VERSION ""

NS_ :

BS_:

BU_: EOCM2B_IMX6_HS EOCM2A_IMX6_HS EOCM2B_K2_HS EOCM2A_K2_HS TTPM_HS AMM_HS EBOOST_OBD_HS CGM_HS BSM_HS HCP_B_HS AVM_HS PFAF_HS LVMPC_HS DCDC_HS DEFC_HS VPM_HS IPC_HS V2V_HS TCP_HS CSM_HS EOCM2B_K1_HS EOCM2A_K1_HS TRCM_HS ESCM_SP_HS ICCM_B_HS AMP_HS FICM_HS ARS_HS MCP_B_HS MCP_A_HS ICCM_OBD_HS SAS_HS ACCM_HS VLBS_HS EBCM_OBD_HS HCP_T_HS EDI_HS PLCM_HS VITM_OBD_HS VICM_HS HCP_HS APPS_HS ICCM_HS EOCM_F_HS GPCM_HS VCM_HS HMIM_HS VES_HS Dummy_HS MCP_C_HS ONSTAR_HS EPS_HS TestTool_HS MCP_HS BCP_HS ALC_HS AHL_AFL_HS SADS_HS EPB_HS FCM_HS TCCM_HS RDCM_HS PTO_HS EBCM_HS ACC_HS BCM_HS TCM_HS ECM_HS

VAL_TABLE_ vt_BooleanValues 1 "true" 0 "false" ;
VAL_TABLE_ BrkSysVTopSpdLimRqTp 3 "Unused and Reserved 2" 2 "Unused and Reserved 1" 1 "OBD" 0 "Inactive" ;
VAL_TABLE_ HzrdLmpActReqd 2 "Activate" 1 "Deactivate" 0 "No Action" ;
VAL_TABLE_ MtrBInvSt 7 "Unused and Reserved 3" 6 "Unused and Reserved 2" 5 "High Voltage Required" 4 "Unused and Reserved 1" 3 "Power Stage On: Active Discharge" 2 "Power Stage On: Shutdown Pending" 1 "Power Stage Active" 0 "Power Stage Inactive" ;
VAL_TABLE_ ValidityStates 1 "Invalid" 0 "Valid" ;
VAL_TABLE_ MtrAInvSt 7 "Unused and Reserved 3" 6 "Unused and Reserved 2" 5 "High Voltage Required" 4 "Unused and Reserved 1" 3 "Power Stage On: Active Discharge" 2 "Power Stage On: Shutdown Pending" 1 "Power Stage Active" 0 "Power Stage Inactive" ;
VAL_TABLE_ PrkHtrOffTmM 1 "Use Data" 0 "Dont Use Data" ;
VAL_TABLE_ PrkHtrCoolntTempMsk 1 "Use Data" 0 "Don't Use Data" ;
VAL_TABLE_ PrkHtrActvTmM 1 "Use Data" 0 "Dont Use Data" ;
VAL_TABLE_ CbnHtrWrmUpReq 3 "Warm Up Level 3" 2 "Warm Up Level 2" 1 "Warm Up Level 1" 0 "None" ;
VAL_TABLE_ ElcTrnsRngSelPrkSysStat 7 "Unused and Reserved 4" 6 "Unused and Reserved 3" 5 "Unused and Reserved 2" 4 "Unused and Reserved 1" 3 "Out Of Park" 2 "Transitional 1" 1 "Park" 0 "Unknown" ;
VAL_TABLE_ ClmCntHtrMinFlwRtRqVDA 1 "VirtualDeviceAvailable" 0 "VirtualDeviceUnavailable" ;
VAL_TABLE_ CCClntCrcFlwRtReqVDA 1 "VirtualDeviceAvailable" 0 "VirtualDeviceUnavailable" ;
VAL_TABLE_ CGMDS2_DTCStat 7 "Unused and Reserved3" 6 "Unused and Reserved2" 5 "Unused and Reserved1" 4 "Diagnostic Failed" 3 "Diagnostic Passed" 2 "No Status to Report" 1 "Critically Disabled" 0 "Not Supported" ;
VAL_TABLE_ CGMDS1_DTCStat 7 "Unused and Reserved3" 6 "Unused and Reserved2" 5 "Unused and Reserved1" 4 "Diagnostic Failed" 3 "Diagnostic Passed" 2 "No Status to Report" 1 "Critically Disabled" 0 "Not Supported" ;
VAL_TABLE_ CGMCII_DataIndx 31 "Unused and Reserved12" 30 "Unused and Reserved11" 29 "Unused and Reserved10" 28 "Unused and Reserved9" 27 "Unused and Reserved8" 26 "Unused and Reserved7" 25 "Unused and Reserved6" 24 "Unused and Reserved5" 23 "Unused and Reserved4" 22 "Unused and Reserved3" 21 "Unused and Reserved2" 20 "Unused and Reserved1" 19 "CVN Digit 4" 18 "CVN Digit 3" 17 "CVN Digit 2" 16 "CVN Digit 1" 15 "Calibration Identification Digit 16" 14 "Calibration Identification Digit 15" 13 "Calibration Identification Digit 14" 12 "Calibration Identification Digit 13" 11 "Calibration Identification Digit 12" 10 "Calibration Identification Digit 11" 9 "Calibration Identification Digit 10" 8 "Calibration Identification Digit 9" 7 "Calibration Identification Digit 8" 6 "Calibration Identification Digit 7" 5 "Calibration Identification Digit 6" 4 "Calibration Identification Digit 5" 3 "Calibration Identification Digit 4" 2 "Calibration Identification Digit 3" 1 "Calibration Identification Digit 2" 0 "Calibration Identification Digit 1" ;
VAL_TABLE_ CGMCII_DataStat 1 "Data Available" 0 "Data Not Available" ;
VAL_TABLE_ RdHVBatHtrCntctrStat 2 "Closed" 1 "Unused and Reserved" 0 "Open" ;
VAL_TABLE_ RdDCChrgCntctrStat 2 "Closed" 1 "Precharge" 0 "Open" ;
VAL_TABLE_ TrlrTrPrsSlLrnModeFdbkHrnReq 2 "Cancel Horn" 1 "Active" 0 "No Action" ;
VAL_TABLE_ TrlrTrPrsOvrgFdbkHrnReq 2 "Cancel Horn" 1 "Active" 0 "No Action" ;
VAL_TABLE_ TrlrTrPrsAdjmtErrFdbkHrnReq 2 "Cancel Horn" 1 "Active" 0 "No Action" ;
VAL_TABLE_ TrlrTrPrsAchvdFdbkHrnReq 2 "Cancel Horn" 1 "Active" 0 "No Action" ;
VAL_TABLE_ TrlrTrLrnStat 3 "Tires Not Learned" 2 "Learn Failed" 1 "Learn Progressing" 0 "Learn Completed" ;
VAL_TABLE_ TrlrTrLrnScsflFdbkHrnReq 2 "Cancel Horn" 1 "Active" 0 "No Action" ;
VAL_TABLE_ TrlrTrLrnModeFdbkHrnReq 2 "Cancel Horn" 1 "Active" 0 "No Action" ;
VAL_TABLE_ TrlrTrLrngAlLmpFlshFdbkReq 3 "Cancel Lights" 2 "Flash" 1 "Flash Once" 0 "No Action" ;
VAL_TABLE_ TrlrPrfDltn 5 "Profile 5 Deleted" 4 "Profile 4 Deleted" 3 "Profile 3 Deleted" 2 "Profile 2 Deleted" 1 "Profile 1 Deleted" 0 "No Profile Deleted" ;
VAL_TABLE_ TrlrTrRtRrPrsStat 8 "High Temp" 7 "High Pressure" 6 "Tire Learning Complete" 5 "Learn Tire" 4 "Learning in Progress" 3 "Malfunction" 2 "Low Pressure" 1 "Normal" 0 "Unknown" ;
VAL_TABLE_ TrlrTrRtFrtPrsStat 8 "High Temp" 7 "High Pressure" 6 "Tire Learning Complete" 5 "Learn Tire" 4 "Learning in Progress" 3 "Malfunction" 2 "Low Pressure" 1 "Normal" 0 "Unknown" ;
VAL_TABLE_ TrlrRtMdlPrsStat 8 "High Temp" 7 "High Pressure" 6 "Tire Learning Complete" 5 "Learn Tire" 4 "Learning in Progress" 3 "Malfunction" 2 "Low Pressure" 1 "Normal" 0 "Unknown" ;
VAL_TABLE_ TrlrTrLfRrPrsStat 8 "High Temp" 7 "High Pressure" 6 "Tire Learning Complete" 5 "Learn Tire" 4 "Learning in Progress" 3 "Malfunction" 2 "Low Pressure" 1 "Normal" 0 "Unknown" ;
VAL_TABLE_ TrlrTrLfMdlPrsStat 8 "High Temp" 7 "High Pressure" 6 "Tire Learning Complete" 5 "Learn Tire" 4 "Learning In Progress" 3 "Malfunction" 2 "Low Pressure" 1 "Normal" 0 "Unknown" ;
VAL_TABLE_ TrlrTrLfFrtPrsStat 8 "High Temp" 7 "High Pressure" 6 "Tire Learning Complete" 5 "Learn Tire" 4 "Learning In Progress" 3 "Malfunction" 2 "Low Pressure" 1 "Normal" 0 "Unknown" ;
VAL_TABLE_ TrlrProfSel 5 "Profile 5" 4 "Profile 4" 3 "Profile 3" 2 "Profile 2" 1 "Profile 1" 0 "Default Profile" ;
VAL_TABLE_ TrlrBrkProfStat 1 "Inactive" 0 "Active" ;
VAL_TABLE_ TrlrStTwHlMdOvrd 3 "Unused and Reserved 2" 2 "Unused and Reserved 1" 1 "Override to Not Tow Haul" 0 "No Override" ;
VAL_TABLE_ TransStCrwlMdOvrrd 3 "Unused And Reserved" 2 "Override To Crawl" 1 "Override To Not Crawl" 0 "No Override" ;
VAL_TABLE_ CrwlModeDndRsnIndReq 4 "Reduce Speed" 3 "Shift To 4 High" 2 "Brakes Overtemp" 1 "Unavailable" 0 "No Action" ;
VAL_TABLE_ BrkSysStCrwlModeOvrrd 3 "Unused And Reserved" 2 "Override To Crawl" 1 "Override To Not Crawl" 0 "No Override" ;
VAL_TABLE_ PAMS_SwStat 7 "Critical Analog Fault" 6 "Unused and Reserved 2" 5 "Unused and Reserved 1" 4 "Switch 4 Active" 3 "Switch 3 Active" 2 "Switch 2 Active" 1 "Switch 1 Active" 0 "No Active Switches" ;
VAL_TABLE_ ClmCntPrtyHtngRq 3 "HIGH" 2 "MEDIUM" 1 "LOW" 0 "NO ACTION" ;
VAL_TABLE_ RrAxlLckFdbk 2 "Unknown" 1 "Locked" 0 "Open" ;
VAL_TABLE_ AxlLckUnavailIndReq 7 "Unused And Reserved 2" 6 "Unused And Reserved 1" 5 "Generic Unavailable" 4 "Not During Hill Decent" 3 "Speed Too High" 2 "Not In 4 WD Low" 1 "Rear Axle Not Locked" 0 "No Action" ;
VAL_TABLE_ FrntAxlLckFdbk 2 "Unknown" 1 "Locked" 0 "Open" ;
VAL_TABLE_ EngIntAirTmpM 1 "Use Data" 0 "Dont Use Data" ;
VAL_TABLE_ RdHVCntctrShdwnCmd 4 "Normal Shutdown" 3 "Emergency Crash Shutdown" 2 "Controlled Shutdown" 1 "Emergency Shutdown" 0 "None" ;
VAL_TABLE_ RdChrgrCntctrStatus 2 "Closed" 1 "Precharge" 0 "Open" ;
VAL_TABLE_ CCFrBlwFnSpdFbkORLFS 2 "Fail" 1 "Pass" 0 "Indeterminate" ;
VAL_TABLE_ CCFrBlwFnSpdFbkORHFS 2 "Fail" 1 "Pass" 0 "Indeterminate" ;
VAL_TABLE_ TransTempOpRgn 7 "Unused and Reserved 3" 6 "Unused and Reserved 2" 5 "Unused and Reserved 1" 4 "Reliability Degraded" 3 "Operation Degraded" 2 "High Efficiency" 1 "Low Efficiency" 0 "Unknown" ;
VAL_TABLE_ TransOilTempAltValM 1 "Use Data" 0 "Dont Use Data" ;
VAL_TABLE_ FourWhlDrvIdReqExtRng 15 "Front Wheel Drive Mode Active" 14 "Front Wheel Drive Mode Pending" 13 "AWD Connected Mode Active" 12 "AWD Connected Mode Pending" 11 "Position Undetermined Active" 10 "Transfer Case Neutral Active" 9 "Transfer Case Neutral Pending" 8 "Four Wheel Drive Low Lock Active" 7 "Four Wheel Drive Low Lock Pending" 6 "Four Wheel Drive High Lock Active" 5 "Four Wheel Drive High Lock Pending" 4 "Four Wheel Drive High Auto Active" 3 "Four Wheel Drive High Auto Pending" 2 "Two Wheel Drive High Active" 1 "Two Wheel Drive High Pending" 0 "No Indication" ;
VAL_TABLE_ BrkPdLfSysDrvrRq 4 "Reset Rear" 3 "Reset Front" 2 "Enable" 1 "Disable" 0 "No Action" ;
VAL_TABLE_ BrkPdLfStatIndRq 5 "Service" 4 "Disabled" 3 "Change Now" 2 "Change Soon" 1 "Ok" 0 "Not Present" ;
VAL_TABLE_ BrkPdLfRrDstWrnIndRq 2 "Display Distance" 1 "Low" 0 "No Action" ;
VAL_TABLE_ BrkPdLfFrtDstWrnIndRq 2 "Display Distance" 1 "Low" 0 "No Action" ;
VAL_TABLE_ AutoVehMdSelctIntrStat 3 "Mode Request Denied" 2 "Disabled" 1 "Enabled" 0 "No Action" ;
VAL_TABLE_ AVMC_MdReqstd 31 "Critically Disabled" 30 "No Mode Change Requested" 29 "Unused and Reserved 16" 28 "Unused and Reserved 15" 27 "Unused and Reserved 14" 26 "Unused and Reserved 13" 25 "Unused and Reserved 12" 24 "Unused and Reserved 11" 23 "Unused and Reserved 10" 22 "Unused and Reserved 9" 21 "Unused and Reserved 8" 20 "Unused and Reserved 7" 19 "Unused and Reserved 6" 18 "Unused and Reserved 5" 17 "Unused and Reserved 4" 16 "Unused and Reserved 3" 15 "Unused and Reserved 2" 14 "Unused and Reserved 1" 13 "Normal AWD" 12 "Exhaust Brake" 11 "Track" 10 "Speed Matching" 9 "Grade Braking Disable" 8 "Tow Haul" 7 "Start Stop" 6 "Snow Ice" 5 "Hold" 4 "Mountain" 3 "Eco" 2 "Chassis Sport" 1 "Powertrain Sport" 0 "Normal" ;
VAL_TABLE_ EngAirFltMonSt 7 "Unused and Reserved 3" 6 "Unused and Reserved 2" 5 "Unused and Reserved 1" 4 "Disabled" 3 "Fault Present" 2 "Replace Air Filter Now" 1 "Replace Air Filter Soon" 0 "Ok" ;
VAL_TABLE_ EngAirFltMonDrvrReq 3 "Reset" 2 "Disable" 1 "Enable" 0 "No Action" ;
VAL_TABLE_ FuelMdTrnstnIndReq 15 "Unused and Reserved 9" 14 "Unused and Reserved 8" 13 "Unused and Reserved 7" 12 "Unused and Reserved 6" 11 "Unused and Reserved 5" 10 "Unused and Reserved 4" 9 "Unused and Reserved 3" 8 "Unused and Reserved 2" 7 "Unused and Reserved 1" 6 "Indication 6" 5 "Indication 5" 4 "Indication 4" 3 "Indication 3" 2 "Indication 2" 1 "Indication 1" 0 "No Indication" ;
VAL_TABLE_ BiFuelRflGaslinIndReq 7 "Unused and Reserved 5" 6 "Unused and Reserved 4" 5 "Unused and Reserved 3" 4 "Unused and Reserved 2" 3 "Unused and Reserved 1" 2 "Indication 2" 1 "Indication 1" 0 "No Indication" ;
VAL_TABLE_ SmrtHgBmAstCstCurrSetVal 7 "Unused and Reserved 5" 6 "Unused and Reserved 4" 5 "Unused and Reserved 3" 4 "Unused and Reserved 2" 3 "Unused and Reserved 1" 2 "Adaptive High Beam" 1 "Auto High Beam" 0 "No Action" ;
VAL_TABLE_ ACCAxlTrqReqStat 7 "Unused and Reserved 3" 6 "Unused and Reserved 2" 5 "Unused and Reserved 1" 4 "Request Suspended Until Driver Input" 3 "Request Denied" 2 "Lost Arbitration" 1 "Request Honored" 0 "No Request" ;
VAL_TABLE_ ElcShfPriTwoGrsSlInRq 3 "Drive Indication" 2 "Neutral Indication" 1 "Park Indication" 0 "No Indication" ;
VAL_TABLE_ VehStbEnhmntCurStRq 2 "On" 1 "Off" 0 "No Action" ;
VAL_TABLE_ VehStbEnhmntCurSt 1 "On" 0 "Off" ;
VAL_TABLE_ VehStbCmptvMdCurStRq 2 "On" 1 "Off" 0 "No Action" ;
VAL_TABLE_ VehStbCmptvMdCurSt 1 "On" 0 "Off" ;
VAL_TABLE_ TracAndStbScrnCnfg 3 "TCS ESC and Comp" 2 "TCS and ESC" 1 "TCS Only" 0 "None" ;
VAL_TABLE_ TCSysCurStReq 2 "On" 1 "Off" 0 "No Action" ;
VAL_TABLE_ TCSysCurSt 1 "On" 0 "Off" ;
VAL_TABLE_ TCSTmpSysDsblReqConf 2 "Yes" 1 "No" 0 "No Action" ;
VAL_TABLE_ SrndVisVltgStat 3 "Not Used" 2 "Out Of Range Low" 1 "Out Of Range High" 0 "In Range" ;
VAL_TABLE_ SrndVisTempStat 3 "Not Used" 2 "Out Of Range Low" 1 "Out Of Range High" 0 "In Range" ;
VAL_TABLE_ RghtLnMrkTyp 7 "Triple Line" 6 "Double Line" 5 "Road Edge" 4 "Virtual" 3 "Botts Dots" 2 "Dashed" 1 "Solid" 0 "Unknown" ;
VAL_TABLE_ RghtLnMrkConf 3 "High" 2 "Medium" 1 "Low 2" 0 "Low 1" ;
VAL_TABLE_ RghtLnMrkClr 7 "Unusued and Reserved 3" 6 "Unusued and Reserved 2" 5 "Unusued and Reserved 1" 4 "Blue" 3 "Red or Orange" 2 "Yellow" 1 "White" 0 "Unknown" ;
VAL_TABLE_ LnSensMdStat 1 "Sensing" 0 "Not Sensing" ;
VAL_TABLE_ LftLnMrkTyp 7 "Triple Line" 6 "Double Line" 5 "Road Edge" 4 "Virtual" 3 "Botts Dots" 2 "Dashed" 1 "Solid" 0 "Unknown" ;
VAL_TABLE_ LftLnMrkConf 3 "High" 2 "Medium" 1 "Low 2" 0 "Low 1" ;
VAL_TABLE_ LftLnMrkClr 7 "Unusued and Reserved 3" 6 "Unusued and Reserved 2" 5 "Unusued and Reserved 1" 4 "Blue" 3 "Red or Orange" 2 "Yellow" 1 "White" 0 "Unknown" ;
VAL_TABLE_ RTXCorrctnEnbl 1 "Enabled" 0 "Disabled" ;
VAL_TABLE_ PPSMd 7 "GNSS and RTX and DR and MM" 6 "DR ONLY" 5 "GNSS and RTX and DR" 4 "GNSS and SBAS and DR" 3 "GNSS and DR" 2 "GNSS and  RTX" 1 "GNSS and SBAS" 0 "GNSS Standalone" ;
VAL_TABLE_ DrvrDrOpenSwVDA 1 "Virtual Device Available" 0 "Virtual Device Unavailable" ;
VAL_TABLE_ DrvrDrAjrSwVDA 1 "Virtual Device Available" 0 "Virtual Device Unavailable" ;
VAL_TABLE_ TrnsEmisRlFrzFrmStrSt 3 "Reserved" 2 "Full" 1 "Pending" 0 "Empty" ;
VAL_TABLE_ RoadTypInfo 1 "Freeway" 0 "Non Freeway" ;
VAL_TABLE_ ESCMStrtStpStat 3 "Deactivated" 2 "Active" 1 "Inactive" 0 "Indeterminate" ;
VAL_TABLE_ ESCMSecPwrStat 3 "Deactivated" 2 "Active" 1 "Inactive" 0 "Indeterminate" ;
VAL_TABLE_ ESCMChrgSysSt 3 "Reserved" 2 "Discharging" 1 "Charging" 0 "Passive" ;
VAL_TABLE_ ABRS_BcupESCDatInpSt 1 "Failed" 0 "Normal" ;
VAL_TABLE_ ABRS_ACCAutBkRqPrBsSt 7 "Not Used 2" 6 "Not Used 1" 5 "Request Out Of Range" 4 "CAN Error" 3 "Failed" 2 "Limited" 1 "Active" 0 "Not Active" ;
VAL_TABLE_ ABRS_CIBAutBkRqScBsSt 7 "Not Used 2" 6 "Not Used 1" 5 "Request Out Of Range" 4 "CAN Error" 3 "Failed" 2 "Limited" 1 "Active" 0 "Not Active" ;
VAL_TABLE_ DTPWCPS_CrnkPrm 1 "Crank Permitted" 0 "Crank Not Permitted" ;
VAL_TABLE_ HybEstTransOilTmpM 1 "Use Data" 0 "Dont Use Data" ;
VAL_TABLE_ ACCSysSltdMd 3 "Unused And Reserved" 2 "Enhanced Cruise Control" 1 "Adaptive Cruise Control" 0 "Cruise Control Mode Switching Not Supported" ;
VAL_TABLE_ PTExPartFltManRegStat 7 "Unused and Reserved 2" 6 "Unused and Reserved 1" 5 "Pending Driver Input" 4 "Complete" 3 "In Progress" 2 "Not Allowed" 1 "Allowed" 0 "Cleaning Not Required" ;
VAL_TABLE_ TransCltch5CntlRq 3 "Locked" 2 "Passive Control" 1 "Active Control" 0 "No Control" ;
VAL_TABLE_ TransCltch4CntlRq 3 "Locked" 2 "Passive Control" 1 "Active Control" 0 "No Control" ;
VAL_TABLE_ TransCltch3CntlRq 3 "Locked" 2 "Passive Control" 1 "Active Control" 0 "No Control" ;
VAL_TABLE_ TransCltch2CntlRq 3 "Locked" 2 "Passive Control" 1 "Active Control" 0 "No Control" ;
VAL_TABLE_ TransCltch1CntlRq 3 "Locked" 2 "Passive Control" 1 "Active Control" 0 "No Control" ;
VAL_TABLE_ LnchCtrlWhlSlpStat 31 "Unused and Reserved 10" 30 "Unused and Reserved 9" 29 "Unused and Reserved 8" 28 "Unused and Reserved 7" 27 "Unused and Reserved 6" 26 "Unused and Reserved 5" 25 "Unused and Reserved 4" 24 "Unused and Reserved 3" 23 "Unused and Reserved 2" 22 "Unused and Reserved 1" 21 "Fifteen Percent" 20 "Fourteen And A Half Percent" 19 "Fourteen Percent" 18 "Thirteen And A Half Percent" 17 "Thirteen Percent" 16 "Twelve And A Half Percent" 15 "Twelve Percent" 14 "Eleven And a Half Percent" 13 "Eleven Percent" 12 "Ten And A Half Percent" 11 "Ten Percent" 10 "Nine And A Half Percent" 9 "Nine Percent" 8 "Eight And A Half Percent" 7 "Eight Percent" 6 "Seven And A Half Percent" 5 "Seven Percent" 4 "Six And A Half Percent" 3 "Six Percent" 2 "Five And A Half Percent" 1 "Five Percent" 0 "No Action" ;
VAL_TABLE_ LnchCtrlWhlSlpReq 31 "Unused and Reserved 10" 30 "Unused and Reserved 9" 29 "Unused and Reserved 8" 28 "Unused and Reserved 7" 27 "Unused and Reserved 6" 26 "Unused and Reserved 5" 25 "Unused and Reserved 4" 24 "Unused and Reserved 3" 23 "Unused and Reserved 2" 22 "Unused and Reserved 1" 21 "Fifteen Percent" 20 "Fourteen And A Half Percent" 19 "Fourteen Percent" 18 "Thirteen And A Half Percent" 17 "Thirteen Percent" 16 "Twelve And A Half Percent" 15 "Twelve Percent" 14 "Eleven And a Half Percent" 13 "Eleven Percent" 12 "Ten And A Half Percent" 11 "Ten Percent" 10 "Nine And A Half Percent" 9 "Nine Percent" 8 "Eight And A Half Percent" 7 "Eight Percent" 6 "Seven And A Half Percent" 5 "Seven Percent" 4 "Six And A Half Percent" 3 "Six Percent" 2 "Five And A Half Percent" 1 "Five Percent" 0 "No Action" ;
VAL_TABLE_ LnchCtrlMdStat 7 "Line Lock Release Brake" 6 "Line Lock Press Brake" 5 "Burn Out Or Line Lock" 4 "High Traction Custom" 3 "High Traction" 2 "General Custom" 1 "General" 0 "Disable" ;
VAL_TABLE_ LnchCtrlMdReq 3 "Burn Out" 2 "Custom" 1 "Automatic" 0 "No Action" ;
VAL_TABLE_ LnchCtrlEngRPMStat 0 "No Action" 63 "Unused and Reserved 30" 62 "Unused and Reserved 29" 61 "Unused and Reserved 28" 60 "Unused and Reserved 27" 59 "Unused and Reserved 26" 58 "Unused and Reserved 25" 57 "Unused and Reserved 24" 56 "Unused and Reserved 23" 55 "Unused and Reserved 22" 54 "Unused and Reserved 21" 53 "Unused and Reserved 20" 52 "Unused and Reserved 19" 51 "Unused and Reserved 18" 50 "Unused and Reserved 17" 49 "Unused and Reserved 16" 48 "Unused and Reserved 15" 47 "Unused and Reserved 14" 46 "Unused and Reserved 13" 45 "Unused and Reserved 12" 44 "Unused and Reserved 11" 43 "Unused and Reserved 10" 42 "Unused and Reserved 9" 41 "Unused and Reserved 8" 40 "Unused and Reserved 7" 39 "Unused and Reserved 6" 38 "Unused and Reserved 5" 37 "Unused and Reserved 4" 36 "Unused and Reserved 3" 35 "Unused and Reserved 2" 34 "Unused and Reserved 1" 33 "4000" 32 "3900" 31 "3800" 30 "3700" 29 "3600" 28 "3500" 27 "3400" 26 "3300" 25 "3200" 24 "3100" 23 "3000" 22 "2900" 21 "2800" 20 "2700" 19 "2600" 18 "2500" 17 "2400" 16 "2300" 15 "2200" 14 "2100" 13 "2000" 12 "1900" 11 "1800" 10 "1700" 9 "1600" 8 "1500" 7 "1400" 6 "1300" 5 "1200" 4 "1100" 3 "1000" 2 "900" 1 "800" ;
VAL_TABLE_ LnchCtrlEngRPMReq 63 "Unused and Reserved 30" 62 "Unused and Reserved 29" 61 "Unused and Reserved 28" 60 "Unused and Reserved 27" 59 "Unused and Reserved 26" 58 "Unused and Reserved 25" 57 "Unused and Reserved 24" 56 "Unused and Reserved 23" 55 "Unused and Reserved 22" 54 "Unused and Reserved 21" 53 "Unused and Reserved 20" 52 "Unused and Reserved 19" 51 "Unused and Reserved 18" 50 "Unused and Reserved 17" 49 "Unused and Reserved 16" 48 "Unused and Reserved 15" 47 "Unused and Reserved 14" 46 "Unused and Reserved 13" 45 "Unused and Reserved 12" 44 "Unused and Reserved 11" 43 "Unused and Reserved 10" 42 "Unused and Reserved 9" 41 "Unused and Reserved 8" 40 "Unused and Reserved 7" 39 "Unused and Reserved 6" 38 "Unused and Reserved 5" 37 "Unused and Reserved 4" 36 "Unused and Reserved 3" 35 "Unused and Reserved 2" 34 "Unused and Reserved 1" 33 "4000" 32 "3900" 31 "3800" 30 "3700" 29 "3600" 28 "3500" 27 "3400" 26 "3300" 25 "3200" 24 "3100" 23 "3000" 22 "2900" 21 "2800" 20 "2700" 19 "2600" 18 "2500" 17 "2400" 16 "2300" 15 "2200" 14 "2100" 13 "2000" 12 "1900" 11 "1800" 10 "1700" 9 "1600" 8 "1500" 7 "1400" 6 "1300" 5 "1200" 4 "1100" 3 "1000" 2 "900" 1 "800" 0 "No Action" ;
VAL_TABLE_ TrqOvrlStatSrc 7 "Unused And Reserved3" 6 "Unused And Reserved2" 5 "Unused And Reserved1" 4 "Secondary EOCM Secondary Network" 3 "Secondary EOCM Primary Network" 2 "Primary EOCM Secondary Network" 1 "Primary EOCM Primary Network" 0 "None" ;
VAL_TABLE_ StrngTrqOvrlTrqDStat 7 "EPS Override" 6 "Permanently Failed" 5 "Limited System Capability" 4 "Communication Error" 3 "Temporarily Limited" 2 "Deactivated" 1 "Active" 0 "Inactive" ;
VAL_TABLE_ HndsOffStrWhlDetmnStat 1 "Hands On" 0 "Hands Off" ;
VAL_TABLE_ HndsOffStrWhlDetmnMd 3 "Unused And Reserved" 2 "Failed" 1 "Enabled" 0 "Disabled" ;
VAL_TABLE_ EPSCmndTrqValFetr 7 "Unused and Reserved 2" 6 "Unused and Reserved 1" 5 "Reserved for Collision Imminent Steering" 4 "Steering Angle Assist" 3 "Reserved for LXC" 2 "Lane Centering Control" 1 "Lane Keep Assist" 0 "None" ;
VAL_TABLE_ EPSCmndCtlTyp 3 "Unused" 2 "Dual Overlay" 1 "Single Overlay" 0 "Inactive" ;
VAL_TABLE_ EPSCmdTrqReqAct 1 "Active" 0 "Inactive" ;
VAL_TABLE_ TARS_TransActRngM 1 "Use Data" 0 "Do not Use Data" ;
VAL_TABLE_ TARS_TransActRng 15 "Unused and Reserved2" 14 "Unused and Reserved1" 13 "Fourth Drive Position" 12 "Between Third and Fourth Drive position" 11 "Third Drive Position" 10 "Between Second and Third Drive position" 9 "Second Drive Position" 8 "Between First and Second Drive position" 7 "First Drive Position" 6 "Between Neutral and First Drive position" 5 "Neutral Position" 4 "Between Reverse and Neutral" 3 "Reverse Position" 2 "Between Park and Reverse" 1 "Park Position" 0 "Unknown Position" ;
VAL_TABLE_ PRS_PTRlyCmdSt 1 "Relay On" 0 "Relay Off" ;
VAL_TABLE_ ChrgSysAudblIndRq 7 "Unused and Reserved3" 6 "Unused and Reserved2" 5 "Unused and Reserved1" 4 "Sequence 4" 3 "Sequence 3" 2 "Sequence 2" 1 "Sequence 1" 0 "Inactive" ;
VAL_TABLE_ EngPstnSnsngOpMode 2 "CAM Failed" 1 "Crank Failed" 0 "Normal" ;
VAL_TABLE_ EASSI_StrtTyp 7 "Type G" 6 "Type F" 5 "Type E" 4 "Type D" 3 "Type C" 2 "Type B" 1 "Type A" 0 "No Start" ;
VAL_TABLE_ EASSI_StrtStpSt 3 "Engine Stopping" 2 "Engine Starting" 1 "Engine Running" 0 "Engine Off" ;
VAL_TABLE_ TEPI_TrnsEngdPrFlwSt 7 "Unused and Reserved4" 6 "Unused and Reserved3" 5 "Unused and Reserved2" 4 "Unused and Reserved1" 3 "Reverse Engaged" 2 "Drive Engaged" 1 "No Powerflow" 0 "Unavailable " ;
VAL_TABLE_ ElcTransRngRq 7 "Unused and Reserved" 6 "Manual Range" 5 "Low Range" 4 "Drive" 3 "Neutral" 2 "Reverse" 1 "Park" 0 "No Request" ;
VAL_TABLE_ ESBR_AutoBrkgRqTyp 3 "Unused and Reserved" 2 "Hold Deny Driver Release" 1 "Hold Allow Driver Release" 0 "Release" ;
VAL_TABLE_ ESBR_AutoBrkgRqd 1 "Braking Requested" 0 "Braking Not Requested " ;
VAL_TABLE_ PndgTrnsfrCsRngShft 3 "Shift Out of Neutral Range" 2 "Shift Out of Low Range" 1 "Shift Out of High Range" 0 "None" ;
VAL_TABLE_ EngDetPndTrnCsRngShf 3 "Shift Out of Neutral Range" 2 "Shift Out of Low Range" 1 "Shift Out of High Range" 0 "None" ;
VAL_TABLE_ ElecShfRngDisp 15 "Unused and Reserved 3" 14 "Unused and Reserved 2" 13 "Unused and Reserved 1" 12 "Park Requested And Denied" 11 "Drive Requested And In Progress" 10 "Neutral Requested And In Progress" 9 "Reverse Requested And In Progress" 8 "Park Requested And In Progress" 7 "Reserved" 6 "Manual Nominal" 5 "Low Nominal" 4 "Drive Nominal" 3 "Neutral Nominal" 2 "Reverse Nominal" 1 "Park Nominal" 0 "No Display " ;
VAL_TABLE_ AVHSwtchStats 1 "Active" 0 "Not Active" ;
VAL_TABLE_ ThrmlRefCompStatFdbck 3 "Invalid" 2 "Inoperative" 1 "Degraded Operation" 0 "Normal Operation" ;
VAL_TABLE_ ManTransIndReq 3 "Indication 3" 2 "Indication 2" 1 "Indication 1" 0 "No Indication" ;
VAL_TABLE_ BCS2ERDTC_SysDesigntr 15 "U3-Network Codes Reserved" 14 "U2-Network Codes Reserved" 13 "U1-Network Codes MFG Controlled" 12 "U0-Network Codes SAE Controlled" 11 "B3-Body Codes Reserved" 10 "B2-Body Codes Reserved" 9 "B1-Body Codes MFG Controlled" 8 "B0-Body Codes SAE Controlled" 7 "C3-Chassis Codes Reserved" 6 "C2-Chassis Codes Reserved" 5 "C1-Chassis Codes MFG Controlled" 4 "C0-Chassis Codes SAE Controlled" 3 "P3-Powertrain Codes Reserved" 2 "P2-Powertrain Codes Reserved" 1 "P1-Powertrain Codes MFG Controlled" 0 "P0-Powertrain Codes SAE Controlled" ;
VAL_TABLE_ BCS1ERDTC_SysDesigntr 15 "U3-Network Codes Reserved" 14 "U2-Network Codes Reserved" 13 "U1-Network Codes MFG Controlled" 12 "U0-Network Codes SAE Controlled" 11 "B3-Body Codes Reserved" 10 "B2-Body Codes Reserved" 9 "B1-Body Codes MFG Controlled" 8 "B0-Body Codes SAE Controlled" 7 "C3-Chassis Codes Reserved" 6 "C2-Chassis Codes Reserved" 5 "C1-Chassis Codes MFG Controlled" 4 "C0-Chassis Codes SAE Controlled" 3 "P3-Powertrain Codes Reserved" 2 "P2-Powertrain Codes Reserved" 1 "P1-Powertrain Codes MFG Controlled" 0 "P0-Powertrain Codes SAE Controlled" ;
VAL_TABLE_ TIDCTR_TrqIntvTyp 3 "Reserved" 2 "Minimum Limit" 1 "Maximum Limit" 0 "No Request" ;
VAL_TABLE_ TIDCTR_TrqRespTyp 3 "Automatic Actuator Selection" 2 "Maximum Range" 1 "Pleasability Limited" 0 "Inactive" ;
VAL_TABLE_ ExtHlStrAssCsStRq 2 "Standard Hold" 1 "Extended Hold" 0 "No Action" ;
VAL_TABLE_ ExtHlStrAssCsCrStVal 2 "Standard Hold" 1 "Extended Hold" 0 "No Action" ;
VAL_TABLE_ BSMCT_Mult 3 "Multiplier Factor 256" 2 "Multiplier Factor 64" 1 "Multiplier Factor 8" 0 "Multiplier Factor 1" ;
VAL_TABLE_ CDP_HVDevShtdnCdARCSt 2 "Indeterminate" 1 "Fault" 0 "No Fault" ;
VAL_TABLE_ CDP_CmpSpdReqARCSt 2 "Indeterminate" 1 "Fault" 0 "No Fault" ;
VAL_TABLE_ CDSP_CmpOvrTmpSt 2 "Indeterminate" 1 "Fault" 0 "No Fault" ;
VAL_TABLE_ CDSP_CmpHVAbnrlOrVltSt 2 "Indeterminate" 1 "Fault" 0 "No Fault" ;
VAL_TABLE_ CDSP_CmpHVUndrVltgSt 2 "Indeterminate" 1 "Fault" 0 "No Fault" ;
VAL_TABLE_ CDSP_CmpHVOvrVltgSt 2 "Indeterminate" 1 "Fault" 0 "No Fault" ;
VAL_TABLE_ CDSP_CmpHVOvrCrntSt 2 "Indeterminate" 1 "Fault" 0 "No Fault" ;
VAL_TABLE_ CDSP_CmpIntShdwnFltSt 2 "Indeterminate" 1 "Fault" 0 "No Fault" ;
VAL_TABLE_ CDSP_CmpIntRecblFltSt 2 "Indeterminate" 1 "Fault" 0 "No Fault" ;
VAL_TABLE_ CDSP_CmpOpOvrldSt 2 "Indeterminate" 1 "Fault" 0 "No Fault" ;
VAL_TABLE_ CDSP_CmpDrCrctFltSt 2 "Indeterminate" 1 "Fault" 0 "No Fault" ;
VAL_TABLE_ CDSP_CmpMtrPerfFltSt 2 "Indeterminate" 1 "Fault" 0 "No Fault" ;
VAL_TABLE_ CDSP_CmpEEPROMFltSt 2 "Indeterminate" 1 "Fault" 0 "No Fault" ;
VAL_TABLE_ CDSP_CmpROMFltSt 2 "Indeterminate" 1 "Fault" 0 "No Fault" ;
VAL_TABLE_ CDSP_CmpRAMFltSt 2 "Indeterminate" 1 "Fault" 0 "No Fault" ;
VAL_TABLE_ CSSP_CmpIGBTTpOtRgLSt 2 "Indeterminate" 1 "Fault" 0 "No Fault" ;
VAL_TABLE_ CSSP_CmpIGBTTpOtRgHSt 2 "Indeterminate" 1 "Fault" 0 "No Fault" ;
VAL_TABLE_ CSSP_CmpCPUTmpOtRgLSt 2 "Indeterminate" 1 "Fault" 0 "No Fault" ;
VAL_TABLE_ CSSP_CmpCPUTmpOtRgHSt 2 "Indeterminate" 1 "Fault" 0 "No Fault" ;
VAL_TABLE_ CSSP_CmpHVSnsOtRgLSt 2 "Indeterminate" 1 "Fault" 0 "No Fault" ;
VAL_TABLE_ CSSP_CmpHVSnsOtRgHSt 2 "Indeterminate" 1 "Fault" 0 "No Fault" ;
VAL_TABLE_ CSSP_CmpPhCrntOtRgLSt 2 "Indeterminate" 1 "Fault" 0 "No Fault" ;
VAL_TABLE_ CSSP_CmpPhCrntOtRgHSt 2 "Indeterminate" 1 "Fault" 0 "No Fault" ;
VAL_TABLE_ PrtdEPBSwStat 3 "Active" 2 "Apply" 1 "Release" 0 "Not Active" ;
VAL_TABLE_ EBrkAstStat 7 "Faulted" 6 "Temporarily Failed" 5 "Reduced" 4 "Standalone" 3 "PostRun Reduced" 2 "Normal" 1 "Initializing" 0 "Not Initialized" ;
VAL_TABLE_ AdptCruzCtrlStg 7 "Performance Mode 7" 6 "Performance Mode 6" 5 "Performance Mode 5" 4 "Performance Mode 4" 3 "Performance Mode 3" 2 "Performance Mode 2" 1 "Performance Mode 1" 0 "No Action" ;
VAL_TABLE_ GFHBObjDirTrk8 1 "Ahead Traffic" 0 "Incoming Traffic" ;
VAL_TABLE_ GFHBObjDirTrk7 1 "Ahead Traffic" 0 "Incoming Traffic" ;
VAL_TABLE_ GFHBObjDirTrk6 1 "Ahead Traffic" 0 "Incoming Traffic" ;
VAL_TABLE_ GFHBObjDirTrk5 1 "Ahead Traffic" 0 "Incoming Traffic" ;
VAL_TABLE_ GFHBObjDirTrk4 1 "Ahead Traffic" 0 "Incoming Traffic" ;
VAL_TABLE_ GFHBObjDirTrk3 1 "Ahead Traffic" 0 "Incoming Traffic" ;
VAL_TABLE_ GFHBObjDirTrk2 1 "Ahead Traffic" 0 "Incoming Traffic" ;
VAL_TABLE_ GFHBObjDirTrk1 1 "Ahead Traffic" 0 "Incoming Traffic" ;
VAL_TABLE_ GFHBFwVsnRelLaneTrk8 3 "Left Lane" 2 "Right Lane" 1 "Host Lane" 0 "Unknown" ;
VAL_TABLE_ GFHBFwVsnRelLaneTrk7 3 "Left Lane" 2 "Right Lane" 1 "Host Lane" 0 "Unknown" ;
VAL_TABLE_ GFHBFwVsnRelLaneTrk6 3 "Left Lane" 2 "Right Lane" 1 "Host Lane" 0 "Unknown" ;
VAL_TABLE_ GFHBFwVsnRelLaneTrk5 3 "Left Lane" 2 "Right Lane" 1 "Host Lane" 0 "Unknown" ;
VAL_TABLE_ GFHBFwVsnRelLaneTrk4 3 "Left Lane" 2 "Right Lane" 1 "Host Lane" 0 "Unknown" ;
VAL_TABLE_ GFHBFwVsnRelLaneTrk3 3 "Left Lane" 2 "Right Lane" 1 "Host Lane" 0 "Unknown" ;
VAL_TABLE_ GFHBFwVsnRelLaneTrk2 3 "Left Lane" 2 "Right Lane" 1 "Host Lane" 0 "Unknown" ;
VAL_TABLE_ GFHBFwVsnRelLaneTrk1 3 "Left Lane" 2 "Right Lane" 1 "Host Lane" 0 "Unknown" ;
VAL_TABLE_ GFHBFwVsnMesStatTrk8 3 "Measured this cycle" 2 "Latent track not detected this cycle" 1 "New Object" 0 "No Object" ;
VAL_TABLE_ GFHBFwVsnMesStatTrk7 3 "Measured this cycle" 2 "Latent track not detected this cycle" 1 "New Object" 0 "No Object" ;
VAL_TABLE_ GFHBFwVsnMesStatTrk6 3 "Measured this cycle" 2 "Latent track not detected this cycle" 1 "New Object" 0 "No Object" ;
VAL_TABLE_ GFHBFwVsnMesStatTrk5 3 "Measured this cycle" 2 "Latent track not detected this cycle" 1 "New Object" 0 "No Object" ;
VAL_TABLE_ GFHBFwVsnMesStatTrk4 3 "Measured this cycle" 2 "Latent track not detected this cycle" 1 "New Object" 0 "No Object" ;
VAL_TABLE_ GFHBFwVsnMesStatTrk3 3 "Measured this cycle" 2 "Latent track not detected this cycle" 1 "New Object" 0 "No Object" ;
VAL_TABLE_ GFHBFwVsnMesStatTrk2 3 "Measured this cycle" 2 "Latent track not detected this cycle" 1 "New Object" 0 "No Object" ;
VAL_TABLE_ GFHBFwVsnMesStatTrk1 3 "Measured this cycle" 2 "Latent track not detected this cycle" 1 "New Object" 0 "No Object" ;
VAL_TABLE_ GFHBFwVsnCnfdncTrk8 3 "Confident" 2 "Speculative" 1 "Highly Speculative" 0 "Invalid" ;
VAL_TABLE_ GFHBFwVsnCnfdncTrk7 3 "Confident" 2 "Speculative" 1 "Highly Speculative" 0 "Invalid" ;
VAL_TABLE_ GFHBFwVsnCnfdncTrk6 3 "Confident" 2 "Speculative" 1 "Highly Speculative" 0 "Invalid" ;
VAL_TABLE_ GFHBFwVsnCnfdncTrk5 3 "Confident" 2 "Speculative" 1 "Highly Speculative" 0 "Invalid" ;
VAL_TABLE_ GFHBFwVsnCnfdncTrk4 3 "Confident" 2 "Speculative" 1 "Highly Speculative" 0 "Invalid" ;
VAL_TABLE_ GFHBFwVsnCnfdncTrk3 3 "Confident" 2 "Speculative" 1 "Highly Speculative" 0 "Invalid" ;
VAL_TABLE_ GFHBFwVsnCnfdncTrk2 3 "Confident" 2 "Speculative" 1 "Highly Speculative" 0 "Invalid" ;
VAL_TABLE_ GFHBFwVsnCnfdncTrk1 0 "Invalid" 3 "Confident" 2 "Speculative" 1 "Highly Speculative" ;
VAL_TABLE_ GFHBFVsnObjTypTrkRev8 12 "Cluster Object" 11 "Child Close to Danger Zone" 10 "Pedestrian Moving Out of Danger Zone" 9 "Pedestrian Moving Into Danger Zone" 8 "Pedestrian Standing Outside Danger Zone" 7 "No Object Present" 6 "Fixed Roadside Object" 5 "Fixed Overhead Object" 4 "Pedestrian" 3 "Motorcycle/ Bicycle" 2 "Large Vehicle (Semi)" 1 "4 Wheel Vehicle (Car)" 0 "Unknown" ;
VAL_TABLE_ GFHBFVsnObjTypTrkRev7 12 "Cluster Object" 11 "Child Close to Danger Zone" 10 "Pedestrian Moving Out of Danger Zone" 9 "Pedestrian Moving Into Danger Zone" 8 "Pedestrian Standing Outside Danger Zone" 7 "No Object Present" 6 "Fixed Roadside Object" 5 "Fixed Overhead Object" 4 "Pedestrian" 3 "Motorcycle/ Bicycle" 2 "Large Vehicle (Semi)" 1 "4 Wheel Vehicle (Car)" 0 "Unknown" ;
VAL_TABLE_ GFHBFVsnObjTypTrkRev6 12 "Cluster Object" 11 "Child Close to Danger Zone" 10 "Pedestrian Moving Out of Danger Zone" 9 "Pedestrian Moving Into Danger Zone" 8 "Pedestrian Standing Outside Danger Zone" 7 "No Object Present" 6 "Fixed Roadside Object" 5 "Fixed Overhead Object" 4 "Pedestrian" 3 "Motorcycle/ Bicycle" 2 "Large Vehicle (Semi)" 1 "4 Wheel Vehicle (Car)" 0 "Unknown" ;
VAL_TABLE_ GFHBFVsnObjTypTrkRev5 12 "Cluster Object" 11 "Child Close to Danger Zone" 10 "Pedestrian Moving Out of Danger Zone" 9 "Pedestrian Moving Into Danger Zone" 8 "Pedestrian Standing Outside Danger Zone" 7 "No Object Present" 6 "Fixed Roadside Object" 5 "Fixed Overhead Object" 4 "Pedestrian" 3 "Motorcycle/ Bicycle" 2 "Large Vehicle (Semi)" 1 "4 Wheel Vehicle (Car)" 0 "Unknown" ;
VAL_TABLE_ GFHBFVsnObjTypTrkRev4 12 "Cluster Object" 11 "Child Close to Danger Zone" 10 "Pedestrian Moving Out of Danger Zone" 9 "Pedestrian Moving Into Danger Zone" 8 "Pedestrian Standing Outside Danger Zone" 7 "No Object Present" 6 "Fixed Roadside Object" 5 "Fixed Overhead Object" 4 "Pedestrian" 3 "Motorcycle/ Bicycle" 2 "Large Vehicle (Semi)" 1 "4 Wheel Vehicle (Car)" 0 "Unknown" ;
VAL_TABLE_ GFHBFVsnObjTypTrkRev3 12 "Cluster Object" 11 "Child Close to Danger Zone" 10 "Pedestrian Moving Out of Danger Zone" 9 "Pedestrian Moving Into Danger Zone" 8 "Pedestrian Standing Outside Danger Zone" 7 "No Object Present" 6 "Fixed Roadside Object" 5 "Fixed Overhead Object" 4 "Pedestrian" 3 "Motorcycle/ Bicycle" 2 "Large Vehicle (Semi)" 1 "4 Wheel Vehicle (Car)" 0 "Unknown" ;
VAL_TABLE_ GFHBFVsnObjTypTrkRev2 12 "Cluster Object" 11 "Child Close to Danger Zone" 10 "Pedestrian Moving Out of Danger Zone" 9 "Pedestrian Moving Into Danger Zone" 8 "Pedestrian Standing Outside Danger Zone" 7 "No Object Present" 6 "Fixed Roadside Object" 5 "Fixed Overhead Object" 4 "Pedestrian" 3 "Motorcycle/ Bicycle" 2 "Large Vehicle (Semi)" 1 "4 Wheel Vehicle (Car)" 0 "Unknown" ;
VAL_TABLE_ GFHBFVsnObjTypTrkRev1 12 "Cluster Object" 11 "Child Close to Danger Zone" 10 "Pedestrian Moving Out of Danger Zone" 9 "Pedestrian Moving Into Danger Zone" 8 "Pedestrian Standing Outside Danger Zone" 7 "No Object Present" 6 "Fixed Roadside Object" 5 "Fixed Overhead Object" 4 "Pedestrian" 3 "Motorcycle/ Bicycle" 2 "Large Vehicle (Semi)" 1 "4 Wheel Vehicle (Car" 0 "Unknown" ;
VAL_TABLE_ SpdLmtrSttngTypAct 3 "Reserved" 2 "Auto" 1 "Manual" 0 "Off" ;
VAL_TABLE_ SetSpdLmtRchd 3 "Reserved" 2 "Low limit reached" 1 "High limit reached" 0 "No limit reached" ;
VAL_TABLE_ HybCrpCstCrvRq 7 "Creep Coast Curve 7" 6 "Creep Coast Curve 6" 5 "Creep Coast Curve 5" 4 "Creep Coast Curve 4" 3 "Creep Coast Curve 3" 2 "Creep Coast Curve 2" 1 "Creep Coast Curve 1" 0 "Creep Coast Curve 0" ;
VAL_TABLE_ CrpCstCrvCmd 7 "Creep Coast Curve 7" 6 "Creep Coast Curve 6" 5 "Creep Coast Curve 5" 4 "Creep Coast Curve 4" 3 "Creep Coast Curve 3" 2 "Creep Coast Curve 2" 1 "Creep Coast Curve 1" 0 "Creep Coast Curve 0" ;
VAL_TABLE_ RdGasFuelDevDisStat 3 "Reserved" 2 "Fault" 1 "Not Faulted" 0 "Indeterminate" ;
VAL_TABLE_ RdDistFuelMdReq 5 "Fault Transition Required" 4 "Fault Transition Requested" 3 "FICM" 2 "Dual" 1 "ECM" 0 "Indeterminate" ;
VAL_TABLE_ RdDistFuelMdCmdRes 3 "FICM" 2 "Dual" 1 "ECM" 0 "Indeterminate" ;
VAL_TABLE_ RdAltFuelSysStat 3 "Reserved" 2 "Fuel System Ready" 1 "Fuel System Priming" 0 "Fuel System Inactive" ;
VAL_TABLE_ RdDistFuelMdCmd 3 "FICM" 2 "Dual" 1 "ECM" 0 "Indeterminate" ;
VAL_TABLE_ PetrolFuelSysReqAval 3 "Not Available" 2 "Fault Transition Required" 1 "Fault Transition Requests" 0 "Available" ;
VAL_TABLE_ AltFuelInjHCmdLwRes 1 "FICM" 0 "ECM" ;
VAL_TABLE_ AltFuelInjGCmdLwRes 1 "FICM" 0 "ECM" ;
VAL_TABLE_ AltFuelInjFCmdLwRes 1 "FICM" 0 "ECM" ;
VAL_TABLE_ AltFuelInjECmdLwRes 1 "FICM" 0 "ECM" ;
VAL_TABLE_ AltFuelInjDCmdLwRes 1 "FICM" 0 "ECM" ;
VAL_TABLE_ AltFuelInjCCmdLwRes 1 "FICM" 0 "ECM" ;
VAL_TABLE_ AltFuelInjBCmdLwRes 1 "FICM" 0 "ECM" ;
VAL_TABLE_ AltFuelInjACmdLwRes 1 "FICM" 0 "ECM" ;
VAL_TABLE_ AdptPsngrSeatStng 7 "Performance Mode 7" 6 "Performance Mode 6" 5 "Performance Mode 5" 4 "Performance Mode 4" 3 "Performance Mode 3" 2 "Performance Mode 2" 1 "Performance Mode 1" 0 "No Action" ;
VAL_TABLE_ AdptDrvrSeatStng 7 "Performance Mode 7" 6 "Performance Mode 6" 5 "Performance Mode 5" 4 "Performance Mode 4" 3 "Performance Mode 3" 2 "Performance Mode 2" 1 "Performance Mode 1" 0 "No Action" ;
VAL_TABLE_ NAHrDisChrgM 1 "Use Data" 0 "Don't Use Data" ;
VAL_TABLE_ NAHrChgM 1 "Use Data" 0 "Don't Use Data" ;
VAL_TABLE_ MinCrnkCrntVltStat 1 "Use Data" 0 "Don't Use Data" ;
VAL_TABLE_ BattTempM 1 "Use Data" 0 "Don't Use Data" ;
VAL_TABLE_ BatVltHiResM 1 "Use Data" 0 "Don't Use Data" ;
VAL_TABLE_ BatCrntExtRngM 1 "Use Data" 0 "Don't Use Data" ;
VAL_TABLE_ CRL_Cnfdnc 7 "Reserved4" 6 "Reserved3" 5 "Reserved2" 4 "Reserved1" 3 "Best" 2 "Marking Present" 1 "Weak Marking" 0 "No Lane" ;
VAL_TABLE_ CLL_Cnfdnc 7 "Reserved4" 6 "Reserved3" 5 "Reserved2" 4 "Reserved1" 3 "Best" 2 "Marking Present" 1 "Weak Marking" 0 "No Lane" ;
VAL_TABLE_ PerfMdMainMenuType 7 "Reserved" 6 "Reserved" 5 "Reserved" 4 "Reserved" 3 "Main Menu Type 3" 2 "Main Menu Type 2" 1 "Main Menu Type 1" 0 "No Action" ;
VAL_TABLE_ PMVSS_Trans 7 "Visualization Type 7" 6 "Visualization Type 6" 5 "Visualization Type 5" 4 "Visualization Type 4" 3 "Visualization Type 3" 2 "Visualization Type 2" 1 "Visualization Type 1" 0 "No Action" ;
VAL_TABLE_ PMVSS_Susp 7 "Visualization Type 7" 6 "Visualization Type 6" 5 "Visualization Type 5" 4 "Visualization Type 4" 3 "Visualization Type 3" 2 "Visualization Type 2" 1 "Visualization Type 1" 0 "No Action" ;
VAL_TABLE_ PMVSS_Strng 7 "Visualization Type 7" 6 "Visualization Type 6" 5 "Visualization Type 5" 4 "Visualization Type 4" 3 "Visualization Type 3" 2 "Visualization Type 2" 1 "Visualization Type 1" 0 "No Action" ;
VAL_TABLE_ PMVSS_Snd 7 "Visualization Type 7" 6 "Visualization Type 6" 5 "Visualization Type 5" 4 "Visualization Type 4" 3 "Visualization Type 3" 2 "Visualization Type 2" 1 "Visualization Type 1" 0 "No Action" ;
VAL_TABLE_ PMVSS_PsngrSeat 7 "Visualization Type 7" 6 "Visualization Type 6" 5 "Visualization Type 5" 4 "Visualization Type 4" 3 "Visualization Type 3" 2 "Visualization Type 2" 1 "Visualization Type 1" 0 "No Action" ;
VAL_TABLE_ PMVSS_Exhst 7 "Visualization Type 7" 6 "Visualization Type 6" 5 "Visualization Type 5" 4 "Visualization Type 4" 3 "Visualization Type 3" 2 "Visualization Type 2" 1 "Visualization Type 1" 0 "No Action" ;
VAL_TABLE_ PMVSS_Eng 7 "Visualization Type 7" 6 "Visualization Type 6" 5 "Visualization Type 5" 4 "Visualization Type 4" 3 "Visualization Type 3" 2 "Visualization Type 2" 1 "Visualization Type 1" 0 "No Action" ;
VAL_TABLE_ PMVSS_DrvrSeat 7 "Visualization Type 7" 6 "Visualization Type 6" 5 "Visualization Type 5" 4 "Visualization Type 4" 3 "Visualization Type 3" 2 "Visualization Type 2" 1 "Visualization Type 1" 0 "No Action" ;
VAL_TABLE_ PMVSS_Drvln 7 "Visualization Type 7" 6 "Visualization Type 6" 5 "Visualization Type 5" 4 "Visualization Type 4" 3 "Visualization Type 3" 2 "Visualization Type 2" 1 "Visualization Type 1" 0 "No Action" ;
VAL_TABLE_ PMVSS_Disps 7 "Visualization Type 7" 6 "Visualization Type 6" 5 "Visualization Type 5" 4 "Visualization Type 4" 3 "Visualization Type 3" 2 "Visualization Type 2" 1 "Visualization Type 1" 0 "No Action" ;
VAL_TABLE_ PMVSS_AdptCrsCnt 7 "Visualization Type 7" 6 "Visualization Type 6" 5 "Visualization Type 5" 4 "Visualization Type 4" 3 "Visualization Type 3" 2 "Visualization Type 2" 1 "Visualization Type 1" 0 "No Action" ;
VAL_TABLE_ PsngStPerfMdCsStReq 7 "Auto" 6 "Performance Mode 6" 5 "Performance Mode 5" 4 "Performance Mode 4" 3 "Performance Mode 3" 2 "Performance Mode 2" 1 "Performance Mode 1" 0 "No Action" ;
VAL_TABLE_ PsngStPerfMdCsCrStVal 7 "Auto" 6 "Performance Mode 6" 5 "Performance Mode 5" 4 "Performance Mode 4" 3 "Performance Mode 3" 2 "Performance Mode 2" 1 "Performance Mode 1" 0 "No Action" ;
VAL_TABLE_ DrvrStPerfMdCsStReq 7 "Auto" 6 "Performance Mode 6" 5 "Performance Mode 5" 4 "Performance Mode 4" 3 "Performance Mode 3" 2 "Performance Mode 2" 1 "Performance Mode 1" 0 "No Action" ;
VAL_TABLE_ DrvrStPerfMdCsCrStVal 7 "Auto" 6 "Performance Mode 6" 5 "Performance Mode 5" 4 "Performance Mode 4" 3 "Performance Mode 3" 2 "Performance Mode 2" 1 "Performance Mode 1" 0 "No Action" ;
VAL_TABLE_ DrvStyPerfMdCsStReq 7 "Performance Mode 7" 6 "Performance Mode 6" 5 "Performance Mode 5" 4 "Performance Mode 4" 3 "Performance Mode 3" 2 "Performance Mode 2" 1 "Performance Mode 1" 0 "No Action" ;
VAL_TABLE_ DrvStyPerfMdCsCrStVal 7 "Performance Mode 7" 6 "Performance Mode 6" 5 "Performance Mode 5" 4 "Performance Mode 4" 3 "Performance Mode 3" 2 "Performance Mode 2" 1 "Performance Mode 1" 0 "No Action" ;
VAL_TABLE_ ACCPerfMdCsStReq 7 "Auto" 6 "Performance Mode 6" 5 "Performance Mode 5" 4 "Performance Mode 4" 3 "Performance Mode 3" 2 "Performance Mode 2" 1 "Performance Mode 1" 0 "No Action" ;
VAL_TABLE_ ACCPerfMdCsCrStVal 7 "Auto" 6 "Performance Mode 6" 5 "Performance Mode 5" 4 "Performance Mode 4" 3 "Performance Mode 3" 2 "Performance Mode 2" 1 "Performance Mode 1" 0 "No Action" ;
VAL_TABLE_ TCTPIR_DrvNotfn 15 "Indication 15" 14 "Indication 14" 13 "Indication 13" 12 "Indication 12" 11 "Indication 11" 10 "Indication 10" 9 "Indication 9" 8 "Indication 8" 7 "Indication 7" 6 "Indication 6" 5 "Indication 5" 4 "Indication 4" 3 "Indication 3" 2 "Indication 2" 1 "Indication 1" 0 "No Indication" ;
VAL_TABLE_ PltfrmEngSpdCmmndSt 3 "Request Denied" 2 "Lost Arbitration" 1 "Request Honored" 0 "No Request" ;
VAL_TABLE_ TrStPTGrdBrkDsMdOvr 3 "Unused and Reserved" 2 "To Grade Braking Disable" 1 "To Not Grade Braking Disable" 0 "No Override" ;
VAL_TABLE_ HiPresFuelPmpCntMd 6 "Zero Flow Mode" 5 "Noise Control Max Mode" 4 "Noise Control Disable Mode" 3 "Start Mode" 2 "Normal Mode" 1 "DFCO Mode" 0 "Disable Mode" ;
VAL_TABLE_ ClmtCtrlHtrEngRunRq 1 "Engine Run Requested" 0 "No Action" ;
VAL_TABLE_ TrnsStWntrMdOvrd 2 "Override To Winter" 1 "Override To Not Winter" 0 "No Override" ;
VAL_TABLE_ TrnsStTwHaulMdOvrd 2 "Override To Tow Haul" 1 "Override To Not Tow Haul" 0 "No Override" ;
VAL_TABLE_ TrnsStSprtMdOvrd 2 "Override To Sport" 1 "Override To Not Sport" 0 "No Override" ;
VAL_TABLE_ TrnsStEconMdOvrd 2 "Override To Economy" 1 "Override To Not Economy" 0 "No Override" ;
VAL_TABLE_ StgSysPerfMdRq 7 "Performance Mode 7" 6 "Performance Mode 6" 5 "Performance Mode 5" 4 "Performance Mode 4" 3 "Performance Mode 3" 2 "Performance Mode 2" 1 "Performance Mode 1" 0 "No Action" ;
VAL_TABLE_ SndEnhcmtPerfMdRq 7 "Performance Mode 7" 6 "Performance Mode 6" 5 "Performance Mode 5" 4 "Performance Mode 4" 3 "Performance Mode 3" 2 "Performance Mode 2" 1 "Performance Mode 1" 0 "No Action" ;
VAL_TABLE_ RideCntrlPerfMdRq 7 "Performance Mode 7" 6 "Performance Mode 6" 5 "Performance Mode 5" 4 "Performance Mode 4" 3 "Performance Mode 3" 2 "Performance Mode 2" 1 "Performance Mode 1" 0 "No Action" ;
VAL_TABLE_ ExhstPerfMdRq 7 "Performance Mode 7" 6 "Performance Mode 6" 5 "Performance Mode 5" 4 "Performance Mode 4" 3 "Performance Mode 3" 2 "Performance Mode 2" 1 "Performance Mode 1" 0 "No Action" ;
VAL_TABLE_ DsplyPerfMdRq 7 "Performance Mode 7" 6 "Performance Mode 6" 5 "Performance Mode 5" 4 "Performance Mode 4" 3 "Performance Mode 3" 2 "Performance Mode 2" 1 "Performance Mode 1" 0 "No Action" ;
VAL_TABLE_ DiffPerfMdRq 7 "Performance Mode 7" 6 "Performance Mode 6" 5 "Performance Mode 5" 4 "Performance Mode 4" 3 "Performance Mode 3" 2 "Performance Mode 2" 1 "Performance Mode 1" 0 "No Action" ;
VAL_TABLE_ AWDPerfMdRq 7 "Performance Mode 7" 6 "Performance Mode 6" 5 "Performance Mode 5" 4 "Performance Mode 4" 3 "Performance Mode 3" 2 "Performance Mode 2" 1 "Performance Mode 1" 0 "No Action" ;
VAL_TABLE_ RdHVltBatPckVltM 1 "Use Data" 0 "Don't Use Data" ;
VAL_TABLE_ RdHVltBatPckCrntM 1 "Use Data" 0 "Don't Use Data" ;
VAL_TABLE_ RdHVltBatMinClVltM 1 "Use Data" 0 "Don't Use Data" ;
VAL_TABLE_ RdHVltBatMaxClVltM 1 "Use Data" 0 "Don't Use Data" ;
VAL_TABLE_ TravelDirection 3 "Other (excessive side slip)" 2 "reverse / stopped in rvrs gear" 1 "Forward / stopped in frwd gear" 0 "Unknown" ;
VAL_TABLE_ AFRP_SnsTyp 3 "Gauge Pressure" 2 "Absolute Pressure" 1 "Pressure Relative Manifold Vacuum" 0 "Not Supported" ;
VAL_TABLE_ FICMDS3_DTCStatus 4 "Diagnostic Failed" 3 "Diagnostic Passed" 2 "No Status to Report" 1 "Critically Disabled" 0 "Not Supported" ;
VAL_TABLE_ FICMDS2_DTCStatus 4 "Diagnostic Failed" 3 "Diagnostic Passed" 2 "No Status to Report" 1 "Critically Disabled" 0 "Not Supported" ;
VAL_TABLE_ FICMDS1_DTCStatus 4 "Diagnostic Failed" 3 "Diagnostic Passed" 2 "No Status to Report" 1 "Critically Disabled" 0 "Not Supported" ;
VAL_TABLE_ PropSysOffTmeM 1 "Use Data" 0 "Don't Use Data" ;
VAL_TABLE_ OffBrdChrgOffTmeM 1 "Use Data" 0 "Don't Use Data" ;
VAL_TABLE_ BattThrmlCondOffTmeM 1 "Use Data" 0 "Don't Use Data" ;
VAL_TABLE_ CrsSecSwStat 15 "Unused and Reserved 5" 14 "Unused and Reserved 4" 13 "Unused and Reserved 3" 12 "Unused and Reserved 2" 11 "Unused and Reserved 1" 10 "Lane Centering Control" 9 "Between Ranges" 8 "Short to Power" 7 "Open/Short to Ground" 6 "Speed Decrease High" 5 "Speed Increase High" 4 "Gap Up" 3 "Gap Down" 2 "Lane Keep Assist" 1 "No Activation" 0 "Indeterminate" ;
VAL_TABLE_ EDADS_RcmndtFwdGr 15 "Unused and Reserved 7" 14 "Unused and Reserved 6" 13 "Unused and Reserved 5" 12 "Unused and Reserved 4" 11 "Unused and Reserved 3" 10 "Tenth Gear" 9 "Ninth Gear" 8 "Eighth Gear" 7 "Seventh Gear" 6 "Sixth Gear" 5 "Fifth Gear" 4 "Fourth Gear" 3 "Third Gear" 2 "Second Gear" 1 "First Gear" 0 "None" ;
VAL_TABLE_ EDADS_CrntFwdMsdG 15 "Unused and Reserved 7" 14 "Unused and Reserved 6" 13 "Unused and Reserved 5" 12 "Unused and Reserved 4" 11 "Unused and Reserved 3" 10 "Tenth Gear" 9 "Ninth Gear" 8 "Eighth Gear" 7 "Seventh Gear" 6 "Sixth Gear" 5 "Fifth Gear" 4 "Fourth Gear" 3 "Third Gear" 2 "Second Gear" 1 "First Gear" 0 "None" ;
VAL_TABLE_ EDADS_ShftIndStat 2 "No Shift" 1 "Shift Up" 0 "Shift Down" ;
VAL_TABLE_ GPCMDS2_DTCStatus 4 "Diagnostic Failed" 3 "Diagnostic Passed" 2 "No Status to Report" 1 "Critically Disabled" 0 "Not Supported" ;
VAL_TABLE_ EngPwrCnfg 15 "Configuration 15" 14 "Configuration 14" 13 "Configuration 13" 12 "Configuration 12" 11 "Configuration 11" 10 "Configuration 10" 9 "Configuration 9" 8 "Configuration 8" 7 "Configuration 7" 6 "Configuration 6" 5 "Configuration 5" 4 "Configuration 4" 3 "Configuration 3" 2 "Configuration 2" 1 "Configuration 1" 0 "Default" ;
VAL_TABLE_ CTSS_StbltyLvl 7 "Level 7" 6 "Level 6" 5 "Level 5" 4 "Level 4" 3 "Level 3" 2 "Level 2" 1 "Level 1" 0 "Level 0" ;
VAL_TABLE_ CTSS_StbltyTyp 7 "Unused and Reserved 4" 6 "Unused and Reserved 3" 5 "Unused and Reserved 2" 4 "Unused and Reserved 1" 3 "Torque Increase Pending" 2 "Torque Decrease Pending" 1 "Torque High Pulsation" 0 "Normal Stability" ;
VAL_TABLE_ DslExhFldWrngIdRqER 15 "Warning Level 15" 14 "Warning Level 14" 13 "Warning Level 13" 12 "Warning Level 12" 11 "Warning Level 11" 10 "Warning Level 10" 9 "Warning Level 9" 8 "Warning Level 8" 7 "Warning Level 7" 6 "Warning Level 6" 5 "Warning Level 5" 4 "Warning Level 4" 3 "Warning Level 3" 2 "Warning Level 2" 1 "Warning Level 1" 0 "No Indication" ;
VAL_TABLE_ DslExhFldQlyWrngIReq 15 "Warning Level 15" 14 "Warning Level 14" 13 "Warning Level 13" 12 "Warning Level 12" 11 "Warning Level 11" 10 "Warning Level 10" 9 "Warning Level 9" 8 "Warning Level 8" 7 "Warning Level 7" 6 "Warning Level 6" 5 "Warning Level 5" 4 "Warning Level 4" 3 "Warning Level 3" 2 "Warning Level 2" 1 "Warning Level 1" 0 "No Indication" ;
VAL_TABLE_ DslExNxEmWrngIndRq 15 "Warning Level 15" 14 "Warning Level 14" 13 "Warning Level 13" 12 "Warning Level 12" 11 "Warning Level 11" 10 "Warning Level 10" 9 "Warning Level 9" 8 "Warning Level 8" 7 "Warning Level 7" 6 "Warning Level 6" 5 "Warning Level 5" 4 "Warning Level 4" 3 "Warning Level 3" 2 "Warning Level 2" 1 "Warning Level 1" 0 "No Indication" ;
VAL_TABLE_ DslExFldTpWrngIndRq 15 "Warning Level 15" 14 "Warning Level 14" 13 "Warning Level 13" 12 "Warning Level 12" 11 "Warning Level 11" 10 "Warning Level 10" 9 "Warning Level 9" 8 "Warning Level 8" 7 "Warning Level 7" 6 "Warning Level 6" 5 "Warning Level 5" 4 "Warning Level 4" 3 "Warning Level 3" 2 "Warning Level 2" 1 "Warning Level 1" 0 "No Indication" ;
VAL_TABLE_ DslExFldCnWrngIndRq 15 "Warning Level 15" 14 "Warning Level 14" 13 "Warning Level 13" 12 "Warning Level 12" 11 "Warning Level 11" 10 "Warning Level 10" 9 "Warning Level 9" 8 "Warning Level 8" 7 "Warning Level 7" 6 "Warning Level 6" 5 "Warning Level 5" 4 "Warning Level 4" 3 "Warning Level 3" 2 "Warning Level 2" 1 "Warning Level 1" 0 "No Indication" ;
VAL_TABLE_ DrvSelMdSw3Sta 1 "Active" 0 "Inactive" ;
VAL_TABLE_ DrvSelMdSw2Sta 1 "Active" 0 "Inactive" ;
VAL_TABLE_ DrvSelMd8Stat 1 "Active" 0 "Inactive" ;
VAL_TABLE_ DrvSelMd7Stat 1 "Active" 0 "Inactive" ;
VAL_TABLE_ DrvSelMd6Stat 1 "Active" 0 "Inactive" ;
VAL_TABLE_ DrvSelMd5Stat 1 "Active" 0 "Inactive" ;
VAL_TABLE_ DrvSelMd4Stat 1 "Active" 0 "Inactive" ;
VAL_TABLE_ DrvSelMd3Stat 1 "Active" 0 "Inactive" ;
VAL_TABLE_ DrvSelMd2Stat 1 "Active" 0 "Inactive" ;
VAL_TABLE_ A6ERRAlrmReq 2 "Cancel Alarm" 1 "Set Alarm" 0 "No Action" ;
VAL_TABLE_ MntnceMdDsplyRq 15 "Unused and Reserved" 14 "Continue FM" 13 "Force FM" 12 "FM 1 Day Warning" 11 "FM 2 Day Warning" 10 "FM 3 Day Warning" 9 "FM 4 Day Warning" 8 "FM 5 Day Warning" 7 "Continue EM" 6 "Force EM" 5 "EM 1 Day Warning" 4 "EM 2 Day Warning" 3 "EM 3 Day Warning" 2 "EM 4 Day Warning" 1 "EM 5 Day Warning" 0 "No Request" ;
VAL_TABLE_ HybACCompRq 3 "Reserved" 2 "Disengage" 1 "Engage" 0 "No Action" ;
VAL_TABLE_ AuxClntHtrVlvStat 7 "Unused and Reserved 2" 6 "De-Aeration Routine Active" 5 "Diagnostic Override" 4 "Re-Calibration" 3 "Fault Active" 2 "Engine Link" 1 "Transition" 0 "Engine Bypass" ;
VAL_TABLE_ DrvSelMdSw1Sta 1 "Active" 0 "Inactive" ;
VAL_TABLE_ DrvSelMd1Stat 1 "Active" 0 "Inactive" ;
VAL_TABLE_ ETC_EngOpMd 1 "Half Cylinders" 0 "All cylinders" ;
VAL_TABLE_ EngCntrlUtldTrnCsRng 3 "Neutral" 2 "Unused and Reserved" 1 "Low" 0 "High" ;
VAL_TABLE_ CSTATRS_ReqStat 6 "Control System Failure Permanent" 5 "Control System Failure Temporary" 4 "Serial Data Failure Permanent" 3 "Serial Data Failure Temporary" 2 "Lost Arbitration" 1 "Request Honored" 0 "No Request" ;
VAL_TABLE_ CSTATRS_LmtgStat 3 "Rate and Value Limited" 2 "Value Limited" 1 "Rate Limited" 0 "Not Limited" ;
VAL_TABLE_ PTTrnsfrCseMd 3 "Neutral" 2 "4 Wheel Drive Low" 1 "4 Wheel Drive High" 0 "2 Wheel Drive High" ;
VAL_TABLE_ TrnsHybEngSrtStpOvrd 2 "Engine Off" 1 "Engine On" 0 "No Override" ;
VAL_TABLE_ EngCntrlDtrmdTrfCRng 3 "Neutral" 2 "Unused and Reserved" 1 "Low" 0 "High" ;
VAL_TABLE_ ElecPrkBrkAvailStat 7 "Unused and Reserved 3" 6 "Unused and Reserved 2" 5 "Unused and Reserved 1" 4 "Unavailable, Failed other" 3 "Unavailable, Failed Released" 2 "Unavailable, Failed Applied" 1 "Available, Not Failed" 0 "Unavailable, Not Failed" ;
VAL_TABLE_ ElecPrkBrkApplStat 3 "Park Brake Application in Progress" 2 "Park brake Released" 1 "Park Brake Applied" 0 "Unknown" ;
VAL_TABLE_ BCHR_BattCrntRwVlMu 3 "Multiplier Factor 256" 2 "Multiplier Factor 64" 1 "Multiplier Factor 8" 0 "Multiplier Factor 1" ;
VAL_TABLE_ BattSOXStat 1 "Use SOC,SOH, & SOF" 0 "Don't Use SOC,SOH, & SOF" ;
VAL_TABLE_ CSPATR_TrqIntrvnTyp 3 "Minimum and Maximum Limit" 2 "Minimum Limit" 1 "Maximum Limit" 0 "No Intervention" ;
VAL_TABLE_ CSPATR_TrqRqTyp 0 "Absolute Torque Request" ;
VAL_TABLE_ ChsSysAxlTqRqRspTyp 4 "Braking Torque Request" 3 "Automatic Actuator Selection" 2 "Maximum Range Request" 1 "Pleasability Limited Request" 0 "Inactive" ;
VAL_TABLE_ EngOffTmPTM 1 "Use Data" 0 "Don't Use Data" ;
VAL_TABLE_ HybMdDisp 15 "Engine Charging Battery While Idle" 14 "Engine Charging Battery Moving" 13 "Engine Power Load Sharing" 12 "Battery Power Load Sharing" 11 "Undetermined" 10 "Charging With Engine On" 9 "Charging With Engine Off" 8 "Hybrid Power 4WD" 7 "Hybrid Power 2WD" 6 "Engine Power 4WD" 5 "Engine Power 2WD" 4 "Battery Power 4WD" 3 "Battery Power 2WD" 2 "Auto Stop" 1 "Engine Idle" 0 "Default / Accessory" ;
VAL_TABLE_ PerfTrcTrqRqStat 6 "Control System Failure Permanent" 5 "Control System Failure Temporary" 4 "Serial Data Failure Permanent" 3 "Serial Data Failure Temporary" 2 "Lost Arbitration" 1 "Request Honored" 0 "No Request" ;
VAL_TABLE_ PTTR_TrqRedRlzSugg 1 "Transient Optimized" 0 "No Suggestion" ;
VAL_TABLE_ PTTR_TrqInvTyp 1 "Maximum Limit" 0 "No Intervention" ;
VAL_TABLE_ PerfTrcTrqLmtStat 3 "Rate & Value Limited" 2 "Value Limited" 1 "Rate Limited" 0 "Not Limited" ;
VAL_TABLE_ PerfTrcEngSpdRqStat 6 "Control System Failure Permanent" 5 "Control System Failure Temporary" 4 "Serial Data Failure Permanent" 3 "Serial Data Failure Temporary" 2 "Lost Arbitration" 1 "Request Honored" 0 "No Request" ;
VAL_TABLE_ PTESR_EngSpdCntlRs 3 "Stability Optimized Cond 2" 2 "Stability Optimized Cond 1" 1 "Transient Optimized" 0 "No Suggestion" ;
VAL_TABLE_ PTESR_EngSpdIntTyp 1 "Engine Speed Max Limit" 0 "No Intervention" ;
VAL_TABLE_ PerfTrcEngSpdLmtStat 3 "Rate & Value Limited" 2 "Value Limited" 1 "Rate Limited" 0 "Not Limited" ;
VAL_TABLE_ TPCTR_TrqIntrvnTyp 3 "Unused and Reserved" 2 "Minimum Limit" 1 "Maximum Limit" 0 "No Request" ;
VAL_TABLE_ EngCrsCntrlMode 5 "Tap" 4 "Coast" 3 "Accel" 2 "Resume" 1 "Engaged" 0 "Inactive" ;
VAL_TABLE_ EngPrdctTrqTnsRqStat 7 "Unused and Reserved" 6 "Control System Failure Permanent" 5 "Control System Failure Temporary" 4 "Serial Data Failure Permanent" 3 "Serial Data Failure Temporary" 2 "Lost Arbitration" 1 "Request Honored" 0 "No Request" ;
VAL_TABLE_ EngPrdctTrqTnsRqLmS 7 "Unused and Reserved 4" 6 "Unused and Reserved 3" 5 "Unused and Reserved 2" 4 "Unused and Reserved 1" 3 "Value Limited High" 2 "Value Limited Low" 1 "Rate Limited" 0 "Not Limited" ;
VAL_TABLE_ EngImmTrqTnsRqStat 0 "No Request" 7 "Unused and Reserved" 6 "Control System Failure Permanent" 5 "Control System Failure Temporary" 4 "Serial Data Failure Permanent" 3 "Serial Data Failure Temporary" 2 "Lost Arbitration" 1 "Request Honored" ;
VAL_TABLE_ EngImmTrqTnsRqLmSt 7 "Unused and Reserved 4" 6 "Unused and Reserved 3" 5 "Unused and Reserved 2" 4 "Unused and Reserved 1" 3 "Value Limited High" 2 "Value Limited Low" 1 "Rate Limited" 0 "Not Limited" ;
VAL_TABLE_ CrsSpdLmtrSwStat 9 "Between Ranges" 8 "Short to Power" 7 "Open/Short to Ground" 6 "Cancel" 5 "Cruise On/Off" 4 "SL/SW On/Off/GAP" 3 "Set" 2 "Resume" 1 "No Activation" 0 "Indeterminate" ;
VAL_TABLE_ RrAxlSta 3 "Permanently Failed" 2 "Temporary Limited" 1 "Temporary Inhibit" 0 "Normal" ;
VAL_TABLE_ SecAxlStat 3 "Permanently Failed" 2 "Temporary Limited" 1 "Temporary Inhibit" 0 "Normal" ;
VAL_TABLE_ HESSI_EngStrtTyp 9 "Compression Test" 8 "Auto Start Generic" 7 "Auto Start Aggressive" 6 "Auto Start Normal" 5 "Auto Start Smooth" 4 "Key Start Generic" 3 "Key Start Low Power B" 2 "Key Start Low Power" 1 "Key Start Normal" 0 "No Start" ;
VAL_TABLE_ HESSI_EngStrtStpMd 7 "Start Failed" 6 "Stop Pending" 5 "Disable Fuel" 4 "Producing Torque" 3 "Enable Fuel" 2 "Start Pending" 1 "Immediate Stop" 0 "Stop" ;
VAL_TABLE_ HybDFCOReq 1 "DFCO Requested" 0 "DFCO Not Requested" ;
VAL_TABLE_ EngCntlSenPTRlyVltM 1 "Use Data" 0 "Don't Use Data" ;
VAL_TABLE_ GPCMDS_DTCStatus 4 "Diagnostic Failed" 3 "Diagnostic Passed" 2 "No Status to Report" 1 "Critically Disabled" 0 "Not Supported" ;
VAL_TABLE_ IQAI_InjIdInd 7 "Injector 8" 6 "Injector 7" 5 "Injector 6" 4 "Injector 5" 3 "Injector 4" 2 "Injector 3" 1 "Injector 2" 0 "Injector 1" ;
VAL_TABLE_ IQAI_DataStat 1 "IQA Data Byte Stored" 0 "IQA Data Byte Not Stored" ;
VAL_TABLE_ ACCATC_DrvAstdGoSt 3 "Auto Resume Pending" 2 "Apply Acc Pedal or Resume Sw To Go" 1 "Apply Accel Pedal to Go" 0 "Not Stopped" ;
VAL_TABLE_ WhlSlpSt 3 "Slip Detection Fault" 2 "Positive Slip Detected" 1 "Negative Slip Detected" 0 "No Slip Detected" ;
VAL_TABLE_ EnhSvVehTopSpdLmR 2 "Inactive" 1 "Active" 0 "No Action" ;
VAL_TABLE_ ACCmEngRunReq 1 "Engine Run Requested" 0 "No Action" ;
VAL_TABLE_ FuelMdSwAct 1 "True" 0 "False" ;
VAL_TABLE_ FuelMdStat 3 "Alternative Fuel Cut-off Active" 2 "Liquified Petroleum Gas Mode" 1 "Natural Gas Mode" 0 "Gasoline Mode" ;
VAL_TABLE_ WrmUpShftPtrnRq 1 "Active" 0 "Inactive" ;
VAL_TABLE_ EngCntrlRunCrnkTrmSt 1 "Active" 0 "Inactive" ;
VAL_TABLE_ ACCATC_ACCTyp 3 "Full Speed Range ACC with LCC" 2 "Full Speed Range ACC with Booster" 1 "Full Speed Range ACC" 0 "Adaptive Cruise Control" ;
VAL_TABLE_ ACCATCS_RqStat 4 "Request Suspended Till Driver Input" 3 "Request Denied" 2 "Lost Arbitration" 1 "Request Honored" 0 "No Request" ;
VAL_TABLE_ ACCATCS_LmtgStat 3 "Request Rate Limited" 2 "Request Value Limited Maximum" 1 "Request Value Limited Minimum" 0 "Request Not Limited" ;
VAL_TABLE_ EPBSysWrnIndReq 3 "Flash Rate #2 Indication" 2 "Flash Rate #1 Indication" 1 "Continuous Indication" 0 "No Indication" ;
VAL_TABLE_ ClmnLckStat 2 "Locked unsuccessful" 1 "Unlocked" 0 "Locked" 3 "Unlocked unsuccessful" ;
VAL_TABLE_ VehSpeSta 3 "Invalid" 2 "Fast" 1 "Slow" 0 "Stationary" ;
VAL_TABLE_ DslPartFltrClngAlgActM 1 "Use Data" 0 "Don't Use Data" ;
VAL_TABLE_ SecAxlOpeMod 3 "Active All Wheel Drive (High)" 2 "4 Wheel Drive Low Locked" 1 "4 Wheel Drive High Locked" 0 "2 Wheel Drive High" 15 "Neutral" 14 "Unknown" 7 "2 Wheel Drive Low" 6 "Active All Wheel Drive (Low)" 5 "4 Wheel Drive Low Open" 4 "4 Wheel Drive High Open" ;
VAL_TABLE_ SecAxlCtrlMod 1 "External" 0 "Internal" ;
VAL_TABLE_ RrAxlOpeMod 3 "Unknown" 2 "Locked" 1 "Active" 0 "Open" ;
VAL_TABLE_ RrAxlCtrlMod 1 "External" 0 "Internal" ;
VAL_TABLE_ EPBSwSta 3 "Active" 2 "Apply" 1 "Release" 0 "NotActive" ;
VAL_TABLE_ EPBSta 2 "Fault" 1 "Applied" 0 "Released" ;
VAL_TABLE_ FlPmpEDscOtptCmdSta 1 "Fuel Pump Enabled" 0 "Fuel Pump Disabled" ;
VAL_TABLE_ TransTUDMdStat 2 "Electronic Range Select Active" 1 "Driver Shift Control Active" 0 "No Activation" ;
VAL_TABLE_ TrnShftPtrnActStat 6 "PT Protection Pattern Active" 5 "PT Non-Protection Pattern Active" 4 "Shift Pattern 4 Active" 3 "Shift Pattern 3 Active" 2 "Shift Pattern 2 Active" 1 "Shift Pattern 1 Active" 0 "Default Shift Pattern Active" ;
VAL_TABLE_ EPBSysAudWarnReq 2 "Warning #2" 1 "Warning #1" 0 "Off" ;
VAL_TABLE_ NotEventSta 2 "Pretensioner Deployment Event" 1 "Near Deployment Event" 0 "No Event" 3 "Airbag Deployment Event" ;
VAL_TABLE_ VehMovSta 4 "Invalid" 3 "Reverse" 2 "Forward" 1 "Neutral" 0 "Parked" ;
VAL_TABLE_ PFTrnsTUDSwSt 3 "Illegal Up/Down Switch State Active" 2 "Decrement Switch Active" 1 "Increment Switch Active" 0 "No Activation" ;
VAL_TABLE_ PFTrnsTUDEnSwSt 3 "Illegal Enable Switch State" 2 "Electronic Range Select Enable Sw" 1 "Driver Shift Control Enable Switch" 0 "No Activation" ;
VAL_TABLE_ HdSt 2 "Open" 1 "Ajar" 0 "Closed" ;
VAL_TABLE_ AuxHtrRq 1 "On" 0 "Off" ;
VAL_TABLE_ TrnsEngdState 3 "Operating State Not Reached" 2 "Transmission Engaged in Reverse" 1 "Transmission Engaged in Forward" 0 "Transmission Not Engaged" ;
VAL_TABLE_ EPBSysDspMsgReq 7 "Message #7" 6 "Message #6" 5 "Message #5" 4 "Message #4" 3 "Message #3" 2 "Message #2" 1 "Message #1" 0 "Off" ;
VAL_TABLE_ OtsdAmbtLtLvlStat 2 "Day" 1 "Night" 0 "Unknown" ;
VAL_TABLE_ RdSpdCatType 3 "all speed categories 0 - 50 km/h" 2 "all speed categories 51-80 km/h" 1 "all speed categories 81-130 km/h" 0 "all speed categories > 130 km/h" ;
VAL_TABLE_ LnCat 3 "Four Or More Lanes" 2 "Two Or Three Lanes" 1 "One lane" 0 "no info available" ;
VAL_TABLE_ FncRdClass 7 "COLLECTOR" 6 "ALLEY" 5 "ARTERIAL" 4 "HIGHWAY" 3 "PED-MALL" 2 "FREEWAY" 1 "SFREEWAY" 0 "LOCAL (Residential Road)" ;
VAL_TABLE_ CustomizationSettingRequest 7 "Auto" 6 "Performance Mode 6" 5 "Performance Mode 5" 4 "Performance Mode 4" 3 "Performance Mode 3" 2 "Performance Mode 2" 1 "Performance Mode 1" 0 "No Action" ;
VAL_TABLE_ RstrCustFctrDef 1 "Restore Defaults" 0 "No Action" ;
VAL_TABLE_ PFTrnsTUDSecSwSt 3 "Illegal Up/Down Switch State Active" 2 "Decrement Switch Active" 1 "Increment Switch Active" 0 "No Activation" ;
VAL_TABLE_ AdvFrntLghtSysIndRq 7 "Indication 7" 6 "Indication 6" 5 "Indication 5" 4 "Indication 4" 3 "Indication 3" 2 "Indication 2" 1 "Indication 1" 0 "No Indication" ;
VAL_TABLE_ CustomizationCurrentSettingValue 7 "Auto" 6 "Performance Mode 6" 5 "Performance Mode 5" 4 "Performance Mode 4" 3 "Performance Mode 3" 0 "No Action" 1 "Performance Mode 1" 2 "Performance Mode 2" ;
VAL_TABLE_ EPBSysStatIndReq 3 "Flash Rate 2 Indication" 2 "Flash Rate 1 Indication" 1 "Continuous Indication" 0 "No Indication" ;
VAL_TABLE_ AllNodesVNA 1 "Activate Virtual Network" 0 "No Activation" ;
VAL_TABLE_ ClntCircPmpRq 1 "On" 0 "Off" ;
VAL_TABLE_ ImoIdSt 1 "Info valid" 0 "No info" ;
VAL_TABLE_ LrnEnvIdSt 1 "Info_valid" 0 "No_info" ;
VAL_TABLE_ EnvIdRspSt4 3 "Environment_id_request" 2 "Incorrect_immo_id" 1 "Info_valid" 0 "No_info" ;
VAL_TABLE_ VDAvailability 1 "VirtualDeviceAvailable" 0 "VirtualDeviceUnavailable" ;
VAL_TABLE_ AlrmStat 4 "Arming Delay" 3 "Alarm Active" 2 "Disarmed" 1 "Armed" 0 "Off" ;
VAL_TABLE_ RstVTDTmprDtctd 1 "Reset" 0 "No Action" ;
VAL_TABLE_ RstIllDrIdDevDtctd 1 "Reset" 0 "No Action" ;
VAL_TABLE_ RstDrIdDevLrnd 1 "Reset" 0 "No Action" ;
VAL_TABLE_ CldrMth 12 "December" 11 "November" 10 "October" 9 "September" 8 "August" 7 "July" 6 "June" 5 "May" 4 "April" 3 "March" 2 "February" 1 "January" 0 "Unknown" ;
VAL_TABLE_ TrnSwAct 2 "Right" 1 "Left" 0 "No Activation" ;
VAL_TABLE_ VehHghtStat 4 "Maximum Height" 3 "Kneeling Height" 2 "Aerodynamic Height" 1 "Normal Design Ride Height" 0 "Unknown" ;
VAL_TABLE_ HdlmpBmSelectStat 2 "High Beams" 1 "Low Beams" 0 "Unknown" ;
VAL_TABLE_ ACSAlarm9 2 "Expired" 1 "Active" 0 "Inactive" ;
VAL_TABLE_ ACSAlarm8 2 "Expired" 1 "Active" 0 "Inactive" ;
VAL_TABLE_ ACSAlarm7 2 "Expired" 1 "Active" 0 "Inactive" ;
VAL_TABLE_ ACSAlarm6 2 "Expired" 1 "Active" 0 "Inactive" ;
VAL_TABLE_ ACSAlarm5 2 "Expired" 1 "Active" 0 "Inactive" ;
VAL_TABLE_ ACSAlarm4 2 "Expired" 1 "Active" 0 "Inactive" ;
VAL_TABLE_ ACSAlarm3 2 "Expired" 1 "Active" 0 "Inactive" ;
VAL_TABLE_ ACSAlarm2 2 "Expired" 1 "Active" 0 "Inactive" ;
VAL_TABLE_ ACSAlarm15 2 "Expired" 1 "Active" 0 "Inactive" ;
VAL_TABLE_ ACSAlarm14 2 "Expired" 1 "Active" 0 "Inactive" ;
VAL_TABLE_ ACSAlarm13 2 "Expired" 1 "Active" 0 "Inactive" ;
VAL_TABLE_ ACSAlarm12 2 "Expired" 1 "Active" 0 "Inactive" ;
VAL_TABLE_ ACSAlarm11 2 "Expired" 1 "Active" 0 "Inactive" ;
VAL_TABLE_ ACSAlarm10 2 "Expired" 1 "Active" 0 "Inactive" ;
VAL_TABLE_ ACSAlarm1 2 "Expired" 1 "Active" 0 "Inactive" ;
VAL_TABLE_ ACSAlarm0 2 "Expired" 1 "Active" 0 "Inactive" ;
VAL_TABLE_ ACCHdwyStg 7 "Headway Setting 7" 6 "Headway Setting 6" 5 "Headway Setting 5" 4 "Headway Setting 4" 3 "Headway Setting 3" 2 "Headway Setting 2" 1 "Headway Setting 1" 0 "Minimum Headway Setting" ;
VAL_TABLE_ VehStabEnhmntMd 2 "Competitive" 1 "Normal" 0 "Off" ;
VAL_TABLE_ VehStabEnhmntStat 4 "Not Ready" 3 "Warming Up" 2 "Fault" 1 "Active" 0 "Inactive" ;
VAL_TABLE_ TCSysOpMd 2 "Off Road" 1 "Normal" 0 "Off" ;
VAL_TABLE_ TCSysOpStat 2 "Fault" 1 "Active" 0 "Inactive" ;
VAL_TABLE_ HillDscntCntlSysStat 4 "Temporarily Inhibited" 3 "Failed" 2 "Active" 1 "Enabled" 0 "Normal" ;
VAL_TABLE_ EnrgMgtLdShdRq 4 "Load Shed Level 4" 3 "Load Shed Level 3" 2 "Load Shed Level 2" 1 "Load Shed Level 1" 0 "No Load Shedding" ;
VAL_TABLE_ DrId 7 "Unknown" 6 "Driver #7" 5 "Driver #6" 4 "Driver #5" 3 "Driver #4" 2 "Driver #3" 1 "Driver #2" 0 "Driver #1" ;
VAL_TABLE_ TireRRPrsStat 5 "High" 4 "Low - Extended Mobility" 3 "Low" 2 "Low - Service Now" 1 "Nominal" 0 "Unknown" ;
VAL_TABLE_ TireRFPrsStat 5 "High" 4 "Low - Extended Mobility" 3 "Low" 2 "Low - Service Now" 1 "Nominal" 0 "Unknown" ;
VAL_TABLE_ TireLRPrsStat 5 "High" 4 "Low - Extended Mobility" 3 "Low" 2 "Low - Service Now" 1 "Nominal" 0 "Unknown" ;
VAL_TABLE_ TireLFPrsStat 5 "High" 4 "Low - Extended Mobility" 3 "Low" 2 "Low - Service Now" 1 "Nominal" 0 "Unknown" ;
VAL_TABLE_ DTCI_DTCFaultType 3 "Type C" 2 "Type B" 1 "Type A" 0 "Not Supported" ;
VAL_TABLE_ DistRollCntAvgDrvnSrc 1 "Wheel Speed" 0 "Transmission Output Speed" ;
VAL_TABLE_ VehSpdAvgDrvnSrc 1 "Wheel Speed" 0 "Transmission Output Speed" ;
VAL_TABLE_ TORSLstTransType 3 "Undefined" 2 "Falling Transition" 1 "Rising Transition" 0 "Single Edge Sensor" ;
VAL_TABLE_ TORSRotDir 3 "Undefined" 2 "Reverse" 1 "Forward" 0 "Unknown" ;
VAL_TABLE_ TrnsThrmlMngmntStat 2 "Driver Intervention Requested" 1 "Countermeasures Active" 0 "Normal" ;
VAL_TABLE_ TrnsSftMdStat 3 "Automatic Grade Braking Mode" 2 "Lift-Foot Cornering Mode" 1 "Performance Mode" 0 "No Override Mode" ;
VAL_TABLE_ TrnsRngInhbtStat 4 "Diagnostic Inhibit Active" 3 "Driveline Not Engaged" 2 "Transmission Range Re-Selection Req" 1 "Transmission Inhibit Active" 0 "No Range Inhibit Active" ;
VAL_TABLE_ DrvtShftCntrlTrgtGear 10 "Tenth Gear" 9 "Ninth Gear" 8 "Eighth Gear" 7 "Seventh Gear" 6 "Sixth Gear" 5 "Fifth Gear" 4 "Fourth Gear" 3 "Third Gear" 2 "Second Gear" 1 "First Gear" 0 "Not Supported" ;
VAL_TABLE_ StrWhlAngSenCalStat 2 "Calibrated" 1 "Estimated" 0 "Unknown" ;
VAL_TABLE_ PTOTGRReqdGear 10 "Tenth Gear" 9 "Ninth Gear" 8 "Eighth Gear" 7 "Seventh Gear" 6 "Sixth Gear" 5 "Fifth Gear" 4 "Fourth Gear" 3 "Third Gear" 2 "Second Gear" 1 "First Gear" 0 "No Action" ;
VAL_TABLE_ PTOTGRReqType 3 "Hold Gear" 2 "Min Gear Request" 1 "Max Gear Request" 0 "No Action" ;
VAL_TABLE_ PTORmtEngStrtReq 1 "PTO Remote Start Requested" 0 "PTO Remote Start Not Requested" ;
VAL_TABLE_ FSERDTC_SysDes 15 "U3-Network Codes Reserved" 14 "U2-Network Codes Reserved" 13 "U1-Network Codes MFG Controlled" 12 "U0-Network Codes SAE Controlled" 11 "B3-Body Codes Reserved" 10 "B2-Body Codes Reserved" 9 "B1-Body Codes MFG Controlled" 8 "B0-Body Codes SAE Controlled" 7 "C3-Chassis Codes Reserved" 6 "C2-Chassis Codes Reserved" 5 "C1-Chassis Codes MFG Controlled" 4 "C0-Chassis Codes SAE Controlled" 3 "P3-Powertrain Codes Reserved" 2 "P2-Powertrain Codes Reserved" 1 "P1-Powertrain Codes MFG Controlled" 0 "P0-Powertrain Codes SAE Controlled" ;
VAL_TABLE_ EngFuelCntlState 2 "Stoichiometric Closed Loop" 1 "Non-Stoichiometric Closed Loop" 0 "Open Loop" ;
VAL_TABLE_ EngTrqRdFlrSt 4 "Torq Reduction Communication Failed" 3 "Torque Reduction Limited" 2 "Torque Reduction Permanently Failed" 1 "Torque Reduction Temporarily Failed" 0 "Torque Reduction OK" ;
VAL_TABLE_ ParkNeutralSwStat 1 "Not Park/Neutral" 0 "Park/Neutral" ;
VAL_TABLE_ EngBrkStat 2 "Active Absorbing Torque" 1 "Active Not Absorbing Torque" 0 "Inactive" ;
VAL_TABLE_ ETGRReqdGear 10 "Tenth Gear" 9 "Ninth Gear" 8 "Eighth Gear" 7 "Seventh Gear" 6 "Sixth Gear" 5 "Fifth Gear" 4 "Fourth Gear" 3 "Third Gear" 2 "Second Gear" 1 "First Gear" 0 "No Action" ;
VAL_TABLE_ ETGRReqType 0 "No Action" 3 "Hold Gear" 2 "Min Gear Request" 1 "Max Gear Request" ;
VAL_TABLE_ OAT_PT_EstM 1 "Use Data" 0 "Don't Use Data" ;
VAL_TABLE_ ACCompCmnd 1 "On" 0 "Off" ;
VAL_TABLE_ EngEmsRelMalfIndReq 4 "Flashing 0.5 Hertz Indication" 3 "Flashing 2 Hertz Indication" 2 "Flashing 1 Hertz Indication" 1 "No Indication" 0 "Continuous Indication" ;
VAL_TABLE_ EngCylDeactMd 3 "Reactivation In Progress" 2 "Half of Total Cylinders Active" 1 "Deactivation In Progress" 0 "All Cylinders Active" ;
VAL_TABLE_ PltfrmEngSpdCmdInhtRq 1 "Inhibit Platform Eng. Speed Control" 0 "Allow Platform Engine Speed Control" ;
VAL_TABLE_ PT_BrkPedDscrtInpStat 1 "Brake Applied" 0 "Brake Not Applied" ;
VAL_TABLE_ EngSpdStat 3 "Invalid" 1 "Degraded Operation" 0 "Normal Operation" ;
VAL_TABLE_ TrnsCyDactTransStat 2 "Ready for Half of TotalCylinders" 1 "Ready for All Cylinders" 0 "Not Ready" ;
VAL_TABLE_ ACCompSysVDM 1 "Use Data" 0 "Don't Use Data" ;
VAL_TABLE_ BkupPwrModeMstrVDM 1 "Use Data" 0 "Don't Use Data" ;
VAL_TABLE_ PrkBrkVDM 1 "Use Data" 0 "Don't Use Data" ;
VAL_TABLE_ DispMeasSys 1 "English" 0 "Metric" ;
VAL_TABLE_ ACCompModReq 3 "No Action" 2 "Engage" 1 "Disengage" 0 "Disengage Immediately" ;
VAL_TABLE_ TransNtrlCntrlMdStat 3 "Exiting Neutral Control" 2 "Neutral Control Active" 1 "Entering Neutral Control" 0 "Neutral Control Not Active" ;
VAL_TABLE_ TrnsShftLvrPos 13 "Forward Range J" 12 "Froward Range I" 15 "Lever Position Unknown" 11 "Forward Range H" 10 "Forward Range G" 9 "Forward Range F" 8 "Forward Range E" 7 "Forward Range D" 6 "Forward Range C" 5 "Forward Range B" 4 "Forward Range A" 3 "Neutral Range" 2 "Reverse Range" 1 "Park Range" 0 "Between Ranges" ;
VAL_TABLE_ TrnsTrqCnvCltCmndMd 7 "Not Supported" 3 "Locked" 2 "Controlled Slip" 1 "Transitioning" 0 "Unlocked" ;
VAL_TABLE_ AutoTransComndGear 9 "Ninth Gear" 15 "Park Gear" 14 "Reverse Gear" 13 "Neutral Gear" 12 "CVT Forward Gear" 11 "Unused and Reserved" 10 "Tenth Gear" 8 "Eighth Gear" 7 "Seventh Gear" 6 "Sixth Gear" 5 "Fifth Gear" 4 "Fourth Gear" 3 "Third Gear" 2 "Second Gear" 1 "First Gear" 0 "Not Supported" ;
VAL_TABLE_ AutoTransGrSftDirect 2 "Downshift in Progress" 1 "Upshift in Progress" 0 "No Shift in Progress" ;
VAL_TABLE_ TransEstGear 9 "Ninth Gear" 15 "Park Gear" 14 "Reverse Gear" 13 "Neutral Gear" 12 "CVT Forward Gear" 11 "Unused and Reserved" 10 "Tenth Gear" 8 "Eighth Gear" 7 "Seventh Gear" 6 "Sixth Gear" 5 "Fifth Gear" 4 "Fourth Gear" 3 "Third Gear" 2 "Second Gear" 1 "First Gear" 0 "Not Supported" ;
VAL_TABLE_ TERDTC_SysDes 15 "U3-Network Codes Reserved" 14 "U2-Network Codes Reserved" 13 "U1-Network Codes MFG Controlled" 12 "U0-Network Codes SAE Controlled" 11 "B3-Body Codes Reserved" 10 "B2-Body Codes Reserved" 9 "B1-Body Codes MFG Controlled" 8 "B0-Body Codes SAE Controlled" 7 "C3-Chassis Codes Reserved" 6 "C2-Chassis Codes Reserved" 5 "C1-Chassis Codes MFG Controlled" 4 "C0-Chassis Codes SAE Controlled" 3 "P3-Powertrain Codes Reserved" 2 "P2-Powertrain Codes Reserved" 1 "P1-Powertrain Codes MFG Controlled" 0 "P0-Powertrain Codes SAE Controlled" ;
VAL_TABLE_ TESR_EngSpdCntlRsp 3 "Stability Optimized Condition 2" 2 "Stability Optimized Condition 1" 1 "Transient Optimized" 0 "No Suggestion" ;
VAL_TABLE_ TESR_EngSpdIntTyp 3 "Engine Speed Max and Min Limit" 2 "Engine Speed Min Limit" 1 "Engine Speed Max Limit" 0 "No Intervention" ;
VAL_TABLE_ TTRLT_TqRdnRlznSgg 3 "Stability Optimized 2" 2 "Stability Optimized 1" 1 "Transient Optimized" 0 "No Suggestion" ;
VAL_TABLE_ TTRLT_TorqInvntnTyp 2 "Minimum Limit" 1 "Maximum Limit" 0 "No Intervention" ;
VAL_TABLE_ TTRST_TorqInvntnTyp 1 "Maximum Limit" 0 "No Intervention" ;
VAL_TABLE_ PTORmStMsEngStRq 1 "PTO Remote Start Requested" 0 "PTO Remote Start Not Requested" ;
VAL_TABLE_ PFESpdCmdSwDIntg 2 "Failure Detected" 1 "Data Invalid" 0 "Data Valid" ;
VAL_TABLE_ RmVehStrRq 1 "Remote Start Requested" 0 "Remote Start Not Requested" ;
VAL_TABLE_ VehSpdCntlSystmType 2 "Adaptive Cruise Control" 1 "Conventional Cruise Control" 0 "No Vehicle Speed Control" ;
VAL_TABLE_ PF_MinIdlBstLvlReq 3 "Boost Level 3" 2 "Boost Level 2" 1 "Boost Level 1" 0 "No Boost Requested" ;
VAL_TABLE_ PltfrmEngSpdCmdSysTp 6 "Auto Elevated Idle" 5 "Enhanced Fast Idle" 4 "Fast Idle" 3 "Mobile Variable PTO" 2 "Stationary Variable PTO" 1 "Stationary PTO" 0 "No Platform Eng. Speed Command Sys." ;
VAL_TABLE_ ThrtlPrgrsnReq 2 "Map C" 1 "Map B" 0 "Map A" ;
VAL_TABLE_ PMMAccTrmSt 1 "Active" 0 "Inactive" ;
VAL_TABLE_ PMMRunCrkTrmSt 1 "Active" 0 "Inactive" ;
VAL_TABLE_ SysBkUpPwrMd 3 "Crank Request" 2 "Run" 1 "Accessory" 0 "Off" ;
VAL_TABLE_ SysPwrMd 3 "Crank Request" 2 "Run" 1 "Accessory" 0 "Off" ;
VAL_TABLE_ ImmblzrPreRelPswdStat 1 "Information Valid" 0 "No Information" ;
VAL_TABLE_ AdptCrsGapSwAct 2 "Increase Gap" 1 "Decrease Gap" 0 "No Activation" ;
VAL_TABLE_ CrsCntrlSwStSwDataIntgty 3 "Illegal Range" 2 "Failure Detected" 1 "Data Invalid" 0 "Data Valid" ;
VAL_TABLE_ CrsCntCncRq 1 "Cancel" 0 "Do Not Cancel" ;
VAL_TABLE_ WhlSpdSnsgDTCStat 4 "Diagnostic Failed" 3 "Diagnostic Passed" 2 "No Status to Report" 1 "Critically Disabled" 0 "Not Supported" ;
VAL_TABLE_ SprTireSt 2 "Spare Detected" 1 "No Spare Detected" 0 "Undetermined" ;
VAL_TABLE_ BSTGRReqdGear 10 "Tenth Gear" 9 "Ninth Gear" 8 "Eighth Gear" 7 "Seventh Gear" 6 "Sixth Gear" 5 "Fifth Gear" 4 "Fourth Gear" 3 "Third Gear" 2 "Second Gear" 1 "First Gear" 0 "No Action" ;
VAL_TABLE_ BSTGRReqType 3 "Hold Gear" 2 "Min Gear Request" 1 "Max Gear Request" 0 "No Action" ;
VAL_TABLE_ VhDynCntlSysSt 7 "Driver Disabled" 6 "Enhanced Operation" 5 "Calibrating" 4 "Warming Up" 3 "Permanently Failed" 2 "Temporarily Inhibited" 1 "Reduced Function" 0 "Normal Operation" ;
VAL_TABLE_ TracCntrlSysDrIntnt 1 "Enabled" 0 "Disabled" ;
VAL_TABLE_ MainLghtSw 3 "HEADLAMP" 2 "PARKLAMP" 1 "OFF" 0 "AUTO" ;
VAL_TABLE_ ExhPrsRgVlvPos 1 "Closed" 0 "Open" ;
VAL_TABLE_ CSETRER_TqIntvnTyp 2 "Increase Torque" 1 "Reduce Torque" 0 "No Intervention" ;

BO_ 1798 XCP_DataTransmissionObject2_HS: 8 EPS_HS
 SG_ DgnInf : 7|64@0+ (1,0) [0|1.8446744074e+19] ""  CGM_HS,TestTool_HS

BO_ 1800 XCP_CommandReceiveObject2_HS: 8 CGM_HS
 SG_ DgnInf : 7|64@0+ (1,0) [0|1.8446744074e+19] ""  EPS_HS

BO_ 1808 XCP_DataTransmissionObject1_HS: 8 EPS_HS
 SG_ DgnInf : 7|64@0+ (1,0) [0|1.8446744074e+19] ""  CGM_HS,TestTool_HS

BO_ 1810 XCP_CommandReceiveObject1_HS: 8 CGM_HS
 SG_ DgnInf : 7|64@0+ (1,0) [0|1.8446744074e+19] ""  EPS_HS

BO_ 1015 China_Data_Logger_Info_3_HS: 1 HCP_HS
 SG_ ElecMchnCntlrTemp : 7|8@0+ (1,-40) [-40|215] "deg C"  CGM_HS,TCP_HS,ONSTAR_HS

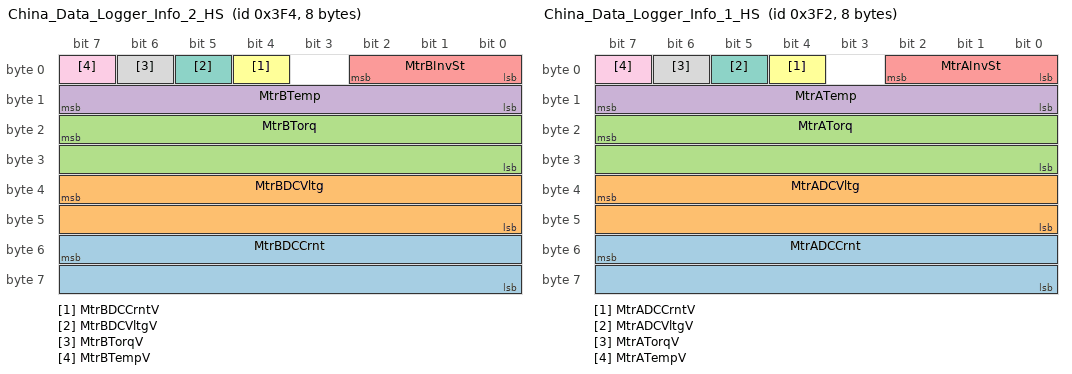
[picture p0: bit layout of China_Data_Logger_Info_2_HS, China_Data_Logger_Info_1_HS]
BO_ 1012 China_Data_Logger_Info_2_HS: 8 HCP_HS
 SG_ MtrBDCCrnt : 55|16@0- (0.05,0) [-1638.4|1638.35] "A"  CGM_HS,TCP_HS,ONSTAR_HS
 SG_ MtrBDCVltg : 39|16@0+ (0.01,0) [0|655.35] "V"  CGM_HS,TCP_HS,ONSTAR_HS
 SG_ MtrBTorq : 23|16@0- (0.125,0) [-4096|4095.875] "Nm"  CGM_HS,TCP_HS,ONSTAR_HS
 SG_ MtrBTemp : 15|8@0+ (1,-40) [-40|215] "deg C"  CGM_HS,TCP_HS,ONSTAR_HS
 SG_ MtrBInvSt : 2|3@0+ (1,0) [0|7] ""  CGM_HS,TCP_HS,ONSTAR_HS
 SG_ MtrBDCCrntV : 4|1@0+ (1,0) [0|1] ""  CGM_HS,TCP_HS,ONSTAR_HS
 SG_ MtrBDCVltgV : 5|1@0+ (1,0) [0|1] ""  CGM_HS,TCP_HS,ONSTAR_HS
 SG_ MtrBTorqV : 6|1@0+ (1,0) [0|1] ""  CGM_HS,TCP_HS,ONSTAR_HS
 SG_ MtrBTempV : 7|1@0+ (1,0) [0|1] ""  CGM_HS,TCP_HS,ONSTAR_HS

BO_ 1010 China_Data_Logger_Info_1_HS: 8 HCP_HS
 SG_ MtrADCCrnt : 55|16@0- (0.05,0) [-1638.4|1638.35] "A"  CGM_HS,TCP_HS,ONSTAR_HS
 SG_ MtrADCVltg : 39|16@0+ (0.01,0) [0|655.35] "V"  CGM_HS,TCP_HS,ONSTAR_HS
 SG_ MtrATorq : 23|16@0- (0.125,0) [-4096|4095.875] "Nm"  CGM_HS,TCP_HS,ONSTAR_HS
 SG_ MtrATemp : 15|8@0+ (1,-40) [-40|215] "deg C"  CGM_HS,TCP_HS,ONSTAR_HS
 SG_ MtrAInvSt : 2|3@0+ (1,0) [0|7] ""  CGM_HS,TCP_HS,ONSTAR_HS
 SG_ MtrADCCrntV : 4|1@0+ (1,0) [0|1] ""  CGM_HS,TCP_HS,ONSTAR_HS
 SG_ MtrADCVltgV : 5|1@0+ (1,0) [0|1] ""  CGM_HS,TCP_HS,ONSTAR_HS
 SG_ MtrATorqV : 6|1@0+ (1,0) [0|1] ""  CGM_HS,TCP_HS,ONSTAR_HS
 SG_ MtrATempV : 7|1@0+ (1,0) [0|1] ""  CGM_HS,TCP_HS,ONSTAR_HS

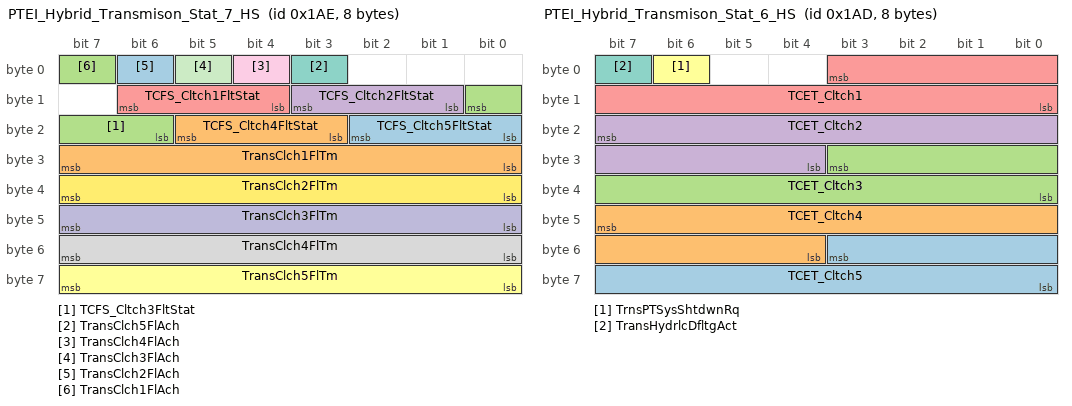
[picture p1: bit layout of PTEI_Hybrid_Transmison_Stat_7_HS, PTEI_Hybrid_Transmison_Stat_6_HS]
BO_ 430 PTEI_Hybrid_Transmison_Stat_7_HS: 8 TCM_HS
 SG_ TCFS_Cltch5FltStat : 18|3@0+ (1,0) [0|7] ""  CGM_HS,HCP_HS
 SG_ TCFS_Cltch4FltStat : 21|3@0+ (1,0) [0|7] ""  CGM_HS,HCP_HS
 SG_ TCFS_Cltch3FltStat : 8|3@0+ (1,0) [0|7] ""  CGM_HS,HCP_HS
 SG_ TCFS_Cltch2FltStat : 11|3@0+ (1,0) [0|7] ""  CGM_HS,HCP_HS
 SG_ TCFS_Cltch1FltStat : 14|3@0+ (1,0) [0|7] ""  CGM_HS,HCP_HS
 SG_ TransClch5FlTm : 63|8@0+ (0.0125,0) [0|3.1875] "s"  CGM_HS,HCP_HS
 SG_ TransClch5FlAch : 3|1@0+ (1,0) [0|1] ""  CGM_HS,HCP_HS
 SG_ TransClch4FlTm : 55|8@0+ (0.0125,0) [0|3.1875] "s"  CGM_HS,HCP_HS
 SG_ TransClch4FlAch : 4|1@0+ (1,0) [0|1] ""  CGM_HS,HCP_HS
 SG_ TransClch3FlTm : 47|8@0+ (0.0125,0) [0|3.1875] "s"  CGM_HS,HCP_HS
 SG_ TransClch3FlAch : 5|1@0+ (1,0) [0|1] ""  CGM_HS,HCP_HS
 SG_ TransClch2FlTm : 39|8@0+ (0.0125,0) [0|3.1875] "s"  CGM_HS,HCP_HS
 SG_ TransClch2FlAch : 6|1@0+ (1,0) [0|1] ""  CGM_HS,HCP_HS
 SG_ TransClch1FlTm : 31|8@0+ (0.0125,0) [0|3.1875] "s"  CGM_HS,HCP_HS
 SG_ TransClch1FlAch : 7|1@0+ (1,0) [0|1] ""  CGM_HS,HCP_HS

BO_ 429 PTEI_Hybrid_Transmison_Stat_6_HS: 8 TCM_HS
 SG_ TCET_Cltch5 : 51|12@0+ (0.5,-5) [-5|2042.5] "Nm"  CGM_HS,HCP_HS
 SG_ TCET_Cltch4 : 47|12@0+ (0.5,-5) [-5|2042.5] "Nm"  CGM_HS,HCP_HS
 SG_ TCET_Cltch3 : 27|12@0+ (0.5,-5) [-5|2042.5] "Nm"  CGM_HS,HCP_HS
 SG_ TCET_Cltch2 : 23|12@0+ (0.5,-5) [-5|2042.5] "Nm"  CGM_HS,HCP_HS
 SG_ TCET_Cltch1 : 3|12@0+ (0.5,-5) [-5|2042.5] "Nm"  CGM_HS,HCP_HS
 SG_ TrnsPTSysShtdwnRq : 6|1@0+ (1,0) [0|1] ""  CGM_HS,HCP_HS
 SG_ TransHydrlcDfltgAct : 7|1@0+ (1,0) [0|1] ""  CGM_HS,HCP_HS

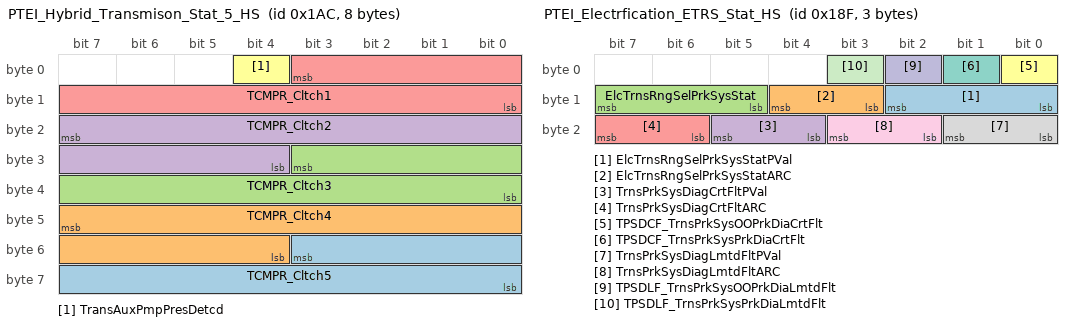
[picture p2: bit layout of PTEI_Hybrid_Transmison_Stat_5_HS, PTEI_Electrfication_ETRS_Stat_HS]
BO_ 428 PTEI_Hybrid_Transmison_Stat_5_HS: 8 HCP_HS
 SG_ TCMPR_Cltch5 : 51|12@0+ (0.5,0) [0|2047.5] "kPa"  CGM_HS,TCM_HS
 SG_ TCMPR_Cltch4 : 47|12@0+ (0.5,0) [0|2047.5] "kPa"  CGM_HS,TCM_HS
 SG_ TCMPR_Cltch3 : 27|12@0+ (0.5,0) [0|2047.5] "kPa"  CGM_HS,TCM_HS
 SG_ TCMPR_Cltch2 : 23|12@0+ (0.5,0) [0|2047.5] "kPa"  CGM_HS,TCM_HS
 SG_ TCMPR_Cltch1 : 3|12@0+ (0.5,0) [0|2047.5] "kPa"  CGM_HS,TCM_HS
 SG_ TransAuxPmpPresDetcd : 4|1@0+ (1,0) [0|1] ""  CGM_HS,TCM_HS

BO_ 427 PTEI_Hybrid_Transmison_Stat_4_HS: 7 HCP_HS
 SG_ TransActlRngStPVal : 53|6@0+ (1,0) [0|63] ""  CGM_HS,ECM_HS
 SG_ TransActlRngStARC : 47|2@0+ (1,0) [0|3] ""  CGM_HS,ECM_HS
 SG_ TARS_TransActRngV : 40|1@0+ (1,0) [0|1] ""  CGM_HS,ECM_HS
 SG_ TARS_TransActRngM : 41|1@0+ (1,0) [0|1] ""  CGM_HS,ECM_HS
 SG_ TARS_TransActRng : 45|4@0+ (1,0) [0|15] ""  CGM_HS,ECM_HS
 SG_ TrnsEgdPrFlwInfPVal : 35|4@0+ (1,0) [0|15] ""  CGM_HS,ECM_HS
 SG_ TrnsEgdPrFlwInfARC : 55|2@0+ (1,0) [0|3] ""  CGM_HS,ECM_HS
 SG_ TEPI_TrnsEngdPrFlwStV : 36|1@0+ (1,0) [0|1] ""  CGM_HS,ECM_HS
 SG_ TEPI_TrnsEngdPrFlwSt : 39|3@0+ (1,0) [0|7] ""  CGM_HS,ECM_HS
 SG_ TransCltchCntlARC : 25|2@0+ (1,0) [0|3] ""  CGM_HS,TCM_HS
 SG_ TransCltch5FillCmd : 15|2@0+ (1,0) [0|3] ""  CGM_HS,TCM_HS
 SG_ TransCltch5CntlRqPVal : 27|2@0+ (1,0) [0|3] ""  CGM_HS,TCM_HS
 SG_ TransCltch5CntlRq : 21|2@0+ (1,0) [0|3] ""  CGM_HS,TCM_HS
 SG_ TransCltch4FillCmd : 1|2@0+ (1,0) [0|3] ""  CGM_HS,TCM_HS
 SG_ TransCltch4CntlRqPVal : 29|2@0+ (1,0) [0|3] ""  CGM_HS,TCM_HS
 SG_ TransCltch4CntlRq : 23|2@0+ (1,0) [0|3] ""  CGM_HS,TCM_HS
 SG_ TransCltch3FillCmd : 3|2@0+ (1,0) [0|3] ""  CGM_HS,TCM_HS
 SG_ TransCltch3CntlRqPVal : 31|2@0+ (1,0) [0|3] ""  CGM_HS,TCM_HS
 SG_ TransCltch3CntlRq : 9|2@0+ (1,0) [0|3] ""  CGM_HS,TCM_HS
 SG_ TransCltch2FillCmd : 5|2@0+ (1,0) [0|3] ""  CGM_HS,TCM_HS
 SG_ TransCltch2CntlRqPVal : 17|2@0+ (1,0) [0|3] ""  CGM_HS,TCM_HS
 SG_ TransCltch2CntlRq : 11|2@0+ (1,0) [0|3] ""  CGM_HS,TCM_HS
 SG_ TransCltch1FillCmd : 7|2@0+ (1,0) [0|3] ""  CGM_HS,TCM_HS
 SG_ TransCltch1CntlRqPVal : 19|2@0+ (1,0) [0|3] ""  CGM_HS,TCM_HS
 SG_ TransCltch1CntlRq : 13|2@0+ (1,0) [0|3] ""  CGM_HS,TCM_HS

BO_ 399 PTEI_Electrfication_ETRS_Stat_HS: 3 TCM_HS
 SG_ ElcTrnsRngSelPrkSysStatPVal : 10|3@0+ (1,0) [0|7] ""  HCP_HS,CGM_HS
 SG_ ElcTrnsRngSelPrkSysStatARC : 12|2@0+ (1,0) [0|3] ""  HCP_HS,CGM_HS
 SG_ ElcTrnsRngSelPrkSysStat : 15|3@0+ (1,0) [0|7] ""  HCP_HS,CGM_HS
 SG_ TrnsPrkSysDiagCrtFltPVal : 21|2@0+ (1,0) [0|3] ""  CGM_HS,HCP_HS
 SG_ TrnsPrkSysDiagCrtFltARC : 23|2@0+ (1,0) [0|3] ""  CGM_HS,HCP_HS
 SG_ TPSDCF_TrnsPrkSysOOPrkDiaCrtFlt : 0|1@0+ (1,0) [0|1] ""  CGM_HS,HCP_HS
 SG_ TPSDCF_TrnsPrkSysPrkDiaCrtFlt : 1|1@0+ (1,0) [0|1] ""  CGM_HS,HCP_HS
 SG_ TrnsPrkSysDiagLmtdFltPVal : 17|2@0+ (1,0) [0|3] ""  CGM_HS,HCP_HS
 SG_ TrnsPrkSysDiagLmtdFltARC : 19|2@0+ (1,0) [0|3] ""  CGM_HS,HCP_HS
 SG_ TPSDLF_TrnsPrkSysOOPrkDiaLmtdFlt : 2|1@0+ (1,0) [0|1] ""  CGM_HS,HCP_HS
 SG_ TPSDLF_TrnsPrkSysPrkDiaLmtdFlt : 3|1@0+ (1,0) [0|1] ""  CGM_HS,HCP_HS

BO_ 1236 PPEI_CGM_General_Status_2_HS: 2 CGM_HS
 SG_ CGMCII_DataVal : 15|8@0+ (1,0) [0|255] ""  ECM_HS
 SG_ CGMCII_DataIndx : 4|5@0+ (1,0) [0|31] ""  ECM_HS
 SG_ CGMCII_DataStat : 5|1@0+ (1,0) [0|1] ""  ECM_HS

BO_ 975 PPEI_CGM_General_Status_HS: 2 CGM_HS
 SG_ CGMDS2_DTCStat : 10|3@0+ (1,0) [0|7] ""  ECM_HS
 SG_ CGMDS2_DTCIndx : 15|5@0+ (1,0) [0|31] ""  ECM_HS
 SG_ CGMDS1_DTCStat : 2|3@0+ (1,0) [0|7] ""  BSM_HS,VITM_OBD_HS,TCM_HS,VICM_HS,ICCM_B_HS,ICCM_OBD_HS,ICCM_HS,HCP_T_HS,HCP_HS,HCP_B_HS,GPCM_HS,FICM_HS,EBOOST_OBD_HS,EBCM_OBD_HS,EBCM_HS,BCP_HS,ECM_HS
 SG_ CGMDS1_DTCIndx : 7|5@0+ (1,0) [0|31] ""  BSM_HS,VITM_OBD_HS,TCM_HS,VICM_HS,ICCM_B_HS,ICCM_OBD_HS,ICCM_HS,HCP_T_HS,HCP_HS,HCP_B_HS,GPCM_HS,FICM_HS,EBOOST_OBD_HS,EBCM_OBD_HS,EBCM_HS,BCP_HS,ECM_HS

BO_ 504 PTEI_General_Status_5_HS: 2 ECM_HS
 SG_ EngCylDsrdFirngFractn : 7|8@0+ (0.00390625,0) [0|0.99609375] ""  CGM_HS,TCM_HS
 SG_ EngCylCalcFirngFractn : 15|8@0+ (0.00390625,0) [0|0.99609375] ""  CGM_HS,TCM_HS

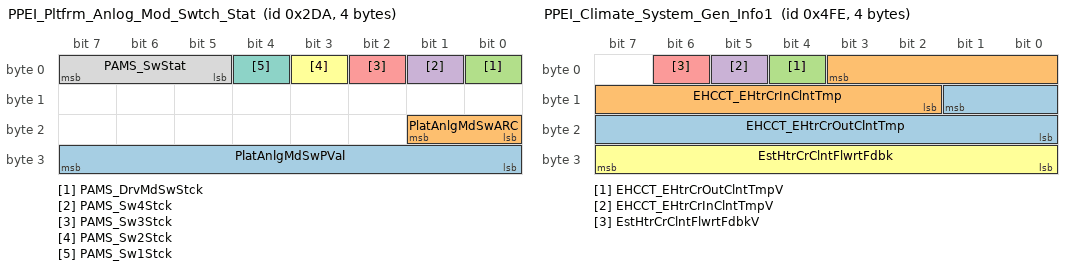
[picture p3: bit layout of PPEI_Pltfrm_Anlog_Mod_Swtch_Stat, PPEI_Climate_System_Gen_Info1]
BO_ 730 PPEI_Pltfrm_Anlog_Mod_Swtch_Stat: 4 ECM_HS
 SG_ PlatAnlgMdSwPVal : 31|8@0+ (1,0) [0|255] ""  CGM_HS,TCCM_HS
 SG_ PlatAnlgMdSwARC : 17|2@0+ (1,0) [0|3] ""  CGM_HS,TCCM_HS
 SG_ PAMS_DrvMdSwStck : 0|1@0+ (1,0) [0|1] ""  CGM_HS,TCCM_HS
 SG_ PAMS_Sw4Stck : 1|1@0+ (1,0) [0|1] ""  CGM_HS,TCCM_HS
 SG_ PAMS_Sw3Stck : 2|1@0+ (1,0) [0|1] ""  CGM_HS,TCCM_HS
 SG_ PAMS_Sw2Stck : 3|1@0+ (1,0) [0|1] ""  CGM_HS,TCCM_HS
 SG_ PAMS_Sw1Stck : 4|1@0+ (1,0) [0|1] ""  CGM_HS,TCCM_HS
 SG_ PAMS_SwStat : 7|3@0+ (1,0) [0|7] ""  CGM_HS,TCCM_HS

BO_ 1278 PPEI_Climate_System_Gen_Info1: 4 ECM_HS
 SG_ EHCCT_EHtrCrOutClntTmp : 9|10@0+ (0.1857,-40) [-40|149.9711] "DegC"  CGM_HS,BCM_HS
 SG_ EHCCT_EHtrCrInClntTmp : 3|10@0+ (0.1857,-40) [-40|149.9711] "DegC"  CGM_HS,BCM_HS
 SG_ EHCCT_EHtrCrOutClntTmpV : 4|1@0+ (1,0) [0|1] ""  CGM_HS,BCM_HS
 SG_ EHCCT_EHtrCrInClntTmpV : 5|1@0+ (1,0) [0|1] ""  CGM_HS,BCM_HS
 SG_ EstHtrCrClntFlwrtFdbkV : 6|1@0+ (1,0) [0|1] ""  CGM_HS,BCM_HS
 SG_ EstHtrCrClntFlwrtFdbk : 31|8@0+ (0.2509,0) [0|63.9795] "l/min"  CGM_HS,BCM_HS

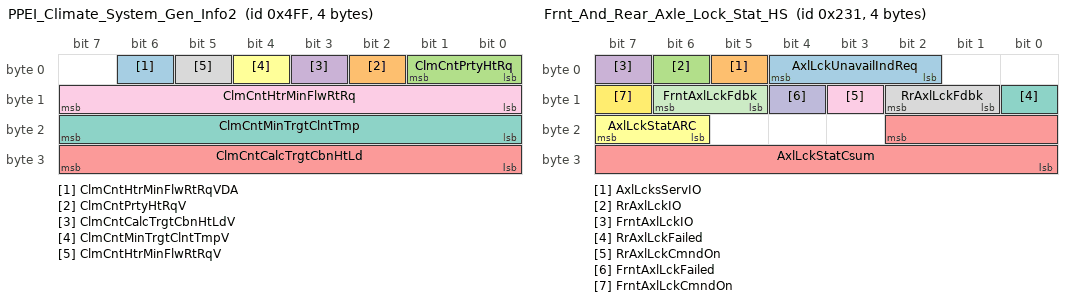
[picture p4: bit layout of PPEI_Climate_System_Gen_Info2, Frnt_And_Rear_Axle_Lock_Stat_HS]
BO_ 1279 PPEI_Climate_System_Gen_Info2: 4 BCM_HS
 SG_ ClmCntHtrMinFlwRtRqVDA : 6|1@0+ (1,0) [0|1] ""  CGM_HS,ECM_HS
 SG_ ClmCntPrtyHtRqV : 2|1@0+ (1,0) [0|1] ""  CGM_HS,ECM_HS
 SG_ ClmCntPrtyHtRq : 1|2@0+ (1,0) [0|3] ""  CGM_HS,ECM_HS
 SG_ ClmCntCalcTrgtCbnHtLdV : 3|1@0+ (1,0) [0|1] ""  CGM_HS,ECM_HS
 SG_ ClmCntCalcTrgtCbnHtLd : 31|8@0+ (0.12549,0) [0|32] "kW"  CGM_HS,ECM_HS
 SG_ ClmCntMinTrgtClntTmpV : 4|1@0+ (1,0) [0|1] ""  CGM_HS,ECM_HS
 SG_ ClmCntMinTrgtClntTmp : 23|8@0+ (0.39216,0) [0|100.0008] "degC"  CGM_HS,ECM_HS
 SG_ ClmCntHtrMinFlwRtRqV : 5|1@0+ (1,0) [0|1] ""  CGM_HS,ECM_HS
 SG_ ClmCntHtrMinFlwRtRq : 15|8@0+ (0.25098,0) [0|63.9999] "l/min"  CGM_HS,ECM_HS

BO_ 561 Frnt_And_Rear_Axle_Lock_Stat_HS: 4 ICCM_HS
 SG_ AxlLckUnavailIndReq : 4|3@0+ (1,0) [0|7] ""  CGM_HS,BCM_HS,TCCM_HS,EBCM_OBD_HS,EBCM_HS
 SG_ AxlLcksServIO : 5|1@0+ (1,0) [0|1] ""  CGM_HS,BCM_HS,TCCM_HS,EBCM_OBD_HS,EBCM_HS
 SG_ RrAxlLckIO : 6|1@0+ (1,0) [0|1] ""  CGM_HS,BCM_HS,TCCM_HS,EBCM_OBD_HS,EBCM_HS
 SG_ FrntAxlLckIO : 7|1@0+ (1,0) [0|1] ""  CGM_HS,BCM_HS,TCCM_HS,EBCM_OBD_HS,EBCM_HS
 SG_ AxlLckStatCsum : 18|11@0+ (1,0) [0|2047] ""  CGM_HS,TCCM_HS,EBCM_OBD_HS,EBCM_HS
 SG_ AxlLckStatARC : 23|2@0+ (1,0) [0|3] ""  CGM_HS,TCCM_HS,EBCM_OBD_HS,EBCM_HS
 SG_ RrAxlLckFailed : 8|1@0+ (1,0) [0|1] ""  CGM_HS,TCCM_HS,EBCM_OBD_HS,EBCM_HS
 SG_ RrAxlLckFdbk : 10|2@0+ (1,0) [0|3] ""  CGM_HS,TCCM_HS,EBCM_OBD_HS,EBCM_HS
 SG_ RrAxlLckCmndOn : 11|1@0+ (1,0) [0|1] ""  CGM_HS,TCCM_HS,EBCM_OBD_HS,EBCM_HS
 SG_ FrntAxlLckFailed : 12|1@0+ (1,0) [0|1] ""  CGM_HS,TCCM_HS,EBCM_OBD_HS,EBCM_HS
 SG_ FrntAxlLckFdbk : 14|2@0+ (1,0) [0|3] ""  CGM_HS,TCCM_HS,EBCM_OBD_HS,EBCM_HS
 SG_ FrntAxlLckCmndOn : 15|1@0+ (1,0) [0|1] ""  CGM_HS,TCCM_HS,EBCM_OBD_HS,EBCM_HS

BO_ 573 OTA_Electric_Pwr_Readiness_HS: 1 BCM_HS
 SG_ RmtRflshElecPwrRdness : 7|8@0+ (0.025,0) [0|6.375] "AmpHour"  HMIM_HS,CGM_HS

BO_ 1276 PPEI_OBD_Climate_Sys_Gen_Info_1: 2 ECM_HS
 SG_ CCFrBlwFnSpdFbkRatV : 0|1@0+ (1,0) [0|1] ""  CGM_HS,BCM_HS
 SG_ CCFrBlwFnSpdFbkRat : 15|8@0+ (0.392157,0) [0|100.000035] "%"  CGM_HS,BCM_HS

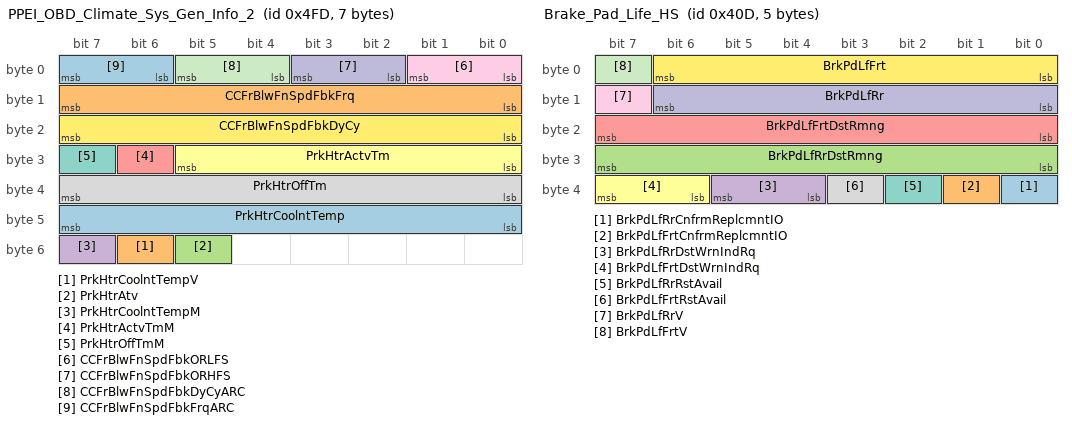
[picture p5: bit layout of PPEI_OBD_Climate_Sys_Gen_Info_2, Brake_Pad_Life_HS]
BO_ 1277 PPEI_OBD_Climate_Sys_Gen_Info_2: 7 BCM_HS
 SG_ PrkHtrCoolntTemp : 47|8@0+ (1,-40) [-40|215] "deg C"  CGM_HS,ECM_HS
 SG_ PrkHtrCoolntTempV : 54|1@0+ (1,0) [0|1] ""  CGM_HS,ECM_HS
 SG_ PrkHtrAtv : 53|1@0+ (1,0) [0|1] ""  CGM_HS,ECM_HS
 SG_ PrkHtrCoolntTempM : 55|1@0+ (1,0) [0|1] ""  CGM_HS,ECM_HS
 SG_ PrkHtrActvTmM : 30|1@0+ (1,0) [0|1] ""  ECM_HS,CGM_HS
 SG_ PrkHtrActvTm : 29|6@0+ (1,0) [0|63] "min"  ECM_HS,CGM_HS
 SG_ PrkHtrOffTmM : 31|1@0+ (1,0) [0|1] ""  ECM_HS,CGM_HS
 SG_ PrkHtrOffTm : 39|8@0+ (2,0) [0|510] "min"  ECM_HS,CGM_HS
 SG_ CCFrBlwFnSpdFbkORLFS : 1|2@0+ (1,0) [0|3] ""  CGM_HS,ECM_HS
 SG_ CCFrBlwFnSpdFbkORHFS : 3|2@0+ (1,0) [0|3] ""  CGM_HS,ECM_HS
 SG_ CCFrBlwFnSpdFbkDyCyARC : 5|2@0+ (1,0) [0|3] ""  CGM_HS,ECM_HS
 SG_ CCFrBlwFnSpdFbkDyCy : 23|8@0+ (0.392157,0) [0|100.000035] "%"  CGM_HS,ECM_HS
 SG_ CCFrBlwFnSpdFbkFrqARC : 7|2@0+ (1,0) [0|3] ""  CGM_HS,ECM_HS
 SG_ CCFrBlwFnSpdFbkFrq : 15|8@0+ (1.568627,0) [0|399.999885] "Hz"  CGM_HS,ECM_HS

BO_ 1195 PTEI_Actve_Thml_Mgmt_Gen_Info_HS: 3 TCM_HS
 SG_ TransTempOpRgn : 2|3@0+ (1,0) [0|7] ""  CGM_HS,ECM_HS
 SG_ TransOilTempAltValV : 3|1@0+ (1,0) [0|1] ""  CGM_HS,ECM_HS
 SG_ TransOilTempAltValM : 4|1@0+ (1,0) [0|1] ""  CGM_HS,ECM_HS
 SG_ TransOilTempAltVal : 15|8@0+ (1,-40) [-40|215] "deg C"  CGM_HS,ECM_HS
 SG_ TransOilTgtTemp : 23|8@0+ (1,-40) [-40|215] "deg C"  CGM_HS,ECM_HS

BO_ 1037 Brake_Pad_Life_HS: 5 EBCM_HS
 SG_ BrkPdLfRrCnfrmReplcmntIO : 32|1@0+ (1,0) [0|1] ""  BCM_HS,CGM_HS
 SG_ BrkPdLfFrtCnfrmReplcmntIO : 33|1@0+ (1,0) [0|1] ""  BCM_HS,CGM_HS
 SG_ BrkPdLfRrDstRmng : 31|8@0+ (100,0) [0|25500] ""  CGM_HS,BCM_HS
 SG_ BrkPdLfRrDstWrnIndRq : 37|2@0+ (1,0) [0|3] ""  CGM_HS,BCM_HS
 SG_ BrkPdLfFrtDstRmng : 23|8@0+ (100,0) [0|25500] ""  CGM_HS,BCM_HS
 SG_ BrkPdLfFrtDstWrnIndRq : 39|2@0+ (1,0) [0|3] ""  CGM_HS,BCM_HS
 SG_ BrkPdLfRrRstAvail : 34|1@0+ (1,0) [0|1] ""  CGM_HS,BCM_HS
 SG_ BrkPdLfFrtRstAvail : 35|1@0+ (1,0) [0|1] ""  CGM_HS,BCM_HS
 SG_ BrkPdLfRrV : 15|1@0+ (1,0) [0|1] ""  CGM_HS,BCM_HS
 SG_ BrkPdLfRr : 14|7@0+ (1,0) [0|127] "%"  CGM_HS,BCM_HS
 SG_ BrkPdLfFrtV : 7|1@0+ (1,0) [0|1] ""  CGM_HS,BCM_HS
 SG_ BrkPdLfFrt : 6|7@0+ (1,0) [0|127] "%"  CGM_HS,BCM_HS

BO_ 292 Auto_Vehicle_Mode_Info_HS: 2 HMIM_HS
 SG_ TrlrStTwHlMdOvrd : 7|2@0+ (1,0) [0|3] ""  ECM_HS
 SG_ AutoVehMdCmdPVal : 13|6@0+ (1,0) [0|63] ""  ECM_HS
 SG_ AutoVehMdCmdARC : 15|2@0+ (1,0) [0|3] ""  ECM_HS
 SG_ AVMC_MdReqstd : 4|5@0+ (1,0) [0|31] ""  ECM_HS
 SG_ AVMC_MdFtrEnbld : 5|1@0+ (1,0) [0|1] ""  ECM_HS

BO_ 40 Temp_Diag_CAN_Req_HS_028: 8 CGM_HS
 SG_ DgnInf : 7|64@0+ (1,0) [0|1.8446744074e+19] ""  Dummy_HS

BO_ 808 Temp_Diag_CAN_Resp_HS_328: 8 Dummy_HS
 SG_ DgnInf : 7|64@0+ (1,0) [0|1.8446744074e+19] ""  CGM_HS

BO_ 569 Performan_Mode_Cust_Setings_3_HS: 3 EBCM_HS
 SG_ CrwlModeDndRsnIndReq : 15|3@0+ (1,0) [0|7] ""  CGM_HS,BCM_HS
 SG_ LnchCtrlBrkPresVal : 3|4@0+ (10,0) [0|150] "%"  CGM_HS,BCM_HS
 SG_ LnchCtrlTmrVal : 7|4@0+ (1,0) [0|15] ""  CGM_HS,BCM_HS

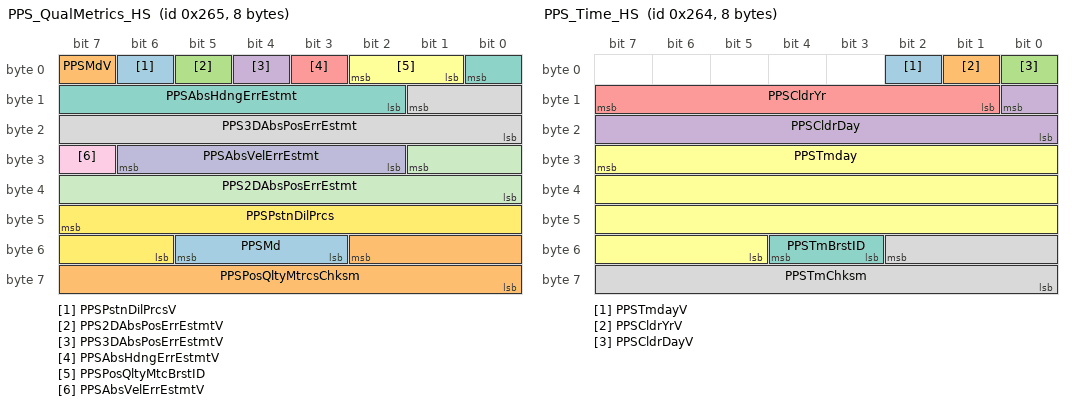
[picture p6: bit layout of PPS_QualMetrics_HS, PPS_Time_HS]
BO_ 613 PPS_QualMetrics_HS: 8 ONSTAR_HS
 SG_ PPSPstnDilPrcsV : 6|1@0+ (1,0) [0|1] ""  EOCM2B_IMX6_HS,EOCM2A_IMX6_HS,V2V_HS,CSM_HS,EOCM2B_K1_HS,EOCM2A_K1_HS,CGM_HS
 SG_ PPSMdV : 7|1@0+ (1,0) [0|1] ""  EOCM2B_IMX6_HS,EOCM2A_IMX6_HS,V2V_HS,CSM_HS,EOCM2B_K1_HS,EOCM2A_K1_HS,CGM_HS
 SG_ PPS2DAbsPosErrEstmtV : 5|1@0+ (1,0) [0|1] ""  EOCM2B_IMX6_HS,EOCM2A_IMX6_HS,V2V_HS,CSM_HS,EOCM2B_K1_HS,EOCM2A_K1_HS,CGM_HS
 SG_ PPS3DAbsPosErrEstmtV : 4|1@0+ (1,0) [0|1] ""  EOCM2B_IMX6_HS,EOCM2A_IMX6_HS,V2V_HS,CSM_HS,EOCM2B_K1_HS,EOCM2A_K1_HS,CGM_HS
 SG_ PPSAbsHdngErrEstmtV : 3|1@0+ (1,0) [0|1] ""  EOCM2B_IMX6_HS,EOCM2A_IMX6_HS,V2V_HS,CSM_HS,EOCM2B_K1_HS,EOCM2A_K1_HS,CGM_HS
 SG_ PPSPosQltyMtcBrstID : 2|2@0+ (1,0) [0|3] ""  EOCM2B_IMX6_HS,EOCM2A_IMX6_HS,V2V_HS,CSM_HS,EOCM2B_K1_HS,EOCM2A_K1_HS,CGM_HS
 SG_ PPSAbsHdngErrEstmt : 0|7@0+ (0.5,0) [0|63.5] ""  EOCM2B_IMX6_HS,EOCM2A_IMX6_HS,V2V_HS,CSM_HS,EOCM2B_K1_HS,EOCM2A_K1_HS,CGM_HS
 SG_ PPS3DAbsPosErrEstmt : 9|10@0+ (0.1,0) [0|102.3] ""  EOCM2B_IMX6_HS,EOCM2A_IMX6_HS,V2V_HS,CSM_HS,EOCM2B_K1_HS,EOCM2A_K1_HS,CGM_HS
 SG_ PPSAbsVelErrEstmtV : 31|1@0+ (1,0) [0|1] ""  EOCM2B_IMX6_HS,EOCM2A_IMX6_HS,V2V_HS,CSM_HS,EOCM2B_K1_HS,EOCM2A_K1_HS,CGM_HS
 SG_ PPSAbsVelErrEstmt : 30|5@0+ (1,0) [0|31] ""  EOCM2B_IMX6_HS,EOCM2A_IMX6_HS,V2V_HS,CSM_HS,EOCM2B_K1_HS,EOCM2A_K1_HS,CGM_HS
 SG_ PPS2DAbsPosErrEstmt : 25|10@0+ (0.1,0) [0|102.3] ""  EOCM2B_IMX6_HS,EOCM2A_IMX6_HS,V2V_HS,CSM_HS,EOCM2B_K1_HS,EOCM2A_K1_HS,CGM_HS
 SG_ PPSPstnDilPrcs : 47|10@0+ (0.1,0) [0|102.3] ""  EOCM2B_IMX6_HS,EOCM2A_IMX6_HS,V2V_HS,CSM_HS,EOCM2B_K1_HS,EOCM2A_K1_HS,CGM_HS
 SG_ PPSMd : 53|3@0+ (1,0) [0|7] ""  EOCM2B_IMX6_HS,EOCM2A_IMX6_HS,V2V_HS,CSM_HS,EOCM2B_K1_HS,EOCM2A_K1_HS,CGM_HS
 SG_ PPSPosQltyMtrcsChksm : 50|11@0+ (1,0) [0|2047] ""  EOCM2B_IMX6_HS,EOCM2A_IMX6_HS,V2V_HS,CSM_HS,EOCM2B_K1_HS,EOCM2A_K1_HS,CGM_HS

BO_ 612 PPS_Time_HS: 8 ONSTAR_HS
 SG_ PPSTmdayV : 2|1@0+ (1,0) [0|1] ""  EOCM2B_IMX6_HS,EOCM2A_IMX6_HS,ECM_HS,V2V_HS,CSM_HS,EOCM2B_K1_HS,EOCM2A_K1_HS,CGM_HS
 SG_ PPSCldrYrV : 1|1@0+ (1,0) [0|1] ""  EOCM2B_IMX6_HS,EOCM2A_IMX6_HS,ECM_HS,V2V_HS,CSM_HS,EOCM2B_K1_HS,EOCM2A_K1_HS,CGM_HS
 SG_ PPSCldrDayV : 0|1@0+ (1,0) [0|1] ""  EOCM2B_IMX6_HS,EOCM2A_IMX6_HS,ECM_HS,V2V_HS,CSM_HS,EOCM2B_K1_HS,EOCM2A_K1_HS,CGM_HS
 SG_ PPSCldrDay : 8|9@0+ (1,0) [0|511] ""  EOCM2B_IMX6_HS,EOCM2A_IMX6_HS,ECM_HS,V2V_HS,CSM_HS,EOCM2B_K1_HS,EOCM2A_K1_HS,CGM_HS
 SG_ PPSCldrYr : 15|7@0+ (1,2014) [2014|2141] ""  EOCM2B_IMX6_HS,EOCM2A_IMX6_HS,ECM_HS,V2V_HS,CSM_HS,EOCM2B_K1_HS,EOCM2A_K1_HS,CGM_HS
 SG_ PPSTmday : 31|27@0+ (1,0) [0|134217727] "ms"  EOCM2B_IMX6_HS,EOCM2A_IMX6_HS,ECM_HS,V2V_HS,CSM_HS,EOCM2B_K1_HS,EOCM2A_K1_HS,CGM_HS
 SG_ PPSTmBrstID : 52|2@0+ (1,0) [0|3] ""  EOCM2B_IMX6_HS,EOCM2A_IMX6_HS,V2V_HS,CSM_HS,EOCM2B_K1_HS,EOCM2A_K1_HS,CGM_HS
 SG_ PPSTmChksm : 50|11@0+ (1,0) [0|2047] ""  EOCM2B_IMX6_HS,EOCM2A_IMX6_HS,V2V_HS,CSM_HS,EOCM2B_K1_HS,EOCM2A_K1_HS,CGM_HS

BO_ 611 PPS_SigAcqTime_HS: 6 ONSTAR_HS
 SG_ PPSSigAcqTmV : 39|1@0+ (1,0) [0|1] ""  EOCM2B_IMX6_HS,EOCM2A_IMX6_HS,V2V_HS,CSM_HS,EOCM2B_K1_HS,EOCM2A_K1_HS,CGM_HS
 SG_ PPSSigAqTmBrstID : 38|2@0+ (1,0) [0|3] ""  EOCM2B_IMX6_HS,EOCM2A_IMX6_HS,V2V_HS,CSM_HS,EOCM2B_K1_HS,EOCM2A_K1_HS,CGM_HS
 SG_ PPSSigAcqTm : 7|32@0+ (1,0) [0|-1] ""  EOCM2B_IMX6_HS,EOCM2A_IMX6_HS,V2V_HS,CSM_HS,EOCM2B_K1_HS,EOCM2A_K1_HS,CGM_HS
 SG_ PPSSigAqTmChksm : 34|11@0+ (1,0) [0|2047] ""  EOCM2B_IMX6_HS,EOCM2A_IMX6_HS,V2V_HS,CSM_HS,EOCM2B_K1_HS,EOCM2A_K1_HS,CGM_HS

BO_ 610 PPS_PosLong_HS: 6 ONSTAR_HS
 SG_ PPSLongBrstID : 39|2@0+ (1,0) [0|3] ""  EOCM2B_IMX6_HS,EOCM2A_IMX6_HS,V2V_HS,CSM_HS,EOCM2B_K1_HS,EOCM2A_K1_HS,CGM_HS
 SG_ PPSLong : 6|31@0- (1,0) [-1073741824|1073741823] ""  EOCM2B_IMX6_HS,EOCM2A_IMX6_HS,V2V_HS,CSM_HS,EOCM2B_K1_HS,EOCM2A_K1_HS,CGM_HS
 SG_ PPSLongV : 7|1@0+ (1,0) [0|1] ""  EOCM2B_IMX6_HS,EOCM2A_IMX6_HS,V2V_HS,CSM_HS,EOCM2B_K1_HS,EOCM2A_K1_HS,CGM_HS
 SG_ PPSLongChksm : 34|11@0+ (1,0) [0|2047] ""  EOCM2B_IMX6_HS,EOCM2A_IMX6_HS,V2V_HS,CSM_HS,EOCM2B_K1_HS,EOCM2A_K1_HS,CGM_HS

BO_ 609 PPS_PosLat_HS: 6 ONSTAR_HS
 SG_ PPSLat : 5|30@0- (1,0) [-536870912|536870911] ""  EOCM2B_IMX6_HS,EOCM2A_IMX6_HS,V2V_HS,CSM_HS,EOCM2B_K1_HS,EOCM2A_K1_HS,CGM_HS
 SG_ PPSLatBrstID : 36|2@0+ (1,0) [0|3] ""  EOCM2B_IMX6_HS,EOCM2A_IMX6_HS,V2V_HS,CSM_HS,EOCM2B_K1_HS,EOCM2A_K1_HS,CGM_HS
 SG_ PPSLatV : 7|1@0+ (1,0) [0|1] ""  EOCM2B_IMX6_HS,EOCM2A_IMX6_HS,V2V_HS,CSM_HS,EOCM2B_K1_HS,EOCM2A_K1_HS,CGM_HS
 SG_ PPSLatChksm : 34|11@0+ (1,0) [0|2047] ""  EOCM2B_IMX6_HS,EOCM2A_IMX6_HS,V2V_HS,CSM_HS,EOCM2B_K1_HS,EOCM2A_K1_HS,CGM_HS

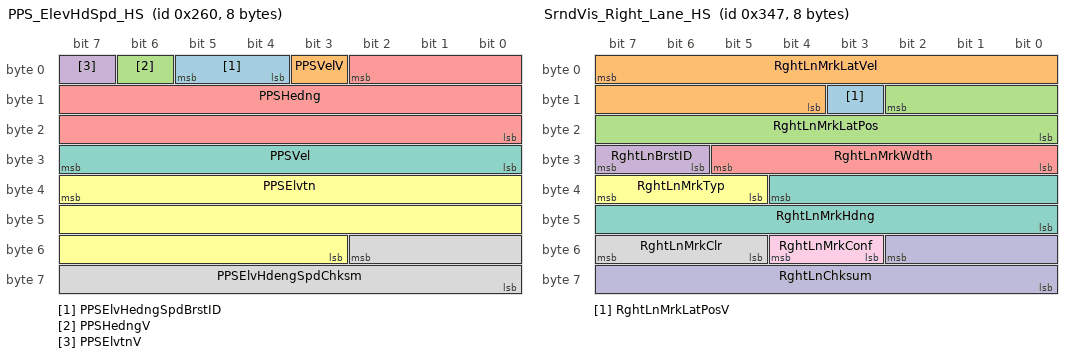
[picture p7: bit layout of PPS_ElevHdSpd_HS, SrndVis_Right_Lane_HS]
BO_ 608 PPS_ElevHdSpd_HS: 8 ONSTAR_HS
 SG_ PPSElvHedngSpdBrstID : 5|2@0+ (1,0) [0|3] ""  EOCM2B_IMX6_HS,EOCM2A_IMX6_HS,V2V_HS,CSM_HS,EOCM2B_K1_HS,EOCM2A_K1_HS,CGM_HS
 SG_ PPSVelV : 3|1@0+ (1,0) [0|1] ""  EOCM2B_IMX6_HS,EOCM2A_IMX6_HS,V2V_HS,CSM_HS,EOCM2B_K1_HS,EOCM2A_K1_HS,CGM_HS
 SG_ PPSHedngV : 6|1@0+ (1,0) [0|1] ""  EOCM2B_IMX6_HS,EOCM2A_IMX6_HS,V2V_HS,CSM_HS,EOCM2B_K1_HS,EOCM2A_K1_HS,CGM_HS
 SG_ PPSElvtnV : 7|1@0+ (1,0) [0|1] ""  EOCM2B_IMX6_HS,EOCM2A_IMX6_HS,V2V_HS,CSM_HS,EOCM2B_K1_HS,EOCM2A_K1_HS,CGM_HS
 SG_ PPSHedng : 2|19@0+ (0.001,0) [0|524.287] "deg"  EOCM2B_IMX6_HS,EOCM2A_IMX6_HS,V2V_HS,CSM_HS,EOCM2B_K1_HS,EOCM2A_K1_HS,CGM_HS
 SG_ PPSElvtn : 39|21@0+ (1,-100000) [-100000|1997151] "cm"  EOCM2B_IMX6_HS,EOCM2A_IMX6_HS,V2V_HS,CSM_HS,EOCM2B_K1_HS,EOCM2A_K1_HS,CGM_HS
 SG_ PPSVel : 31|8@0+ (1,0) [0|255] "km / h"  EOCM2B_IMX6_HS,EOCM2A_IMX6_HS,V2V_HS,CSM_HS,EOCM2B_K1_HS,EOCM2A_K1_HS,CGM_HS
 SG_ PPSElvHdengSpdChksm : 50|11@0+ (1,0) [0|2047] ""  EOCM2B_IMX6_HS,EOCM2A_IMX6_HS,V2V_HS,CSM_HS,EOCM2B_K1_HS,EOCM2A_K1_HS,CGM_HS

BO_ 839 SrndVis_Right_Lane_HS: 8 VPM_HS
 SG_ RghtLnMrkLatPosV : 11|1@0+ (1,0) [0|1] ""  EOCM2B_IMX6_HS,EOCM2A_IMX6_HS,EOCM2B_K1_HS,EOCM2A_K1_HS,CGM_HS
 SG_ RghtLnMrkLatVel : 7|12@0- (0.01,0) [-20.48|20.47] ""  EOCM2B_IMX6_HS,EOCM2A_IMX6_HS,EOCM2B_K1_HS,EOCM2A_K1_HS,CGM_HS
 SG_ RghtLnMrkLatPos : 10|11@0- (0.01,0) [-10.24|10.23] ""  EOCM2B_IMX6_HS,EOCM2A_IMX6_HS,EOCM2B_K1_HS,EOCM2A_K1_HS,CGM_HS
 SG_ RghtLnBrstID : 31|2@0+ (1,0) [0|3] ""  EOCM2B_IMX6_HS,EOCM2A_IMX6_HS,EOCM2B_K1_HS,EOCM2A_K1_HS,CGM_HS
 SG_ RghtLnMrkWdth : 29|6@0+ (0.01,0) [0|0.63] ""  EOCM2B_IMX6_HS,EOCM2A_IMX6_HS,EOCM2B_K1_HS,EOCM2A_K1_HS,CGM_HS
 SG_ RghtLnMrkTyp : 39|3@0+ (1,0) [0|7] ""  EOCM2B_IMX6_HS,EOCM2A_IMX6_HS,EOCM2B_K1_HS,EOCM2A_K1_HS,CGM_HS
 SG_ RghtLnMrkHdng : 36|13@0- (0.000488281,0) [-1.999998976|1.999510695] ""  EOCM2B_IMX6_HS,EOCM2A_IMX6_HS,EOCM2B_K1_HS,EOCM2A_K1_HS,CGM_HS
 SG_ RghtLnMrkClr : 55|3@0+ (1,0) [0|7] ""  EOCM2B_IMX6_HS,EOCM2A_IMX6_HS,EOCM2B_K1_HS,EOCM2A_K1_HS,CGM_HS
 SG_ RghtLnMrkConf : 52|2@0+ (1,0) [0|3] ""  EOCM2B_IMX6_HS,EOCM2A_IMX6_HS,EOCM2B_K1_HS,EOCM2A_K1_HS,CGM_HS
 SG_ RghtLnChksum : 50|11@0+ (1,0) [0|2047] ""  EOCM2B_IMX6_HS,EOCM2A_IMX6_HS,EOCM2B_K1_HS,EOCM2A_K1_HS,CGM_HS

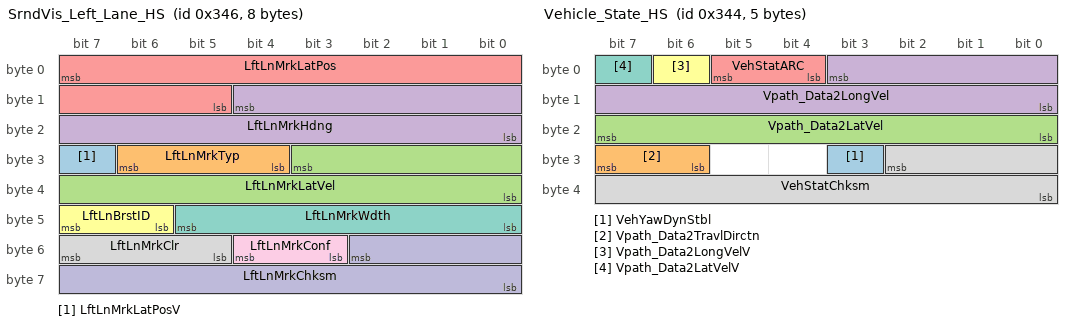
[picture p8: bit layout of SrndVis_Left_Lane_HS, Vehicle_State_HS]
BO_ 838 SrndVis_Left_Lane_HS: 8 VPM_HS
 SG_ LftLnMrkLatPosV : 31|1@0+ (1,0) [0|1] ""  EOCM2B_IMX6_HS,EOCM2A_IMX6_HS,EOCM2B_K1_HS,EOCM2A_K1_HS,CGM_HS
 SG_ LftLnMrkTyp : 30|3@0+ (1,0) [0|7] ""  EOCM2B_IMX6_HS,EOCM2A_IMX6_HS,EOCM2B_K1_HS,EOCM2A_K1_HS,CGM_HS
 SG_ LftLnMrkLatVel : 27|12@0- (0.01,0) [-20.48|20.47] ""  EOCM2B_IMX6_HS,EOCM2A_IMX6_HS,EOCM2B_K1_HS,EOCM2A_K1_HS,CGM_HS
 SG_ LftLnMrkHdng : 12|13@0- (0.000488281,0) [-1.999998976|1.999510695] ""  EOCM2B_IMX6_HS,EOCM2A_IMX6_HS,EOCM2B_K1_HS,EOCM2A_K1_HS,CGM_HS
 SG_ LftLnMrkLatPos : 7|11@0- (0.01,0) [-10.24|10.23] ""  EOCM2B_IMX6_HS,EOCM2A_IMX6_HS,EOCM2B_K1_HS,EOCM2A_K1_HS,CGM_HS
 SG_ LftLnBrstID : 47|2@0+ (1,0) [0|3] ""  EOCM2B_IMX6_HS,EOCM2A_IMX6_HS,EOCM2B_K1_HS,EOCM2A_K1_HS,CGM_HS
 SG_ LftLnMrkWdth : 45|6@0+ (0.01,0) [0|0.63] ""  EOCM2B_IMX6_HS,EOCM2A_IMX6_HS,EOCM2B_K1_HS,EOCM2A_K1_HS,CGM_HS
 SG_ LftLnMrkClr : 55|3@0+ (1,0) [0|7] ""  EOCM2B_IMX6_HS,EOCM2A_IMX6_HS,EOCM2B_K1_HS,EOCM2A_K1_HS,CGM_HS
 SG_ LftLnMrkConf : 52|2@0+ (1,0) [0|3] ""  EOCM2B_IMX6_HS,EOCM2A_IMX6_HS,EOCM2B_K1_HS,EOCM2A_K1_HS,CGM_HS
 SG_ LftLnMrkChksm : 50|11@0+ (1,0) [0|2047] ""  EOCM2B_IMX6_HS,EOCM2A_IMX6_HS,EOCM2B_K1_HS,EOCM2A_K1_HS,CGM_HS

BO_ 837 SrndVis_Lane_Header_HS: 8 VPM_HS
 SG_ SrndVisInitDiagCmplt : 40|1@0+ (1,0) [0|1] ""  EOCM2B_IMX6_HS,EOCM2A_IMX6_HS,CGM_HS,EOCM2B_K1_HS,EOCM2A_K1_HS
 SG_ SrndVisAlgnFltPrsnt : 41|1@0+ (1,0) [0|1] ""  EOCM2B_IMX6_HS,EOCM2A_IMX6_HS,EOCM2B_K1_HS,EOCM2A_K1_HS,CGM_HS
 SG_ SrndVisInSigSuprFaild : 42|1@0+ (1,0) [0|1] ""  EOCM2B_IMX6_HS,EOCM2A_IMX6_HS,EOCM2B_K1_HS,EOCM2A_K1_HS,CGM_HS
 SG_ SrndVisVltgStat : 44|2@0+ (1,0) [0|3] ""  EOCM2B_IMX6_HS,EOCM2A_IMX6_HS,EOCM2B_K1_HS,EOCM2A_K1_HS,CGM_HS
 SG_ SrndVisSvcAlgnInPrcs : 45|1@0+ (1,0) [0|1] ""  EOCM2B_IMX6_HS,EOCM2A_IMX6_HS,EOCM2B_K1_HS,EOCM2A_K1_HS,CGM_HS
 SG_ SrndVisSnsFltPrsnt : 46|1@0+ (1,0) [0|1] ""  EOCM2B_IMX6_HS,EOCM2A_IMX6_HS,EOCM2B_K1_HS,EOCM2A_K1_HS,CGM_HS
 SG_ SrndVisRrSnsrBlckd : 47|1@0+ (1,0) [0|1] ""  EOCM2B_IMX6_HS,EOCM2A_IMX6_HS,EOCM2B_K1_HS,EOCM2A_K1_HS,CGM_HS
 SG_ SrndVisPlntAlgnInProc : 0|1@0+ (1,0) [0|1] ""  EOCM2B_IMX6_HS,EOCM2A_IMX6_HS,EOCM2B_K1_HS,EOCM2A_K1_HS,CGM_HS
 SG_ SrndVisRghtSnsrBlckd : 1|1@0+ (1,0) [0|1] ""  EOCM2B_IMX6_HS,EOCM2A_IMX6_HS,EOCM2B_K1_HS,EOCM2A_K1_HS,CGM_HS
 SG_ SrndVisInChRxErr : 2|1@0+ (1,0) [0|1] ""  EOCM2B_IMX6_HS,EOCM2A_IMX6_HS,EOCM2B_K1_HS,EOCM2A_K1_HS,CGM_HS
 SG_ SrndVisHWFltPrsnt : 3|1@0+ (1,0) [0|1] ""  EOCM2B_IMX6_HS,EOCM2A_IMX6_HS,EOCM2B_K1_HS,EOCM2A_K1_HS,CGM_HS
 SG_ SrndVisFrntSnsrBlckd : 4|1@0+ (1,0) [0|1] ""  EOCM2B_IMX6_HS,EOCM2A_IMX6_HS,EOCM2B_K1_HS,EOCM2A_K1_HS,CGM_HS
 SG_ SrndVisLftSnsrBlckd : 5|1@0+ (1,0) [0|1] ""  EOCM2B_IMX6_HS,EOCM2A_IMX6_HS,EOCM2B_K1_HS,EOCM2A_K1_HS,CGM_HS
 SG_ LnSensMdStat : 6|1@0+ (1,0) [0|1] ""  EOCM2B_IMX6_HS,EOCM2A_IMX6_HS,EOCM2B_K1_HS,EOCM2A_K1_HS,CGM_HS
 SG_ LnSensAcqTmStmpV : 7|1@0+ (1,0) [0|1] ""  EOCM2B_IMX6_HS,EOCM2A_IMX6_HS,EOCM2B_K1_HS,EOCM2A_K1_HS,CGM_HS
 SG_ LnSensAcqTmStmp : 15|32@0+ (1,0) [0|-1] ""  EOCM2B_IMX6_HS,EOCM2A_IMX6_HS,EOCM2B_K1_HS,EOCM2A_K1_HS,CGM_HS
 SG_ SrndVisTempStat : 54|2@0+ (1,0) [0|3] ""  EOCM2B_IMX6_HS,EOCM2A_IMX6_HS,EOCM2B_K1_HS,EOCM2A_K1_HS,CGM_HS
 SG_ SrndVisLnSnsBrstID : 52|2@0+ (1,0) [0|3] ""  EOCM2B_IMX6_HS,EOCM2A_IMX6_HS,EOCM2B_K1_HS,EOCM2A_K1_HS,CGM_HS
 SG_ SrndVisLnSensHdrChksm : 50|11@0+ (1,0) [0|2047] ""  EOCM2B_IMX6_HS,EOCM2A_IMX6_HS,EOCM2B_K1_HS,EOCM2A_K1_HS,CGM_HS

BO_ 836 Vehicle_State_HS: 5 EOCM2A_K1_HS
 SG_ VehYawDynStbl : 27|1@0+ (1,0) [0|1] ""  CGM_HS,VPM_HS,EOCM2B_K1_HS
 SG_ Vpath_Data2TravlDirctn : 31|2@0+ (1,0) [0|3] ""  VPM_HS,EOCM2B_K1_HS,CGM_HS
 SG_ Vpath_Data2LatVel : 23|8@0- (0.05,0) [-6.4|6.35] "m/s"  VPM_HS,EOCM2B_K1_HS,CGM_HS
 SG_ Vpath_Data2LongVel : 3|12@0- (0.0625,0) [-128|127.9375] "m/s"  VPM_HS,EOCM2B_K1_HS,CGM_HS
 SG_ VehStatARC : 5|2@0+ (1,0) [0|3] ""  VPM_HS,EOCM2B_K1_HS,CGM_HS
 SG_ Vpath_Data2LongVelV : 6|1@0+ (1,0) [0|1] ""  VPM_HS,EOCM2B_K1_HS,CGM_HS
 SG_ Vpath_Data2LatVelV : 7|1@0+ (1,0) [0|1] ""  VPM_HS,EOCM2B_K1_HS,CGM_HS
 SG_ VehStatChksm : 26|11@0+ (1,0) [0|2047] ""  VPM_HS,EOCM2B_K1_HS,CGM_HS

BO_ 835 MasterTimeClock_HS: 6 EOCM2A_K1_HS
 SG_ TmSyncMstrTmClkV : 38|1@0+ (1,0) [0|1] ""  VPM_HS,TCP_HS,ONSTAR_HS,EOCM2B_K1_HS,CGM_HS
 SG_ TmSyncMstrTmClk : 7|32@0+ (1,0) [0|-1] "ms"  VPM_HS,TCP_HS,ONSTAR_HS,EOCM2B_K1_HS,CGM_HS
 SG_ RTXCorrctnEnbl : 37|1@0+ (1,0) [0|1] ""  VPM_HS,TCP_HS,ONSTAR_HS,EOCM2B_K1_HS,CGM_HS
 SG_ TmSyncMstrTmClkARC : 36|2@0+ (1,0) [0|3] ""  VPM_HS,TCP_HS,ONSTAR_HS,EOCM2B_K1_HS,CGM_HS
 SG_ TmSyncMstrTmClkChksm : 34|11@0+ (1,0) [0|2047] ""  VPM_HS,TCP_HS,ONSTAR_HS,EOCM2B_K1_HS,CGM_HS

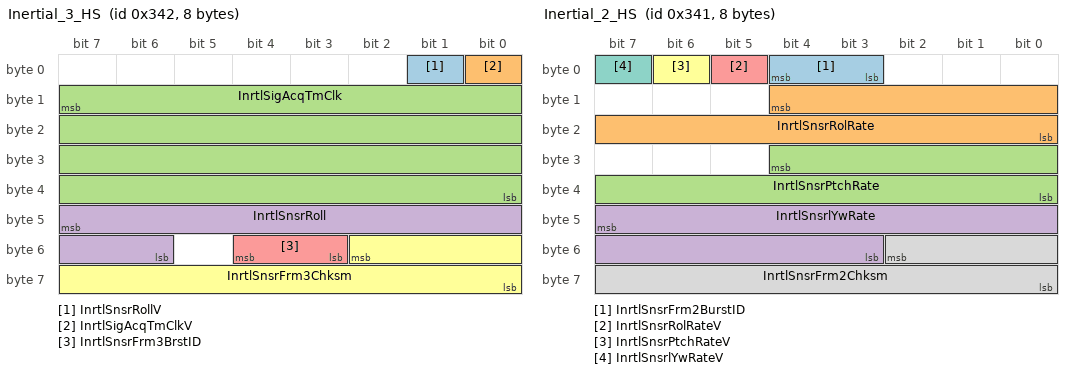
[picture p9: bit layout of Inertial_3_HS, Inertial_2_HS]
BO_ 834 Inertial_3_HS: 8 EOCM2A_K1_HS
 SG_ InrtlSnsrRollV : 1|1@0+ (1,0) [0|1] ""  VPM_HS,TCP_HS,ONSTAR_HS,EOCM2B_K1_HS,CGM_HS
 SG_ InrtlSigAcqTmClkV : 0|1@0+ (1,0) [0|1] ""  VPM_HS,TCP_HS,ONSTAR_HS,EOCM2B_K1_HS,CGM_HS
 SG_ InrtlSigAcqTmClk : 15|32@0+ (1,0) [0|-1] ""  VPM_HS,TCP_HS,ONSTAR_HS,EOCM2B_K1_HS,CGM_HS
 SG_ InrtlSnsrRoll : 47|10@0- (0.1,0) [-51.2|51.1] "deg"  VPM_HS,TCP_HS,ONSTAR_HS,EOCM2B_K1_HS,CGM_HS
 SG_ InrtlSnsrFrm3BrstID : 52|2@0+ (1,0) [0|3] ""  VPM_HS,TCP_HS,ONSTAR_HS,EOCM2B_K1_HS,CGM_HS
 SG_ InrtlSnsrFrm3Chksm : 50|11@0+ (1,0) [0|2047] ""  VPM_HS,TCP_HS,ONSTAR_HS,EOCM2B_K1_HS,CGM_HS

BO_ 833 Inertial_2_HS: 8 EOCM2A_K1_HS
 SG_ InrtlSnsrFrm2BurstID : 4|2@0+ (1,0) [0|3] ""  VPM_HS,TCP_HS,ONSTAR_HS,EOCM2B_K1_HS,CGM_HS
 SG_ InrtlSnsrRolRate : 12|13@0- (0.024,0) [-98.304|98.28] "deg/s"  VPM_HS,TCP_HS,ONSTAR_HS,EOCM2B_K1_HS,CGM_HS
 SG_ InrtlSnsrPtchRate : 28|13@0- (0.024,0) [-98.304|98.28] "deg/s"  VPM_HS,TCP_HS,ONSTAR_HS,EOCM2B_K1_HS,CGM_HS
 SG_ InrtlSnsrlYwRate : 47|13@0- (0.024,0) [-98.304|98.28] "deg/s"  VPM_HS,TCP_HS,ONSTAR_HS,EOCM2B_K1_HS,CGM_HS
 SG_ InrtlSnsrRolRateV : 5|1@0+ (1,0) [0|1] ""  VPM_HS,TCP_HS,ONSTAR_HS,EOCM2B_K1_HS,CGM_HS
 SG_ InrtlSnsrPtchRateV : 6|1@0+ (1,0) [0|1] ""  VPM_HS,TCP_HS,ONSTAR_HS,EOCM2B_K1_HS,CGM_HS
 SG_ InrtlSnsrlYwRateV : 7|1@0+ (1,0) [0|1] ""  VPM_HS,TCP_HS,ONSTAR_HS,EOCM2B_K1_HS,CGM_HS
 SG_ InrtlSnsrFrm2Chksm : 50|11@0+ (1,0) [0|2047] ""  VPM_HS,TCP_HS,ONSTAR_HS,EOCM2B_K1_HS,CGM_HS

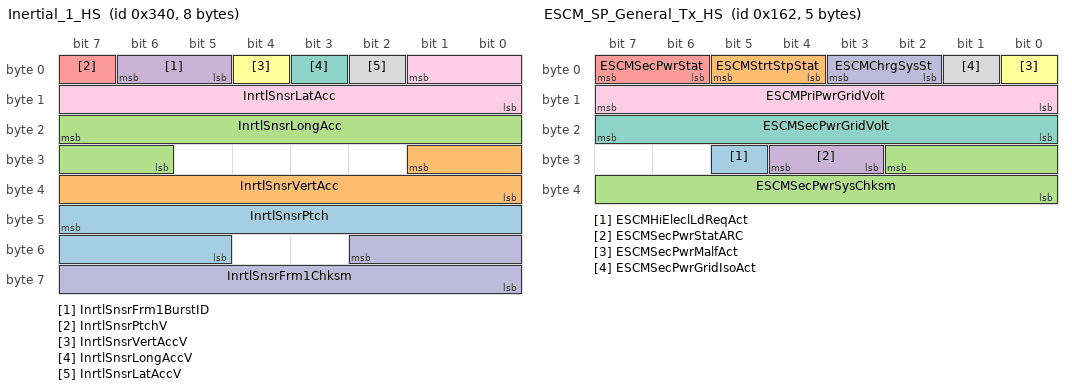
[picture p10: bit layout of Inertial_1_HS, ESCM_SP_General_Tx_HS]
BO_ 832 Inertial_1_HS: 8 EOCM2A_K1_HS
 SG_ InrtlSnsrPtch : 47|11@0- (0.1,0) [-102.4|102.3] "deg"  VPM_HS,TCP_HS,ONSTAR_HS,EOCM2B_K1_HS,CGM_HS
 SG_ InrtlSnsrVertAcc : 25|10@0- (0.0625,0) [-32|31.9375] "m/s^2"  VPM_HS,TCP_HS,ONSTAR_HS,EOCM2B_K1_HS,CGM_HS
 SG_ InrtlSnsrLongAcc : 23|10@0- (0.0625,0) [-32|31.9375] "m/s^2"  VPM_HS,TCP_HS,ONSTAR_HS,EOCM2B_K1_HS,CGM_HS
 SG_ InrtlSnsrFrm1BurstID : 6|2@0+ (1,0) [0|3] ""  VPM_HS,TCP_HS,ONSTAR_HS,EOCM2B_K1_HS,CGM_HS
 SG_ InrtlSnsrPtchV : 7|1@0+ (1,0) [0|1] ""  VPM_HS,TCP_HS,ONSTAR_HS,EOCM2B_K1_HS,CGM_HS
 SG_ InrtlSnsrVertAccV : 4|1@0+ (1,0) [0|1] ""  VPM_HS,TCP_HS,ONSTAR_HS,EOCM2B_K1_HS,CGM_HS
 SG_ InrtlSnsrLongAccV : 3|1@0+ (1,0) [0|1] ""  VPM_HS,TCP_HS,ONSTAR_HS,EOCM2B_K1_HS,CGM_HS
 SG_ InrtlSnsrLatAccV : 2|1@0+ (1,0) [0|1] ""  VPM_HS,TCP_HS,ONSTAR_HS,EOCM2B_K1_HS,CGM_HS
 SG_ InrtlSnsrLatAcc : 1|10@0- (0.0625,0) [-32|31.9375] "m/s^2"  VPM_HS,TCP_HS,ONSTAR_HS,EOCM2B_K1_HS,CGM_HS
 SG_ InrtlSnsrFrm1Chksm : 50|11@0+ (1,0) [0|2047] ""  VPM_HS,TCP_HS,ONSTAR_HS,EOCM2B_K1_HS,CGM_HS

BO_ 336 CSAV2_General_Tx_HS: 1 EOCM2A_K1_HS
 SG_ HzrdLmpActReqd : 6|2@0+ (1,0) [0|3] ""  CGM_HS,BCM_HS
 SG_ FrwayRoadTypInfo : 7|1@0+ (1,0) [0|1] ""  VPM_HS,CGM_HS,ESCM_SP_HS

BO_ 354 ESCM_SP_General_Tx_HS: 5 ESCM_SP_HS
 SG_ ESCMHiEleclLdReqAct : 29|1@0+ (1,0) [0|1] ""  EOCM2B_IMX6_HS,EOCM2A_IMX6_HS,EOCM2A_K1_HS,EOCM2B_K1_HS,BCM_HS
 SG_ ESCMStrtStpStat : 5|2@0+ (1,0) [0|3] ""  EOCM2B_IMX6_HS,EOCM2A_IMX6_HS,EOCM2B_K1_HS,EOCM2A_K1_HS
 SG_ ESCMSecPwrSysChksm : 26|11@0+ (1,0) [0|2047] ""  EOCM2B_IMX6_HS,EOCM2A_IMX6_HS,EOCM2B_K1_HS,EOCM2A_K1_HS
 SG_ ESCMSecPwrStatARC : 28|2@0+ (1,0) [0|3] ""  EOCM2B_IMX6_HS,EOCM2A_IMX6_HS,EOCM2B_K1_HS,EOCM2A_K1_HS
 SG_ ESCMSecPwrStat : 7|2@0+ (1,0) [0|3] ""  EOCM2B_IMX6_HS,EOCM2A_IMX6_HS,EOCM2B_K1_HS,EOCM2A_K1_HS
 SG_ ESCMSecPwrMalfAct : 0|1@0+ (1,0) [0|1] ""  EOCM2B_IMX6_HS,EOCM2A_IMX6_HS,EOCM2B_K1_HS,EOCM2A_K1_HS
 SG_ ESCMSecPwrGridVolt : 23|8@0+ (0.1,0) [0|25.5] "Volts"  EOCM2B_IMX6_HS,EOCM2A_IMX6_HS,EOCM2B_K1_HS,EOCM2A_K1_HS
 SG_ ESCMSecPwrGridIsoAct : 1|1@0+ (1,0) [0|1] ""  EOCM2B_IMX6_HS,EOCM2A_IMX6_HS,EOCM2B_K1_HS,EOCM2A_K1_HS
 SG_ ESCMPriPwrGridVolt : 15|8@0+ (0.1,0) [0|25.5] "Volts"  EOCM2B_IMX6_HS,EOCM2A_IMX6_HS,EOCM2B_K1_HS,EOCM2A_K1_HS
 SG_ ESCMChrgSysSt : 3|2@0+ (1,0) [0|3] ""  EOCM2B_IMX6_HS,EOCM2A_IMX6_HS,EOCM2B_K1_HS,EOCM2A_K1_HS

BO_ 114 Temp_Diag_CAN_Req_HS072: 8 Dummy_HS
 SG_ DgnInf : 7|64@0+ (1,0) [0|1.8446744074e+19] ""  CGM_HS

BO_ 93 Temp_Diag_CAN_Req_HS05D: 8 Dummy_HS
 SG_ DgnInf : 7|64@0+ (1,0) [0|1.8446744074e+19] ""  CGM_HS

BO_ 861 Temp_Diag_CAN_Resp_HS35D: 8 CGM_HS
 SG_ DgnInf : 7|64@0+ (1,0) [0|1.8446744074e+19] ""  CGM_HS,Dummy_HS

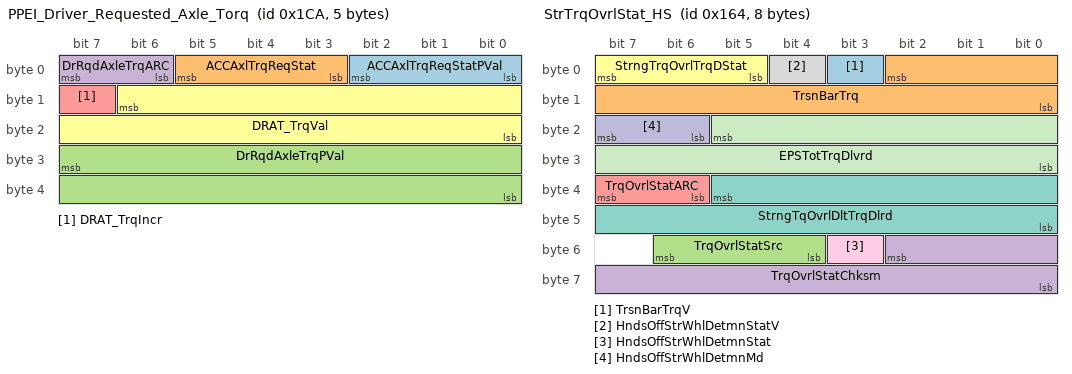
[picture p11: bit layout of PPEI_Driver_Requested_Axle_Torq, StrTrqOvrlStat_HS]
BO_ 458 PPEI_Driver_Requested_Axle_Torq: 5 ECM_HS
 SG_ ACCAxlTrqReqStatPVal : 2|3@0+ (1,0) [0|7] ""  EOCM2B_K2_HS,EOCM2A_K2_HS,EOCM2B_K1_HS,EOCM2A_K1_HS,CGM_HS
 SG_ ACCAxlTrqReqStat : 5|3@0+ (1,0) [0|7] ""  EOCM2B_K2_HS,EOCM2A_K2_HS,EOCM2B_K1_HS,EOCM2A_K1_HS,CGM_HS
 SG_ DrRqdAxleTrqPVal : 31|16@0+ (1,0) [0|65535] ""  EOCM2B_K2_HS,EOCM2A_K2_HS,CGM_HS,EOCM2B_K1_HS,EOCM2A_K1_HS
 SG_ DrRqdAxleTrqARC : 7|2@0+ (1,0) [0|3] ""  EOCM2B_K2_HS,EOCM2A_K2_HS,CGM_HS,EOCM2B_K1_HS,EOCM2A_K1_HS
 SG_ DRAT_TrqIncr : 15|1@0+ (1,0) [0|1] ""  EOCM2B_K2_HS,EOCM2A_K2_HS,CGM_HS,EOCM2B_K1_HS,EOCM2A_K1_HS
 SG_ DRAT_TrqVal : 14|15@0+ (2,-22534) [-22534|43000] ""  EOCM2B_K2_HS,EOCM2A_K2_HS,CGM_HS,EOCM2B_K1_HS,EOCM2A_K1_HS

BO_ 1191 PTEI_Hybrid_General_Status_5_HS: 3 HCP_HS
 SG_ HybColdSoakTempM : 7|1@0+ (1,0) [0|1] ""  CGM_HS,TCM_HS
 SG_ HybColdSoakTemp : 15|8@0+ (0.5,-40) [-40|87.5] "deg C"  CGM_HS,TCM_HS
 SG_ HybEstTransOilTmpM : 6|1@0+ (1,0) [0|1] ""  CGM_HS,TCM_HS
 SG_ HybEstTransOilTmp : 23|8@0+ (1,-40) [-40|215] "deg C"  CGM_HS,TCM_HS

BO_ 356 StrTrqOvrlStat_HS: 8 EPS_HS
 SG_ TrsnBarTrqV : 3|1@0+ (1,0) [0|1] ""  EOCM2B_K2_HS,EOCM2A_K2_HS,EOCM2B_K1_HS,EOCM2A_K1_HS,CGM_HS
 SG_ TrsnBarTrq : 2|11@0- (0.02,0) [-20.48|20.46] "Nm"  EOCM2B_K2_HS,EOCM2A_K2_HS,EOCM2B_K1_HS,EOCM2A_K1_HS,CGM_HS
 SG_ TrqOvrlStatSrc : 54|3@0+ (1,0) [0|7] ""  EOCM2B_K2_HS,EOCM2A_K2_HS,EOCM2B_K1_HS,EOCM2A_K1_HS,CGM_HS
 SG_ TrqOvrlStatChksm : 50|11@0+ (1,0) [0|2047] ""  EOCM2B_K2_HS,EOCM2A_K2_HS,EOCM2B_K1_HS,EOCM2A_K1_HS,CGM_HS
 SG_ TrqOvrlStatARC : 39|2@0+ (1,0) [0|3] ""  EOCM2B_K2_HS,EOCM2A_K2_HS,EOCM2B_K1_HS,EOCM2A_K1_HS,CGM_HS
 SG_ StrngTrqOvrlTrqDStat : 7|3@0+ (1,0) [0|7] ""  EOCM2B_K2_HS,EOCM2A_K2_HS,EOCM2B_K1_HS,EOCM2A_K1_HS,CGM_HS
 SG_ StrngTqOvrlDltTrqDlrd : 37|14@0- (0.02,0) [-163.84|163.82] "Nm"  EOCM2B_K2_HS,EOCM2A_K2_HS,EOCM2B_K1_HS,EOCM2A_K1_HS,CGM_HS
 SG_ HndsOffStrWhlDetmnStatV : 4|1@0+ (1,0) [0|1] ""  EOCM2B_K2_HS,EOCM2A_K2_HS,EOCM2B_K1_HS,EOCM2A_K1_HS,CGM_HS
 SG_ HndsOffStrWhlDetmnStat : 51|1@0+ (1,0) [0|1] ""  EOCM2B_K2_HS,EOCM2A_K2_HS,EOCM2B_K1_HS,EOCM2A_K1_HS,CGM_HS
 SG_ HndsOffStrWhlDetmnMd : 23|2@0+ (1,0) [0|3] "0"  EOCM2B_K2_HS,EOCM2A_K2_HS,EOCM2B_K1_HS,EOCM2A_K1_HS,CGM_HS
 SG_ EPSTotTrqDlvrd : 21|14@0- (0.02,0) [-163.84|163.82] "Nm"  EOCM2B_K2_HS,EOCM2A_K2_HS,EOCM2B_K1_HS,CGM_HS,EOCM2A_K1_HS

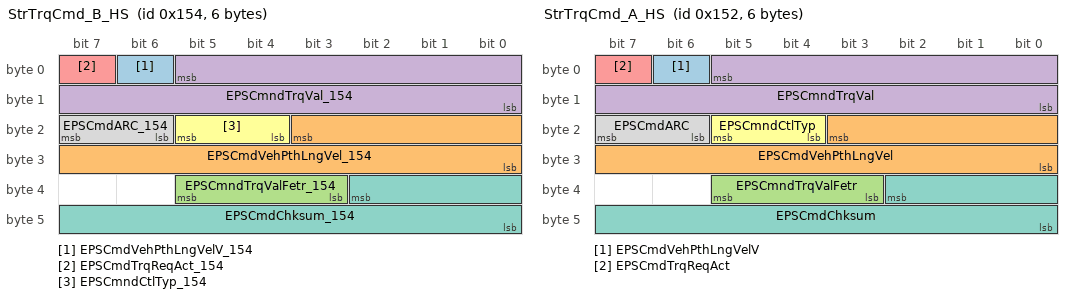
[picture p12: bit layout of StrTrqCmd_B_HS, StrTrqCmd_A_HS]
BO_ 340 StrTrqCmd_B_HS: 6 EOCM2B_K1_HS
 SG_ EPSCmdVehPthLngVelV_154 : 6|1@0+ (1,0) [0|1] ""  EOCM2A_K1_HS,EPS_HS
 SG_ EPSCmdVehPthLngVel_154 : 19|12@0- (0.0625,0) [-128|127.9375] "m/s"  EOCM2A_K1_HS,EPS_HS
 SG_ EPSCmndTrqValFetr_154 : 37|3@0+ (1,0) [0|7] ""  EOCM2A_K1_HS,EPS_HS
 SG_ EPSCmndTrqVal_154 : 5|14@0- (0.02,0) [-163.84|163.82] "Nm"  EOCM2A_K1_HS,EPS_HS
 SG_ EPSCmdTrqReqAct_154 : 7|1@0+ (1,0) [0|1] ""  EOCM2A_K1_HS,EPS_HS
 SG_ EPSCmndCtlTyp_154 : 21|2@0+ (1,0) [0|3] ""  EOCM2A_K1_HS,EPS_HS
 SG_ EPSCmdChksum_154 : 34|11@0+ (1,0) [0|2047] ""  EOCM2A_K1_HS,EPS_HS
 SG_ EPSCmdARC_154 : 23|2@0+ (1,0) [0|3] ""  EOCM2A_K1_HS,EPS_HS

BO_ 338 StrTrqCmd_A_HS: 6 EOCM2A_K1_HS
 SG_ EPSCmdVehPthLngVelV : 6|1@0+ (1,0) [0|1] ""  EOCM2B_K1_HS,EPS_HS
 SG_ EPSCmdVehPthLngVel : 19|12@0- (0.0625,0) [-128|127.9375] "m/s"  EOCM2B_K1_HS,EPS_HS
 SG_ EPSCmndTrqValFetr : 37|3@0+ (1,0) [0|7] ""  EOCM2B_K1_HS,EPS_HS
 SG_ EPSCmndTrqVal : 5|14@0- (0.02,0) [-163.84|163.82] "Nm"  EOCM2B_K1_HS,EPS_HS
 SG_ EPSCmdTrqReqAct : 7|1@0+ (1,0) [0|1] ""  EOCM2B_K1_HS,EPS_HS
 SG_ EPSCmndCtlTyp : 21|2@0+ (1,0) [0|3] ""  EOCM2B_K1_HS,EPS_HS
 SG_ EPSCmdChksum : 34|11@0+ (1,0) [0|2047] ""  EOCM2B_K1_HS,EPS_HS
 SG_ EPSCmdARC : 23|2@0+ (1,0) [0|3] ""  EOCM2B_K1_HS,EPS_HS

BO_ 503 ETRS_General_Request_1_HS: 2 ICCM_HS
 SG_ MonProcSecPtrnPrmry : 11|4@0+ (1,0) [0|15] ""  CGM_HS,TRCM_HS,HCP_HS,TCM_HS
 SG_ ElcTransRngRqPVal : 2|3@0+ (1,0) [0|7] ""  HCP_HS,HCP_B_HS,CGM_HS,RDCM_HS,TRCM_HS,TCM_HS
 SG_ ElcTransRngRqARC : 4|2@0+ (1,0) [0|3] ""  HCP_HS,HCP_B_HS,CGM_HS,RDCM_HS,TRCM_HS,TCM_HS
 SG_ ElcTransRngRq : 7|3@0+ (1,0) [0|7] ""  BCM_HS,HCP_HS,HCP_B_HS,CGM_HS,RDCM_HS,TRCM_HS,TCM_HS

BO_ 872 ETRS_General_Request_2_HS: 1 ECM_HS
 SG_ ESBR_AutoBrkgRqTyp : 1|2@0+ (1,0) [0|3] ""  CGM_HS,EBCM_OBD_HS,EBCM_HS,EPB_HS
 SG_ ESBR_AutoBrkgRqd : 2|1@0+ (1,0) [0|1] ""  CGM_HS,EBCM_OBD_HS,EBCM_HS,EPB_HS
 SG_ ElcShftBrkgRqPVal : 7|3@0+ (1,0) [0|7] ""  CGM_HS,EBCM_OBD_HS,EBCM_HS,EPB_HS
 SG_ ElcShftBrkgRqARC : 4|2@0+ (1,0) [0|3] ""  CGM_HS,EBCM_OBD_HS,EBCM_HS,EPB_HS

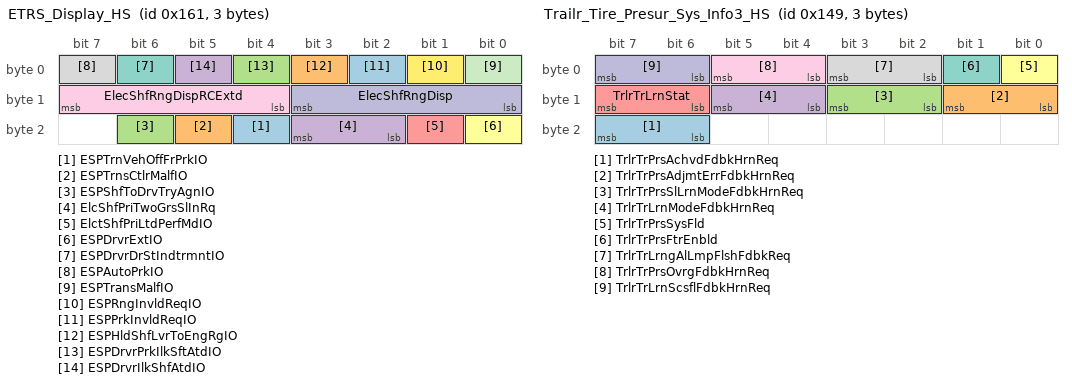
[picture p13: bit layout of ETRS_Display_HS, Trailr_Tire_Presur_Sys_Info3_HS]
BO_ 353 ETRS_Display_HS: 3 ICCM_HS
 SG_ ESPTrnVehOffFrPrkIO : 20|1@0+ (1,0) [0|1] ""  CGM_HS,BCM_HS
 SG_ ESPTrnsCtlrMalfIO : 21|1@0+ (1,0) [0|1] ""  CGM_HS,BCM_HS
 SG_ ESPShfToDrvTryAgnIO : 22|1@0+ (1,0) [0|1] ""  CGM_HS,BCM_HS
 SG_ ElcShfPriTwoGrsSlInRq : 19|2@0+ (1,0) [0|3] ""  CGM_HS,BCM_HS
 SG_ ElctShfPriLtdPerfMdIO : 17|1@0+ (1,0) [0|1] ""  CGM_HS,BCM_HS
 SG_ ESPDrvrExtIO : 16|1@0+ (1,0) [0|1] ""  CGM_HS,BCM_HS
 SG_ ESPDrvrDrStIndtrmntIO : 6|1@0+ (1,0) [0|1] ""  CGM_HS,BCM_HS
 SG_ ESPAutoPrkIO : 7|1@0+ (1,0) [0|1] ""  CGM_HS,BCM_HS
 SG_ ElecShfRngDispRCExtd : 15|4@0+ (1,0) [0|15] ""  CGM_HS,BCM_HS
 SG_ ElecShfRngDisp : 11|4@0+ (1,0) [0|15] ""  CGM_HS,BCM_HS
 SG_ ESPTransMalfIO : 0|1@0+ (1,0) [0|1] ""  CGM_HS,BCM_HS
 SG_ ESPRngInvldReqIO : 1|1@0+ (1,0) [0|1] ""  CGM_HS,BCM_HS
 SG_ ESPPrkInvldReqIO : 2|1@0+ (1,0) [0|1] ""  CGM_HS,BCM_HS
 SG_ ESPHldShfLvrToEngRgIO : 3|1@0+ (1,0) [0|1] ""  CGM_HS,BCM_HS
 SG_ ESPDrvrPrkIlkSftAtdIO : 4|1@0+ (1,0) [0|1] ""  CGM_HS,BCM_HS
 SG_ ESPDrvrIlkShfAtdIO : 5|1@0+ (1,0) [0|1] ""  CGM_HS,BCM_HS

BO_ 329 Trailr_Tire_Presur_Sys_Info3_HS: 3 TTPM_HS
 SG_ TrlrTrPrsAchvdFdbkHrnReq : 23|2@0+ (1,0) [0|3] ""  BCM_HS
 SG_ TrlrTrPrsAdjmtErrFdbkHrnReq : 9|2@0+ (1,0) [0|3] ""  BCM_HS
 SG_ TrlrTrPrsSlLrnModeFdbkHrnReq : 11|2@0+ (1,0) [0|3] ""  BCM_HS
 SG_ TrlrTrLrnModeFdbkHrnReq : 13|2@0+ (1,0) [0|3] ""  BCM_HS
 SG_ TrlrTrLrnStat : 15|2@0+ (1,0) [0|3] ""  CSM_HS
 SG_ TrlrTrPrsSysFld : 0|1@0+ (1,0) [0|1] ""  CSM_HS
 SG_ TrlrTrPrsFtrEnbld : 1|1@0+ (1,0) [0|1] ""  CSM_HS
 SG_ TrlrTrLrngAlLmpFlshFdbkReq : 3|2@0+ (1,0) [0|3] ""  BCM_HS
 SG_ TrlrTrPrsOvrgFdbkHrnReq : 5|2@0+ (1,0) [0|3] ""  BCM_HS
 SG_ TrlrTrLrnScsflFdbkHrnReq : 7|2@0+ (1,0) [0|3] ""  BCM_HS

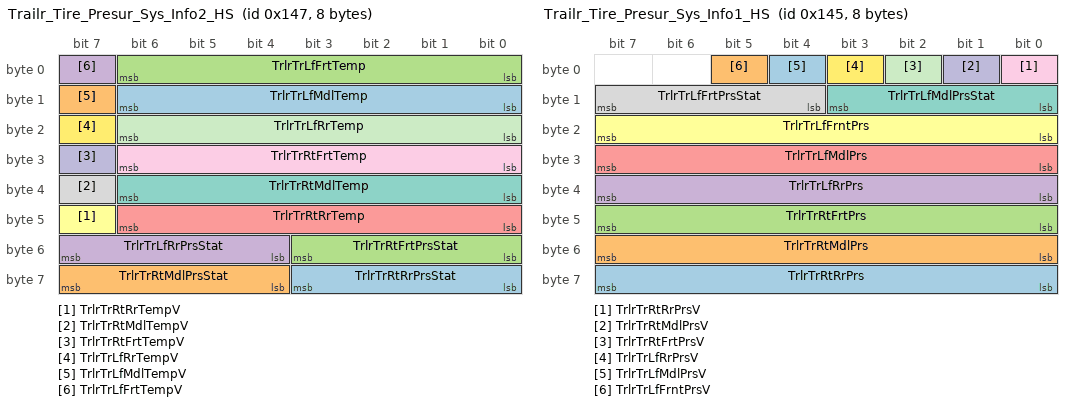
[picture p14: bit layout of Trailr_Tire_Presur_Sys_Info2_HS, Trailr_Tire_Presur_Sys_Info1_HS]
BO_ 327 Trailr_Tire_Presur_Sys_Info2_HS: 8 TTPM_HS
 SG_ TrlrTrRtRrPrsStat : 59|4@0+ (1,0) [0|15] ""  CGM_HS,CSM_HS
 SG_ TrlrTrRtMdlPrsStat : 63|4@0+ (1,0) [0|15] ""  CGM_HS,CSM_HS
 SG_ TrlrTrRtFrtPrsStat : 51|4@0+ (1,0) [0|15] ""  CGM_HS,CSM_HS
 SG_ TrlrTrLfRrPrsStat : 55|4@0+ (1,0) [0|15] ""  CGM_HS,CSM_HS
 SG_ TrlrTrRtRrTemp : 46|7@0+ (1,-20) [-20|107] "degC"  CGM_HS,CSM_HS
 SG_ TrlrTrRtRrTempV : 47|1@0+ (1,0) [0|1] ""  CGM_HS,CSM_HS
 SG_ TrlrTrRtMdlTemp : 38|7@0+ (1,-20) [-20|107] "degC"  CGM_HS,CSM_HS
 SG_ TrlrTrRtMdlTempV : 39|1@0+ (1,0) [0|1] ""  CGM_HS,CSM_HS
 SG_ TrlrTrRtFrtTemp : 30|7@0+ (1,-20) [-20|107] "degC"  CGM_HS,CSM_HS
 SG_ TrlrTrRtFrtTempV : 31|1@0+ (1,0) [0|1] ""  CGM_HS,CSM_HS
 SG_ TrlrTrLfRrTemp : 22|7@0+ (1,-20) [-20|107] "degC"  CGM_HS,CSM_HS
 SG_ TrlrTrLfRrTempV : 23|1@0+ (1,0) [0|1] ""  CGM_HS,CSM_HS
 SG_ TrlrTrLfMdlTemp : 14|7@0+ (1,-20) [-20|107] "degC"  CGM_HS,CSM_HS
 SG_ TrlrTrLfMdlTempV : 15|1@0+ (1,0) [0|1] ""  CGM_HS,CSM_HS
 SG_ TrlrTrLfFrtTemp : 6|7@0+ (1,-20) [-20|107] "degC"  CGM_HS,CSM_HS
 SG_ TrlrTrLfFrtTempV : 7|1@0+ (1,0) [0|1] ""  CGM_HS,CSM_HS

BO_ 325 Trailr_Tire_Presur_Sys_Info1_HS: 8 TTPM_HS
 SG_ TrlrTrRtRrPrs : 63|8@0+ (4,0) [0|1020] "kPaG"  CGM_HS,CSM_HS
 SG_ TrlrTrRtMdlPrs : 55|8@0+ (4,0) [0|1020] "kPaG"  CGM_HS,CSM_HS
 SG_ TrlrTrRtFrtPrs : 47|8@0+ (4,0) [0|1020] "kPaG"  CGM_HS,CSM_HS
 SG_ TrlrTrLfRrPrs : 39|8@0+ (4,0) [0|1020] "kPaG"  CGM_HS,CSM_HS
 SG_ TrlrTrLfMdlPrs : 31|8@0+ (4,0) [0|1020] "kPaG"  CGM_HS,CSM_HS
 SG_ TrlrTrLfFrntPrs : 23|8@0+ (4,0) [0|1020] "kPaG"  CGM_HS,CSM_HS
 SG_ TrlrTrLfMdlPrsStat : 11|4@0+ (1,0) [0|15] ""  CGM_HS,CSM_HS
 SG_ TrlrTrLfFrtPrsStat : 15|4@0+ (1,0) [0|15] ""  CGM_HS,CSM_HS
 SG_ TrlrTrRtRrPrsV : 0|1@0+ (1,0) [0|1] ""  CGM_HS,CSM_HS
 SG_ TrlrTrRtMdlPrsV : 1|1@0+ (1,0) [0|1] ""  CGM_HS,CSM_HS
 SG_ TrlrTrRtFrtPrsV : 2|1@0+ (1,0) [0|1] ""  CGM_HS,CSM_HS
 SG_ TrlrTrLfRrPrsV : 3|1@0+ (1,0) [0|1] ""  CGM_HS,CSM_HS
 SG_ TrlrTrLfMdlPrsV : 4|1@0+ (1,0) [0|1] ""  CGM_HS,CSM_HS
 SG_ TrlrTrLfFrntPrsV : 5|1@0+ (1,0) [0|1] ""  CGM_HS,CSM_HS

BO_ 331 Trailr_Tire_Presur_Sys_Info4_HS: 3 CSM_HS
 SG_ TrlrPrfDltn : 23|3@0+ (1,0) [0|7] ""  TTPM_HS
 SG_ TrlrPlcrdPrs : 15|8@0+ (4,0) [0|1020] "kPaG"  TTPM_HS
 SG_ TrlrTrCnt : 6|3@0+ (1,0) [0|7] "count"  TTPM_HS
 SG_ TrlrTrPrsSenrIDLrnReqd : 7|1@0+ (1,0) [0|1] ""  TTPM_HS
 SG_ TrlrProfSelV : 3|1@0+ (1,0) [0|1] ""  TTPM_HS,EBCM_OBD_HS,EBCM_HS
 SG_ TrlrProfSel : 2|3@0+ (1,0) [0|7] ""  TTPM_HS,EBCM_OBD_HS,EBCM_HS

BO_ 1275 Brake_Sys_Control_2_General_Info: 3 EBOOST_OBD_HS
 SG_ BrkSyCtl2EmsRldMlfAct : 23|1@0+ (1,0) [0|1] ""  CGM_HS,ECM_HS
 SG_ BSC2ERDTC_CdNum : 3|12@0+ (1,0) [0|4095] ""  CGM_HS,ECM_HS
 SG_ BSC2ERDTC_SysDes : 7|4@0+ (1,0) [0|15] ""  CGM_HS,ECM_HS
 SG_ EBrkAstStat : 22|3@0+ (1,0) [0|7] ""  CGM_HS,EBCM_OBD_HS,EBCM_HS

BO_ 1273 Brake_Sys_Control_1_General_Info: 3 EBCM_HS
 SG_ BrkSyCtl1EmsRldMlfAct : 23|1@0+ (1,0) [0|1] ""  CGM_HS,ECM_HS
 SG_ BSC1ERDTC_CdNum : 3|12@0+ (1,0) [0|4095] ""  CGM_HS,ECM_HS
 SG_ BSC1ERDTC_SysDes : 7|4@0+ (1,0) [0|15] ""  CGM_HS,ECM_HS

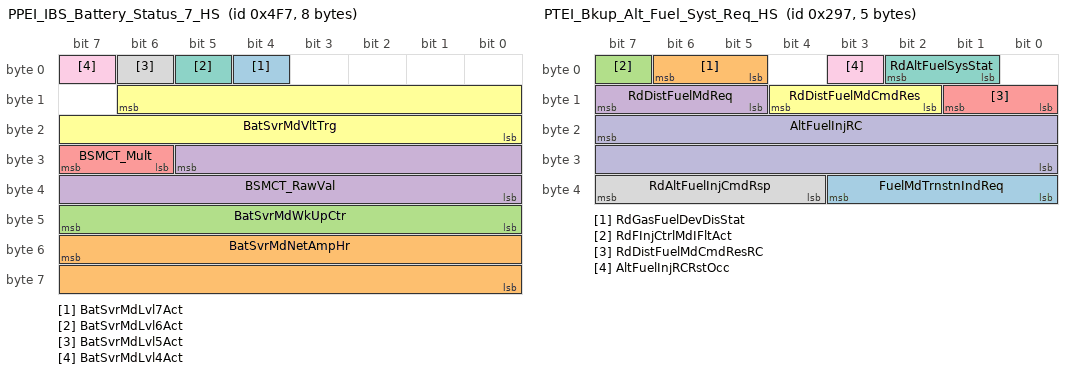
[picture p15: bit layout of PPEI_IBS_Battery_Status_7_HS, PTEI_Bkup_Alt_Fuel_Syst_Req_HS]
BO_ 1271 PPEI_IBS_Battery_Status_7_HS: 8 ECM_HS
 SG_ BatSvrMdLvl7Act : 4|1@0+ (1,0) [0|1] ""  CGM_HS,EOCM2B_K1_HS,BCM_HS,EOCM2A_K1_HS
 SG_ BatSvrMdNetAmpHr : 55|16@0+ (0.01,-327.67) [-327.67|327.68] "AmpHours"  CGM_HS,EOCM2B_K1_HS,BCM_HS,EOCM2A_K1_HS
 SG_ BatSvrMdWkUpCtr : 47|8@0+ (1,0) [0|255] ""  CGM_HS,EOCM2B_K1_HS,BCM_HS,EOCM2A_K1_HS
 SG_ BSMCT_RawVal : 29|14@0+ (0.001,-8.192) [-8.192|8.191] "A"  CGM_HS,EOCM2B_K1_HS,BCM_HS,EOCM2A_K1_HS
 SG_ BSMCT_Mult : 31|2@0+ (1,0) [0|3] ""  CGM_HS,EOCM2B_K1_HS,BCM_HS,EOCM2A_K1_HS
 SG_ BatSvrMdVltTrg : 14|15@0+ (0.001,0) [0|32.767] "V"  CGM_HS,EOCM2B_K1_HS,BCM_HS,EOCM2A_K1_HS
 SG_ BatSvrMdLvl6Act : 5|1@0+ (1,0) [0|1] ""  CGM_HS,EOCM2B_K1_HS,BCM_HS,EOCM2A_K1_HS
 SG_ BatSvrMdLvl5Act : 6|1@0+ (1,0) [0|1] ""  CGM_HS,EOCM2B_K1_HS,BCM_HS,EOCM2A_K1_HS
 SG_ BatSvrMdLvl4Act : 7|1@0+ (1,0) [0|1] ""  CGM_HS,EOCM2B_K1_HS,BCM_HS,EOCM2A_K1_HS

BO_ 558 Air_Cmpresor_Ctrl_Data2_HS: 8 ACCM_HS
 SG_ CmpDataPktARC : 57|2@0+ (1,0) [0|3] "N/A"  CGM_HS,BSM_HS,VICM_HS
 SG_ CDP_HVDevShtdnCdARCSt : 49|2@0+ (1,0) [0|3] ""  CGM_HS,BSM_HS,VICM_HS
 SG_ CDP_CmpSpdReqARCSt : 51|2@0+ (1,0) [0|3] ""  CGM_HS,BSM_HS,VICM_HS
 SG_ CDP_CmpLossCommOcc : 52|1@0+ (1,0) [0|1] ""  CGM_HS,BSM_HS,VICM_HS
 SG_ CDP_CmpWkUp : 53|1@0+ (1,0) [0|1] ""  CGM_HS,BSM_HS,VICM_HS
 SG_ CDP_CmpRunCrnk : 54|1@0+ (1,0) [0|1] ""  CGM_HS,BSM_HS,VICM_HS
 SG_ CmpSnsrDevStPktARC : 5|2@0+ (1,0) [0|3] "N/A"  CGM_HS,BSM_HS,VICM_HS
 SG_ CDSP_CmpOvrTmpSt : 11|2@0+ (1,0) [0|3] ""  CGM_HS,BSM_HS,VICM_HS
 SG_ CDSP_CmpHVAbnrlOrVltSt : 13|2@0+ (1,0) [0|3] ""  CGM_HS,BSM_HS,VICM_HS
 SG_ CDSP_CmpHVUndrVltgSt : 15|2@0+ (1,0) [0|3] ""  CGM_HS,BSM_HS,VICM_HS
 SG_ CDSP_CmpHVOvrVltgSt : 1|2@0+ (1,0) [0|3] ""  CGM_HS,BSM_HS,VICM_HS
 SG_ CDSP_CmpHVOvrCrntSt : 3|2@0+ (1,0) [0|3] ""  CGM_HS,BSM_HS,VICM_HS
 SG_ CDSP_OvrTempWrnInd : 24|1@0+ (1,0) [0|1] ""  CGM_HS,BSM_HS,VICM_HS
 SG_ CDSP_CmpDgrdOp : 25|1@0+ (1,0) [0|1] ""  CGM_HS,BSM_HS,VICM_HS
 SG_ CDSP_CmpIntShdwnFltSt : 27|2@0+ (1,0) [0|3] ""  CGM_HS,BSM_HS,VICM_HS
 SG_ CDSP_CmpIntRecblFltSt : 29|2@0+ (1,0) [0|3] ""  CGM_HS,BSM_HS,VICM_HS
 SG_ CDSP_CmpOpOvrldSt : 31|2@0+ (1,0) [0|3] ""  CGM_HS,BSM_HS,VICM_HS
 SG_ CDSP_CmpDrCrctFltSt : 17|2@0+ (1,0) [0|3] ""  CGM_HS,BSM_HS,VICM_HS
 SG_ CDSP_CmpMtrPerfFltSt : 19|2@0+ (1,0) [0|3] ""  CGM_HS,BSM_HS,VICM_HS
 SG_ CDSP_CmpEEPROMFltSt : 21|2@0+ (1,0) [0|3] ""  CGM_HS,BSM_HS,VICM_HS
 SG_ CDSP_CmpROMFltSt : 23|2@0+ (1,0) [0|3] ""  CGM_HS,BSM_HS,VICM_HS
 SG_ CDSP_CmpRAMFltSt : 9|2@0+ (1,0) [0|3] ""  CGM_HS,BSM_HS,VICM_HS
 SG_ CmpSnsrStPktARC : 7|2@0+ (1,0) [0|3] "N/A"  CGM_HS,BSM_HS,VICM_HS
 SG_ CSSP_CmpIGBTTpOtRgLSt : 41|2@0+ (1,0) [0|3] ""  CGM_HS,BSM_HS,VICM_HS
 SG_ CSSP_CmpIGBTTpOtRgHSt : 43|2@0+ (1,0) [0|3] ""  CGM_HS,BSM_HS,VICM_HS
 SG_ CSSP_CmpCPUTmpOtRgLSt : 45|2@0+ (1,0) [0|3] ""  CGM_HS,BSM_HS,VICM_HS
 SG_ CSSP_CmpCPUTmpOtRgHSt : 47|2@0+ (1,0) [0|3] ""  CGM_HS,BSM_HS,VICM_HS
 SG_ CSSP_CmpHVSnsOtRgLSt : 33|2@0+ (1,0) [0|3] ""  CGM_HS,BSM_HS,VICM_HS
 SG_ CSSP_CmpHVSnsOtRgHSt : 35|2@0+ (1,0) [0|3] ""  CGM_HS,BSM_HS,VICM_HS
 SG_ CSSP_CmpPhCrntOtRgLSt : 37|2@0+ (1,0) [0|3] ""  CGM_HS,BSM_HS,VICM_HS
 SG_ CSSP_CmpPhCrntOtRgHSt : 39|2@0+ (1,0) [0|3] ""  CGM_HS,BSM_HS,VICM_HS

BO_ 208 PPEI_Wheel_Slip_Data_HS: 8 EBCM_HS
 SG_ WhlSlipRRWhl : 55|16@0+ (0.390625,-12800) [-12800|12799.609375] "%"  CGM_HS,EOCM2B_K1_HS,EOCM2A_K1_HS,TCM_HS
 SG_ WhlSlipRFWhl : 23|16@0+ (0.390625,-12800) [-12800|12799.609375] "%"  CGM_HS,EOCM2B_K1_HS,EOCM2A_K1_HS,TCM_HS
 SG_ WhlSlipLRWhl : 39|16@0+ (0.390625,-12800) [-12800|12799.609375] "%"  CGM_HS,EOCM2B_K1_HS,EOCM2A_K1_HS,TCM_HS
 SG_ WhlSlipLFWhl : 7|16@0+ (0.390625,-12800) [-12800|12799.609375] "%"  CGM_HS,EOCM2B_K1_HS,EOCM2A_K1_HS,TCM_HS

BO_ 663 PTEI_Bkup_Alt_Fuel_Syst_Req_HS: 5 FICM_HS
 SG_ FuelMdTrnstnIndReq : 35|4@0+ (1,0) [0|15] ""  CGM_HS,BCM_HS
 SG_ RdGasFuelDevDisStat : 6|2@0+ (1,0) [0|3] ""  CGM_HS,ECM_HS
 SG_ RdFInjCtrlMdIFltAct : 7|1@0+ (1,0) [0|1] ""  CGM_HS,ECM_HS
 SG_ RdDistFuelMdReq : 15|3@0+ (1,0) [0|7] ""  CGM_HS,ECM_HS
 SG_ RdDistFuelMdCmdResRC : 9|2@0+ (1,0) [0|3] ""  CGM_HS,ECM_HS
 SG_ RdDistFuelMdCmdRes : 12|3@0+ (1,0) [0|7] ""  CGM_HS,ECM_HS
 SG_ RdAltFuelSysStat : 2|2@0+ (1,0) [0|3] ""  CGM_HS,ECM_HS
 SG_ RdAltFuelInjCmdRsp : 39|4@0+ (1,0) [0|15] ""  CGM_HS,ECM_HS
 SG_ AltFuelInjRCRstOcc : 3|1@0+ (1,0) [0|1] ""  CGM_HS,ECM_HS
 SG_ AltFuelInjRC : 23|16@0+ (3.0517578125e-05,0) [0|1.9999694824] "liters"  CGM_HS,ECM_HS

BO_ 1263 PPEI_IBS_Battery_Status_6: 4 ECM_HS
 SG_ BatSOFVolt : 31|8@0+ (0.05,0) [0|12.75] "volts"  CGM_HS,EOCM2B_K1_HS,BCM_HS,EOCM2A_K1_HS
 SG_ BatSOH : 23|8@0+ (0.392157,0) [0|100.000035] "%"  CGM_HS,EOCM2B_K1_HS,BCM_HS,EOCM2A_K1_HS
 SG_ IBSBatSOC : 15|8@0+ (0.392157,0) [0|100.000035] "%"  CGM_HS,EOCM2B_K1_HS,BCM_HS,EOCM2A_K1_HS
 SG_ BattSOXStat : 7|1@0+ (1,0) [0|1] ""  CGM_HS,EOCM2B_K1_HS,BCM_HS,EOCM2A_K1_HS

BO_ 1261 PPEI_IBS_Battery_Status_5: 7 ECM_HS
 SG_ MinCrnkCrnt : 29|22@0+ (0.001,-2097.152) [-2097.152|2097.151] "amps"  CGM_HS,EOCM2B_K1_HS,BCM_HS,EOCM2A_K1_HS
 SG_ MinCrnkVlt : 14|15@0+ (0.001,0) [0|32.767] "volts"  CGM_HS,EOCM2B_K1_HS,BCM_HS,EOCM2A_K1_HS
 SG_ MinCrnkCrntVltStat : 5|1@0+ (1,0) [0|1] ""  CGM_HS,EOCM2B_K1_HS,BCM_HS,EOCM2A_K1_HS
 SG_ BattTempV : 6|1@0+ (1,0) [0|1] ""  CGM_HS,EOCM2B_K1_HS,BCM_HS,EOCM2A_K1_HS
 SG_ BattTempM : 7|1@0+ (1,0) [0|1] ""  CGM_HS,EOCM2B_K1_HS,BCM_HS,EOCM2A_K1_HS
 SG_ BattTemp : 55|8@0+ (1,-40) [-40|215] "deg C"  CGM_HS,EOCM2B_K1_HS,BCM_HS,EOCM2A_K1_HS

BO_ 1259 PPEI_IBS_Battery_Status_4: 8 ECM_HS
 SG_ AllNodesVNA : 5|1@0+ (1,0) [0|1] ""  CGM_HS,EOCM2B_K1_HS,BCM_HS,EOCM2A_K1_HS
 SG_ NAHrDisChrgM : 6|1@0+ (1,0) [0|1] ""  CGM_HS,EOCM2B_K1_HS,BCM_HS,EOCM2A_K1_HS
 SG_ NAHrDisChrg : 35|28@0+ (0.001,0) [0|268435.455] "AmpHours"  CGM_HS,EOCM2B_K1_HS,BCM_HS,EOCM2A_K1_HS
 SG_ NAHrChgM : 7|1@0+ (1,0) [0|1] ""  CGM_HS,EOCM2B_K1_HS,BCM_HS,EOCM2A_K1_HS
 SG_ NAHrChg : 3|28@0+ (0.001,0) [0|268435.455] "AmpHours"  CGM_HS,EOCM2B_K1_HS,BCM_HS,EOCM2A_K1_HS

BO_ 1034 Curvature_Right_Line_HS: 7 EOCM_F_HS
 SG_ CRL_Cnfdnc : 50|3@0+ (1,0) [0|7] ""  EBCM_OBD_HS,EBCM_HS
 SG_ CRL_ViewRng : 33|15@0+ (0.0039064,0) [0|128.0010088] "m"  EBCM_OBD_HS,EBCM_HS
 SG_ CRL_CoefdA : 17|16@0- (3.6622e-09,0) [-0.0001200029696|0.0001199993074] "1/m^2"  EBCM_OBD_HS,EBCM_HS
 SG_ CRL_CoefA : 1|16@0- (6.1036e-07,0) [-0.02000027648|0.01999966612] "1/m"  EBCM_OBD_HS,EBCM_HS

BO_ 1033 Curvature_Left_Line_HS: 7 EOCM_F_HS
 SG_ CLL_Cnfdnc : 50|3@0+ (1,0) [0|7] ""  EBCM_OBD_HS,EBCM_HS
 SG_ CLL_ViewRng : 33|15@0+ (0.0039064,0) [0|128.0010088] "m"  EBCM_OBD_HS,EBCM_HS
 SG_ CLL_CoefdA : 17|16@0- (3.6622e-09,0) [-0.0001200029696|0.0001199993074] "1/m^2"  EBCM_OBD_HS,EBCM_HS
 SG_ CLL_CoefA : 1|16@0- (6.1036e-07,0) [-0.02000027648|0.01999966612] "1/m"  EBCM_OBD_HS,EBCM_HS

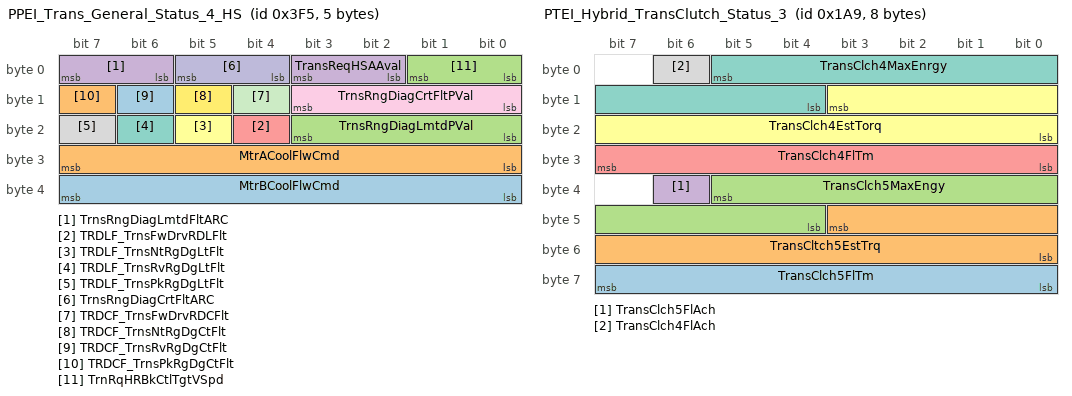
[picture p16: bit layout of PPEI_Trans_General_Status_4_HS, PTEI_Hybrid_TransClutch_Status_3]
BO_ 1013 PPEI_Trans_General_Status_4_HS: 5 TCM_HS
 SG_ MtrBCoolFlwCmd : 39|8@0+ (0.05,0) [0|12.75] "l/min"  CGM_HS,TCM_HS
 SG_ MtrACoolFlwCmd : 31|8@0+ (0.05,0) [0|12.75] "l/min"  CGM_HS,TCM_HS
 SG_ TrnsRngDiagLmtdPVal : 19|4@0+ (1,0) [0|15] ""  CGM_HS,ECM_HS,ICCM_HS
 SG_ TrnsRngDiagLmtdFltARC : 7|2@0+ (1,0) [0|3] ""  CGM_HS,ECM_HS,ICCM_HS
 SG_ TRDLF_TrnsFwDrvRDLFlt : 20|1@0+ (1,0) [0|1] ""  CGM_HS,ECM_HS,ICCM_HS
 SG_ TRDLF_TrnsNtRgDgLtFlt : 21|1@0+ (1,0) [0|1] ""  CGM_HS,ECM_HS,ICCM_HS
 SG_ TRDLF_TrnsRvRgDgLtFlt : 22|1@0+ (1,0) [0|1] ""  CGM_HS,ECM_HS,ICCM_HS
 SG_ TRDLF_TrnsPkRgDgLtFlt : 23|1@0+ (1,0) [0|1] ""  CGM_HS,ECM_HS,ICCM_HS
 SG_ TrnsRngDiagCrtFltPVal : 11|4@0+ (1,0) [0|15] ""  CGM_HS,ECM_HS,ICCM_HS
 SG_ TrnsRngDiagCrtFltARC : 5|2@0+ (1,0) [0|3] ""  CGM_HS,ECM_HS,ICCM_HS
 SG_ TRDCF_TrnsFwDrvRDCFlt : 12|1@0+ (1,0) [0|1] ""  CGM_HS,ECM_HS,ICCM_HS
 SG_ TRDCF_TrnsNtRgDgCtFlt : 13|1@0+ (1,0) [0|1] ""  CGM_HS,ECM_HS,ICCM_HS
 SG_ TRDCF_TrnsRvRgDgCtFlt : 14|1@0+ (1,0) [0|1] ""  CGM_HS,ECM_HS,ICCM_HS
 SG_ TRDCF_TrnsPkRgDgCtFlt : 15|1@0+ (1,0) [0|1] ""  CGM_HS,ECM_HS,ICCM_HS
 SG_ TrnRqHRBkCtlTgtVSpd : 1|2@0+ (1,0) [0|3] ""  CGM_HS,EBCM_OBD_HS,EBCM_HS
 SG_ TransReqHSAAval : 3|2@0+ (1,0) [0|3] ""  CGM_HS,EBCM_OBD_HS,EBCM_HS

BO_ 425 PTEI_Hybrid_TransClutch_Status_3: 8 TCM_HS
 SG_ TransClch5FlTm : 63|8@0+ (0.0125,0) [0|3.1875] "s"  CGM_HS,HCP_HS
 SG_ TransCltch5EstTrq : 43|12@0+ (0.5,-5) [-5|2042.5] "Nm"  CGM_HS,HCP_HS
 SG_ TransClch5MaxEngy : 37|10@0+ (50,0) [0|51150] "J"  CGM_HS,HCP_HS
 SG_ TransClch5FlAch : 38|1@0+ (1,0) [0|1] ""  CGM_HS,HCP_HS
 SG_ TransClch4FlTm : 31|8@0+ (0.0125,0) [0|3.1875] "s"  CGM_HS,HCP_HS
 SG_ TransClch4EstTorq : 11|12@0+ (0.5,-5) [-5|2042.5] "Nm"  CGM_HS,HCP_HS
 SG_ TransClch4MaxEnrgy : 5|10@0+ (50,0) [0|51150] "J"  CGM_HS,HCP_HS
 SG_ TransClch4FlAch : 6|1@0+ (1,0) [0|1] ""  CGM_HS,HCP_HS

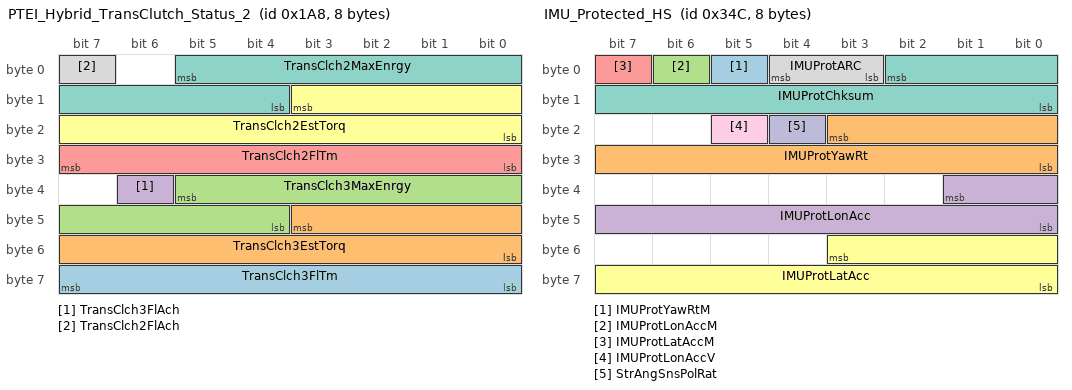
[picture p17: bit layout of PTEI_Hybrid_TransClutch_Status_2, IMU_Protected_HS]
BO_ 424 PTEI_Hybrid_TransClutch_Status_2: 8 TCM_HS
 SG_ TransClch3FlTm : 63|8@0+ (0.0125,0) [0|3.1875] "s"  CGM_HS,HCP_HS
 SG_ TransClch3EstTorq : 43|12@0+ (0.5,-5) [-5|2042.5] "Nm"  CGM_HS,HCP_HS
 SG_ TransClch3MaxEnrgy : 37|10@0+ (50,0) [0|51150] "J"  CGM_HS,HCP_HS
 SG_ TransClch3FlAch : 38|1@0+ (1,0) [0|1] ""  CGM_HS,HCP_HS
 SG_ TransClch2FlTm : 31|8@0+ (0.0125,0) [0|3.1875] "s"  CGM_HS,HCP_HS
 SG_ TransClch2EstTorq : 11|12@0+ (0.5,-5) [-5|2042.5] "Nm"  CGM_HS,HCP_HS
 SG_ TransClch2MaxEnrgy : 5|10@0+ (50,0) [0|51150] "J"  CGM_HS,HCP_HS
 SG_ TransClch2FlAch : 7|1@0+ (1,0) [0|1] ""  CGM_HS,HCP_HS

BO_ 324 Active_Vbn_CntrlMalfunctn_Ind_HS: 1 AVM_HS
 SG_ ActVbnCtrlMlfIO : 0|1@0+ (1,0) [0|1] ""  CGM_HS,BCM_HS

BO_ 844 IMU_Protected_HS: 8 EBCM_HS
 SG_ IMUProtYawRtM : 5|1@0+ (1,0) [0|1] ""  TCCM_HS,V2V_HS,CGM_HS,FCM_HS,EPS_HS
 SG_ IMUProtYawRt : 19|12@0- (0.0625,0) [-128|127.9375] "deg/sec"  TCCM_HS,V2V_HS,CGM_HS,FCM_HS,EPS_HS
 SG_ IMUProtLonAccM : 6|1@0+ (1,0) [0|1] ""  TCCM_HS,V2V_HS,CGM_HS,FCM_HS,EPS_HS
 SG_ IMUProtLonAcc : 33|10@0- (0.03,0) [-15.36|15.33] "m/s^2"  TCCM_HS,V2V_HS,ICCM_B_HS,ICCM_OBD_HS,ICCM_HS,ALC_HS,SADS_HS,EDI_HS,CGM_HS,FCM_HS,VES_HS,EPB_HS,ACC_HS,RDCM_HS,BCM_HS,EPS_HS
 SG_ IMUProtLatAccM : 7|1@0+ (1,0) [0|1] ""  TCCM_HS,V2V_HS,CGM_HS,FCM_HS,EPS_HS
 SG_ IMUProtLatAcc : 51|12@0- (0.015625,0) [-32|31.984375] "m/s^2"  TCCM_HS,V2V_HS,CGM_HS,FCM_HS,EPS_HS
 SG_ IMUProtChksum : 2|11@0+ (1,0) [0|2047] ""  TCCM_HS,V2V_HS,CGM_HS,FCM_HS,EPS_HS
 SG_ IMUProtARC : 4|2@0+ (1,0) [0|3] ""  TCCM_HS,V2V_HS,CGM_HS,FCM_HS,EPS_HS
 SG_ IMUProtLonAccV : 21|1@0+ (1,0) [0|1] ""  TCCM_HS,V2V_HS,ICCM_B_HS,ICCM_OBD_HS,ICCM_HS,ALC_HS,SADS_HS,FCM_HS,EDI_HS,VES_HS,EPS_HS,EPB_HS,ACC_HS,RDCM_HS,BCM_HS,CGM_HS
 SG_ StrAngSnsPolRat : 20|1@0+ (1,0) [0|1] ""  TCCM_HS,V2V_HS,FCM_HS,CGM_HS,EPS_HS

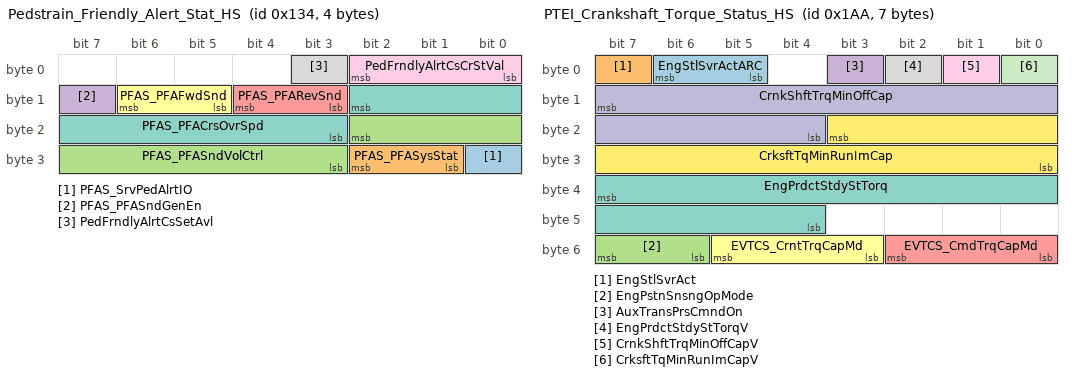
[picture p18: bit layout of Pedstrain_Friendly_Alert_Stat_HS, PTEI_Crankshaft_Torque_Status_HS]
BO_ 308 Pedstrain_Friendly_Alert_Stat_HS: 4 PFAF_HS
 SG_ PFAS_SrvPedAlrtIO : 24|1@0+ (1,0) [0|1] ""  BCM_HS
 SG_ PFAS_PFASysStat : 26|2@0+ (1,0) [0|3] ""  BCM_HS
 SG_ PFAS_PFASndVolCtrl : 18|8@0+ (0.392157,0) [0|100.000035] "%"  BCM_HS
 SG_ PFAS_PFASndGenEn : 15|1@0+ (1,0) [0|1] ""  BCM_HS
 SG_ PFAS_PFARevSnd : 12|2@0+ (1,0) [0|3] ""  BCM_HS
 SG_ PFAS_PFAFwdSnd : 14|2@0+ (1,0) [0|3] ""  BCM_HS
 SG_ PFAS_PFACrsOvrSpd : 10|8@0+ (1,0) [0|255] "km/h"  BCM_HS
 SG_ PedFrndlyAlrtCsSetAvl : 3|1@0+ (1,0) [0|1] ""  BCM_HS
 SG_ PedFrndlyAlrtCsCrStVal : 2|3@0+ (1,0) [0|7] ""  BCM_HS

BO_ 806 DC_Converter_Stabilization_HS: 1 DCDC_HS
 SG_ DCCnvStblznErrIO : 0|1@0+ (1,0) [0|1] ""  CGM_HS,BCM_HS,ECM_HS

BO_ 426 PTEI_Crankshaft_Torque_Status_HS: 7 ECM_HS
 SG_ EngStlSvrActARC : 6|2@0+ (1,0) [0|3] ""  CGM_HS,TCM_HS
 SG_ EngStlSvrAct : 7|1@0+ (1,0) [0|1] ""  CGM_HS,TCM_HS
 SG_ EngPstnSnsngOpMode : 55|2@0+ (1,0) [0|3] ""  CGM_HS,HCP_T_HS,HCP_HS,HCP_B_HS
 SG_ AuxTransPrsCmndOn : 3|1@0+ (1,0) [0|1] ""  CGM_HS,TCM_HS
 SG_ EVTCS_CmdTrqCapMd : 50|3@0+ (1,0) [0|7] ""  CGM_HS,HCP_T_HS,TCM_HS,HCP_HS,HCP_B_HS
 SG_ EVTCS_CrntTrqCapMd : 53|3@0+ (1,0) [0|7] ""  CGM_HS,HCP_T_HS,TCM_HS,HCP_HS,HCP_B_HS
 SG_ EngPrdctStdyStTorq : 39|12@0+ (0.5,-848) [-848|1199.5] "Nm"  CGM_HS,TCM_HS
 SG_ EngPrdctStdyStTorqV : 2|1@0+ (1,0) [0|1] ""  CGM_HS,TCM_HS
 SG_ CrnkShftTrqMinOffCapV : 1|1@0+ (1,0) [0|1] ""  CGM_HS,TCM_HS
 SG_ CrnkShftTrqMinOffCap : 15|12@0+ (0.5,-848) [-848|1199.5] "Nm"  CGM_HS,TCM_HS
 SG_ CrksftTqMinRunImCapV : 0|1@0+ (1,0) [0|1] ""  CGM_HS,TCM_HS
 SG_ CrksftTqMinRunImCap : 19|12@0+ (0.5,-848) [-848|1199.5] "Nm"  CGM_HS,TCM_HS

BO_ 1231 PPEI_Diesel_Exhaust_Gen_Status_2: 3 ECM_HS
 SG_ DslExhFluidDistTIndcmt : 14|15@0+ (2,0) [0|65534] "km"  CGM_HS,BCM_HS
 SG_ DslExhFluidLvlPrcntV : 15|1@0+ (1,0) [0|1] ""  CGM_HS,BCM_HS
 SG_ DslExhFluidLvlPrcnt : 7|8@0+ (0.392157,0) [0|100.000035] "%"  CGM_HS,BCM_HS

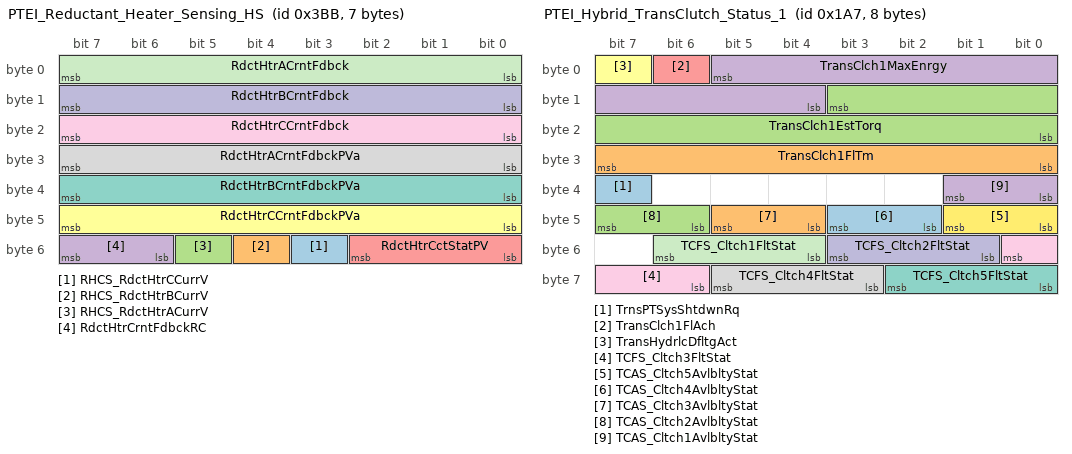
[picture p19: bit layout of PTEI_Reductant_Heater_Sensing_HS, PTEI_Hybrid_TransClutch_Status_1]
BO_ 955 PTEI_Reductant_Heater_Sensing_HS: 7 GPCM_HS
 SG_ RHCS_RdctHtrCCurrV : 51|1@0+ (1,0) [0|1] ""  CGM_HS,ECM_HS
 SG_ RHCS_RdctHtrBCurrV : 52|1@0+ (1,0) [0|1] ""  CGM_HS,ECM_HS
 SG_ RHCS_RdctHtrACurrV : 53|1@0+ (1,0) [0|1] ""  CGM_HS,ECM_HS
 SG_ RdctHtrCrntFdbckRC : 55|2@0+ (1,0) [0|3] ""  CGM_HS,ECM_HS
 SG_ RdctHtrCctStatPV : 50|3@0+ (1,0) [0|7] ""  CGM_HS,ECM_HS
 SG_ RdctHtrCCrntFdbckPVa : 47|8@0+ (1,0) [0|255] ""  CGM_HS,ECM_HS
 SG_ RdctHtrBCrntFdbckPVa : 39|8@0+ (1,0) [0|255] ""  CGM_HS,ECM_HS
 SG_ RdctHtrACrntFdbckPVa : 31|8@0+ (1,0) [0|255] ""  CGM_HS,ECM_HS
 SG_ RdctHtrCCrntFdbck : 23|8@0+ (0.117647,0) [0|29.999985] "A"  CGM_HS,ECM_HS
 SG_ RdctHtrBCrntFdbck : 15|8@0+ (0.117647,0) [0|29.999985] "A"  CGM_HS,ECM_HS
 SG_ RdctHtrACrntFdbck : 7|8@0+ (0.117647,0) [0|29.999985] "A"  CGM_HS,ECM_HS

BO_ 423 PTEI_Hybrid_TransClutch_Status_1: 8 TCM_HS
 SG_ TrnsPTSysShtdwnRq : 39|1@0+ (1,0) [0|1] ""  CGM_HS,HCP_HS
 SG_ TransClch1FlTm : 31|8@0+ (0.0125,0) [0|3.1875] "s"  CGM_HS,HCP_HS
 SG_ TransClch1EstTorq : 11|12@0+ (0.5,-5) [-5|2042.5] "Nm"  CGM_HS,HCP_HS
 SG_ TransClch1MaxEnrgy : 5|10@0+ (50,0) [0|51150] "J"  CGM_HS,HCP_HS
 SG_ TransClch1FlAch : 6|1@0+ (1,0) [0|1] ""  CGM_HS,HCP_HS
 SG_ TransHydrlcDfltgAct : 7|1@0+ (1,0) [0|1] ""  CGM_HS,HCP_HS
 SG_ TCFS_Cltch5FltStat : 58|3@0+ (1,0) [0|7] ""  CGM_HS,HCP_HS
 SG_ TCFS_Cltch4FltStat : 61|3@0+ (1,0) [0|7] ""  CGM_HS,HCP_HS
 SG_ TCFS_Cltch3FltStat : 48|3@0+ (1,0) [0|7] ""  CGM_HS,HCP_HS
 SG_ TCFS_Cltch2FltStat : 51|3@0+ (1,0) [0|7] ""  CGM_HS,HCP_HS
 SG_ TCFS_Cltch1FltStat : 54|3@0+ (1,0) [0|7] ""  CGM_HS,HCP_HS
 SG_ TCAS_Cltch5AvlbltyStat : 41|2@0+ (1,0) [0|3] ""  CGM_HS,HCP_HS
 SG_ TCAS_Cltch4AvlbltyStat : 43|2@0+ (1,0) [0|3] ""  CGM_HS,HCP_HS
 SG_ TCAS_Cltch3AvlbltyStat : 45|2@0+ (1,0) [0|3] ""  CGM_HS,HCP_HS
 SG_ TCAS_Cltch2AvlbltyStat : 47|2@0+ (1,0) [0|3] ""  CGM_HS,HCP_HS
 SG_ TCAS_Cltch1AvlbltyStat : 33|2@0+ (1,0) [0|3] ""  CGM_HS,HCP_HS

BO_ 2034 CCP_Data_Transmission_Object_HS: 8 BCM_HS
 SG_ DgnInf : 7|64@0+ (1,0) [0|1.8446744074e+19] ""  CGM_HS,TestTool_HS

BO_ 2032 CCP_Command_Receive_Object_HS: 8 TestTool_HS
 SG_ DgnInf : 7|64@0+ (1,0) [0|1.8446744074e+19] ""  CGM_HS,TTPM_HS,FCM_HS,PTO_HS,BCM_HS

BO_ 563 Performance_Mode_Cust_Setings_HS: 5 EBCM_HS
 SG_ SPMCA_SusPrfMd6Avl : 32|1@0+ (1,0) [0|1] ""  CGM_HS,EOCM2B_K1_HS,EOCM2A_K1_HS,BCM_HS
 SG_ SPMCA_SusPrfMd5Avl : 33|1@0+ (1,0) [0|1] ""  CGM_HS,EOCM2B_K1_HS,EOCM2A_K1_HS,BCM_HS
 SG_ SPMCA_SusPrfMd4Avl : 34|1@0+ (1,0) [0|1] ""  CGM_HS,EOCM2B_K1_HS,EOCM2A_K1_HS,BCM_HS
 SG_ SPMCA_SusPrfMd3Avl : 35|1@0+ (1,0) [0|1] ""  CGM_HS,EOCM2B_K1_HS,EOCM2A_K1_HS,BCM_HS
 SG_ SPMCA_SusPrfMd2Avl : 36|1@0+ (1,0) [0|1] ""  CGM_HS,EOCM2B_K1_HS,EOCM2A_K1_HS,BCM_HS
 SG_ SPMCA_SusPrfMd1Avl : 37|1@0+ (1,0) [0|1] ""  CGM_HS,EOCM2B_K1_HS,EOCM2A_K1_HS,BCM_HS
 SG_ SPMCA_StrPrfMd6Avl : 24|1@0+ (1,0) [0|1] ""  CGM_HS,EOCM2B_K1_HS,EOCM2A_K1_HS,BCM_HS
 SG_ SPMCA_StrPrfMd5Avl : 25|1@0+ (1,0) [0|1] ""  CGM_HS,EOCM2B_K1_HS,EOCM2A_K1_HS,BCM_HS
 SG_ SPMCA_StrPrfMd4Avl : 26|1@0+ (1,0) [0|1] ""  CGM_HS,EOCM2B_K1_HS,EOCM2A_K1_HS,BCM_HS
 SG_ SPMCA_StrPrfMd3Avl : 27|1@0+ (1,0) [0|1] ""  CGM_HS,EOCM2B_K1_HS,EOCM2A_K1_HS,BCM_HS
 SG_ SPMCA_StrPrfMd2Avl : 28|1@0+ (1,0) [0|1] ""  CGM_HS,EOCM2B_K1_HS,EOCM2A_K1_HS,BCM_HS
 SG_ SPMCA_StrPrfMd1Avl : 29|1@0+ (1,0) [0|1] ""  CGM_HS,EOCM2B_K1_HS,EOCM2A_K1_HS,BCM_HS
 SG_ SPMCA_SndPrfMd6Avl : 16|1@0+ (1,0) [0|1] ""  CGM_HS,EOCM2B_K1_HS,EOCM2A_K1_HS,BCM_HS
 SG_ SPMCA_SndPrfMd5Avl : 17|1@0+ (1,0) [0|1] ""  CGM_HS,EOCM2B_K1_HS,EOCM2A_K1_HS,BCM_HS
 SG_ SPMCA_SndPrfMd4Avl : 18|1@0+ (1,0) [0|1] ""  CGM_HS,EOCM2B_K1_HS,EOCM2A_K1_HS,BCM_HS
 SG_ SPMCA_SndPrfMd3Avl : 19|1@0+ (1,0) [0|1] ""  CGM_HS,EOCM2B_K1_HS,EOCM2A_K1_HS,BCM_HS
 SG_ SPMCA_SndPrfMd2Avl : 20|1@0+ (1,0) [0|1] ""  CGM_HS,EOCM2B_K1_HS,EOCM2A_K1_HS,BCM_HS
 SG_ SPMCA_SndPrfMd1Avl : 21|1@0+ (1,0) [0|1] ""  CGM_HS,EOCM2B_K1_HS,EOCM2A_K1_HS,BCM_HS
 SG_ DPMCA_DispPrfMd6Avl : 8|1@0+ (1,0) [0|1] ""  CGM_HS,EOCM2B_K1_HS,EOCM2A_K1_HS,BCM_HS
 SG_ DPMCA_DispPrfMd5Avl : 9|1@0+ (1,0) [0|1] ""  CGM_HS,EOCM2B_K1_HS,EOCM2A_K1_HS,BCM_HS
 SG_ DPMCA_DispPrfMd4Avl : 10|1@0+ (1,0) [0|1] ""  CGM_HS,EOCM2B_K1_HS,EOCM2A_K1_HS,BCM_HS
 SG_ DPMCA_DispPrfMd3Avl : 11|1@0+ (1,0) [0|1] ""  CGM_HS,EOCM2B_K1_HS,EOCM2A_K1_HS,BCM_HS
 SG_ DPMCA_DispPrfMd2Avl : 12|1@0+ (1,0) [0|1] ""  CGM_HS,EOCM2B_K1_HS,EOCM2A_K1_HS,BCM_HS
 SG_ DPMCA_DispPrfMd1Avl : 13|1@0+ (1,0) [0|1] ""  CGM_HS,EOCM2B_K1_HS,EOCM2A_K1_HS,BCM_HS
 SG_ DPMCA_DrvlPrfMd6Avl : 0|1@0+ (1,0) [0|1] ""  CGM_HS,EOCM2B_K1_HS,EOCM2A_K1_HS,BCM_HS
 SG_ DPMCA_DrvlPrfMd5Avl : 1|1@0+ (1,0) [0|1] ""  CGM_HS,EOCM2B_K1_HS,EOCM2A_K1_HS,BCM_HS
 SG_ DPMCA_DrvlPrfMd4Avl : 2|1@0+ (1,0) [0|1] ""  CGM_HS,EOCM2B_K1_HS,EOCM2A_K1_HS,BCM_HS
 SG_ DPMCA_DrvlPrfMd3Avl : 3|1@0+ (1,0) [0|1] ""  CGM_HS,EOCM2B_K1_HS,EOCM2A_K1_HS,BCM_HS
 SG_ DPMCA_DrvlPrfMd2Avl : 4|1@0+ (1,0) [0|1] ""  CGM_HS,EOCM2B_K1_HS,EOCM2A_K1_HS,BCM_HS
 SG_ DPMCA_DrvlPrfMd1Avl : 5|1@0+ (1,0) [0|1] ""  CGM_HS,EOCM2B_K1_HS,EOCM2A_K1_HS,BCM_HS

CM_ "Primary High Speed GMLAN
HS  bus is affected in Version 19.19.131_170224 [Haritha Sunku , 24 Feb 2017]";
CM_ BU_ EOCM2B_IMX6_HS "External Object Control Module 2B - IMX6 micro";
CM_ BU_ EOCM2A_IMX6_HS "External Object Control Module 2A - IMX6 micro";
CM_ BU_ EOCM2B_K2_HS "External Object Control Module 2B - K2 micro";
CM_ BU_ EOCM2A_K2_HS "External Object Control Module 2A - K2 micro";
CM_ BU_ TTPM_HS "Trailer Tire Pressure Module";
CM_ BU_ AMM_HS "ADAS Map Module";
CM_ BU_ EBOOST_OBD_HS "Electric Brake Booster OBD";
CM_ BU_ CGM_HS "Communication Gateway";
CM_ BU_ BSM_HS "Battery State Manager";
CM_ BU_ HCP_B_HS "Hybrid Control Processor for BAS";
CM_ BU_ AVM_HS "Active Vibration Module";
CM_ BU_ PFAF_HS "Pedestrian Friendly Alert Function";
CM_ BU_ LVMPC_HS "Low Volume Module (Performance Computer )";
CM_ BU_ DCDC_HS "DC/DC Converter";
CM_ BU_ DEFC_HS "Diesel Exhaust Fluid Controller";
CM_ BU_ VPM_HS "Video Processing Module";
CM_ BU_ IPC_HS "Instrument Panel Cluster";
CM_ BU_ V2V_HS "Vehicle To Vehicle";
CM_ BU_ TCP_HS "Telematics Connectivity Platform";
CM_ BU_ CSM_HS "Center Stack Module";
CM_ BU_ EOCM2B_K1_HS "External Object Control Module 2B - K1 micro";
CM_ BU_ EOCM2A_K1_HS "External Object Control Module 2A - K1 micro";
CM_ BU_ TRCM_HS "Transmission Range Control Module";
CM_ BU_ ESCM_SP_HS "Energy Storage Control Module Secondary Power";
CM_ BU_ ICCM_B_HS "Integrated Chassis Control Module - Auxiliary";
CM_ BU_ AMP_HS "Audio Amplifier";
CM_ BU_ FICM_HS "Fuel Injection Control Module";
CM_ BU_ ARS_HS "Active Rear Steering";
CM_ BU_ MCP_B_HS "Motor Control Processor B(part of TPIM-Traction Powertrain Inverter Module)";
CM_ BU_ MCP_A_HS "Motor Control Processor A(part of TPIM-Traction Powertrain Inverter Module)";
CM_ BU_ ICCM_OBD_HS "Integrated Chassis Control Module";
CM_ BU_ SAS_HS "Steering Angle Sensor";
CM_ BU_ ACCM_HS "Air Conditioning Control Module";
CM_ BU_ VLBS_HS "Vehicle Location & Blocking System";
CM_ BU_ EBCM_OBD_HS "Electronic Brake Control Module";
CM_ BU_ HCP_T_HS "Hybrid Control Processor with up-integrated Trans and Motor Controls";
CM_ BU_ EDI_HS "Enhanced Driver Interface";
CM_ BU_ PLCM_HS "Power Line Communication Module";
CM_ BU_ VITM_OBD_HS "Voltage, Current, Temperature Module BAS+";
CM_ BU_ VICM_HS "Vehicle Integration Control Module 4Mode";
CM_ BU_ HCP_HS "Hybrid Control Processor";
CM_ BU_ APPS_HS "Active Pedestrian Protection System";
CM_ BU_ ICCM_HS "Integrated Chassis Control Module";
CM_ BU_ EOCM_F_HS "External Object Control Module - Front";
CM_ BU_ GPCM_HS "Glow Plug Control Module";
CM_ BU_ VCM_HS "Vaporizer Control Module";
CM_ BU_ HMIM_HS "Next-Gen Infotainment HMIModule ";
CM_ BU_ VES_HS "Variable Effort Steering";
CM_ BU_ Dummy_HS "This is for avoid signle ended signalling";
CM_ BU_ MCP_C_HS "Motor control processor C";
CM_ BU_ ONSTAR_HS "OnStar Module";
CM_ BU_ EPS_HS "Electronic Power Steering";
CM_ BU_ MCP_HS "Motor Control Processor";
CM_ BU_ BCP_HS "BAS+";
CM_ BU_ ALC_HS "Automatic Level Control";
CM_ BU_ AHL_AFL_HS "Automatic Headlamp Levelling";
CM_ BU_ SADS_HS "Semi Active Damping System";
CM_ BU_ EPB_HS "Electronic Park Brake";
CM_ BU_ FCM_HS "Front Camera Module";
CM_ BU_ TCCM_HS "Transfer Case Control Module";
CM_ BU_ RDCM_HS "Rear Drive Control Module";
CM_ BU_ PTO_HS "Power TakeOff Module";
CM_ BU_ EBCM_HS "Electronic Brake Control Module";
CM_ BU_ ACC_HS "Adaptive Cruise Control";
CM_ BU_ BCM_HS "HS Side Global Architecture Gateway and Body Control Module";
CM_ BU_ TCM_HS "Transmission Control Module";
CM_ BU_ ECM_HS "Engine Control Module";
CM_ SG_ 1277 PrkHtrCoolntTempM "Shortname of the signal in CSD is PrkHtrCoolntTempMsk. This is a known discrepancy.";
CM_ SG_ 1263 BatSOH "State of Health = the aging state of the Battery";
BA_DEF_  "BusType" STRING ;
BA_DEF_ SG_  "VNSigSLHSSharedDiagnostic" ENUM  "No","Yes","DLCLS","DLCHS","DLCCE","DLCFO";
BA_DEF_ SG_  "SignalType" STRING ;
BA_DEF_ SG_  "PacketOrder" INT 0 65535;
BA_DEF_ SG_  "SignalLongName" STRING ;
BA_DEF_ SG_  "GenSigStartValue" INT 0 65535;
BA_DEF_ SG_  "VNSigAllNodes" ENUM  "No","Yes","DLCLS","DLCHS","DLCCE","DLCFO";
BA_DEF_ SG_  "GenSigSendType" ENUM  "not used","not used","not used","not used","not used","not used","not used","NoSigSendType","not used","not used","OnAnyChange","OnChangeIfActive","OnDelta","DLCLS","DLCHS","DLCCE","DLCFO";
BA_DEF_ SG_  "GenSigSendOnInit" ENUM  "Not Initialized","Application","Handler","DLCLS","DLCHS","DLCCE","DLCFO";
BA_DEF_ BO_  "AppGenMsgCycleTime" INT 0 0;
BA_DEF_ BO_  "GenMsgILSupport" ENUM  "No","Yes","DLCLS","DLCHS","DLCCE","DLCFO";
BA_DEF_ BO_  "TpApplType" STRING ;
BA_DEF_ BO_  "Prio" INT 0 7;
BA_DEF_ BO_  "MessageSubnet" ENUM  "LS","MS","HS","CE","PE","HV","FO","S1","HE","LE","HE2","DLCLS","DLCHS","DLCCE","DLCFO";
BA_DEF_ BO_  "DiagState" ENUM  "No","Yes","DLCLS","DLCHS","DLCCE","DLCFO";
BA_DEF_ BO_  "GenMsgStartDelayTime" INT 0 100000;
BA_DEF_ BO_  "GenMsgDelayTime" INT 0 100000;
BA_DEF_ BO_  "GenMsgCycleTime" INT 0 100000;
BA_DEF_ BO_  "GenMsgSendType" ENUM  "cyclicX","spontanX","cyclicIfActiveX","spontanWithDelay","cyclicAndSpontanX","cyclicAndSpontanWithDelay","spontanWithRepitition","cyclicIfActiveAndSpontanWD","DLCLS","DLCHS","DLCCE","DLCFO";
BA_DEF_ BO_  "DiagResponse" ENUM  "No","Yes","DLCLS","DLCHS","DLCCE","DLCFO";
BA_DEF_ BO_  "DiagRequest" ENUM  "No","Yes","DLCLS","DLCHS","DLCCE","DLCFO";
BA_DEF_ BO_  "NmMessage" ENUM  "No","Yes","DLCLS","DLCHS","DLCCE","DLCFO";
BA_DEF_ BU_  "MessageManagerUsed" ENUM  "No","Yes","DLCLS","DLCHS","DLCCE","DLCFO";
BA_DEF_ BU_  "NmNode" ENUM  "No","Yes","DLCLS","DLCHS","DLCCE","DLCFO";
BA_DEF_ BU_  "ILUsed" ENUM  "No","Yes","DLCLS","DLCHS","DLCCE","DLCFO";
BA_DEF_ BU_  "NodeLayerModules" STRING ;
BA_DEF_ BU_  "VNECUSLHS_VNReq" ENUM  "None","Activator","Remoted","Activator and Remoted","Shared Local","DLCLS","DLCHS","DLCCE","DLCFO";
BA_DEF_ BU_  "VNECUSLHSSharedDiagnostic" ENUM  "None","Activator","Remoted","Activator and Remoted","Shared Local","DLCLS","DLCHS","DLCCE","DLCFO";
BA_DEF_ BU_  "VNECUAllNodes" ENUM  "None","Activator","Remoted","Activator and Remoted","Shared Local","DLCLS","DLCHS","DLCCE","DLCFO";
BA_DEF_ BU_  "ECU_Id" HEX 0 255;
BA_DEF_ BU_  "SourceId" HEX 0 253;
BA_DEF_  "VersionMonth" INT 0 255;
BA_DEF_  "SyncJumpWidthMax" INT 0 255;
BA_DEF_  "SyncJumpWidthMin" INT 0 255;
BA_DEF_  "SamplePointMax" FLOAT 0 100;
BA_DEF_  "SamplePointMin" FLOAT 0 100;
BA_DEF_  "Baudrate" INT 0 1000000;
BA_DEF_  "VehicleArchitecture" STRING ;
BA_DEF_  "VNInitActSLHS_VNReq" ENUM  "No","Yes","DLCLS","DLCHS","DLCCE","DLCFO";
BA_DEF_  "VN_SLHS_VNReq" INT 0 255;
BA_DEF_  "VNInitActSLHSSharedDiagnostic" ENUM  "No","Yes","DLCLS","DLCHS","DLCCE","DLCFO";
BA_DEF_  "VN_SLHSSharedDiagnostic" INT 0 255;
BA_DEF_  "NmMessageCount" INT 0 32;
BA_DEF_  "NmBaseAddress" HEX 0 2032;
BA_DEF_  "NetworkType" STRING ;
BA_DEF_  "VNMFPeriodicInterval" INT 0 65535;
BA_DEF_  "BusWakeUpDelay" INT 0 65535;
BA_DEF_  "BusOffRecoveryTime" INT 0 65535;
BA_DEF_  "NodeStatusMsgID" HEX 0 536870911;
BA_DEF_  "NodeStatusMsgCycleTime" INT 0 65535;
BA_DEF_  "NodeStatusMsgTimeoutTime" INT 0 65535;
BA_DEF_  "UseGMParameterIDs" INT 0 1;
BA_DEF_  "VersionWeek" INT 0 255;
BA_DEF_  "VersionYear" INT 0 255;
BA_DEF_  "VN_AllNodes" INT 0 255;
BA_DEF_  "Manufacturer" ENUM  "DBAG","VAG","BMW","PAG","GM","DLCLS","DLCHS","DLCCE","DLCFO";
BA_DEF_  "NmType" STRING ;
BA_DEF_DEF_  "BusType" "";
BA_DEF_DEF_  "VNSigSLHSSharedDiagnostic" "No";
BA_DEF_DEF_  "SignalType" "";
BA_DEF_DEF_  "PacketOrder" 0;
BA_DEF_DEF_  "SignalLongName" "";
BA_DEF_DEF_  "GenSigStartValue" 0;
BA_DEF_DEF_  "VNSigAllNodes" "No";
BA_DEF_DEF_  "GenSigSendType" "NoSigSendType";
BA_DEF_DEF_  "GenSigSendOnInit" "Not Initialized";
BA_DEF_DEF_  "AppGenMsgCycleTime" 0;
BA_DEF_DEF_  "GenMsgILSupport" "Yes";
BA_DEF_DEF_  "TpApplType" "";
BA_DEF_DEF_  "Prio" 4;
BA_DEF_DEF_  "MessageSubnet" "FO";
BA_DEF_DEF_  "DiagState" "No";
BA_DEF_DEF_  "GenMsgStartDelayTime" 0;
BA_DEF_DEF_  "GenMsgDelayTime" 0;
BA_DEF_DEF_  "GenMsgCycleTime" 0;
BA_DEF_DEF_  "GenMsgSendType" "spontanX";
BA_DEF_DEF_  "DiagResponse" "No";
BA_DEF_DEF_  "DiagRequest" "No";
BA_DEF_DEF_  "NmMessage" "No";
BA_DEF_DEF_  "MessageManagerUsed" "Yes";
BA_DEF_DEF_  "NmNode" "Yes";
BA_DEF_DEF_  "ILUsed" "Yes";
BA_DEF_DEF_  "NodeLayerModules" "gmlan02.dll";
BA_DEF_DEF_  "VNECUSLHS_VNReq" "None";
BA_DEF_DEF_  "VNECUSLHSSharedDiagnostic" "None";
BA_DEF_DEF_  "VNECUAllNodes" "None";
BA_DEF_DEF_  "ECU_Id" 0;
BA_DEF_DEF_  "SourceId" 0;
BA_DEF_DEF_  "VersionMonth" 0;
BA_DEF_DEF_  "SyncJumpWidthMax" 0;
BA_DEF_DEF_  "SyncJumpWidthMin" 0;
BA_DEF_DEF_  "SamplePointMax" 0;
BA_DEF_DEF_  "SamplePointMin" 0;
BA_DEF_DEF_  "Baudrate" 0;
BA_DEF_DEF_  "VehicleArchitecture" "";
BA_DEF_DEF_  "VNInitActSLHS_VNReq" "No";
BA_DEF_DEF_  "VN_SLHS_VNReq" 2;
BA_DEF_DEF_  "VNInitActSLHSSharedDiagnostic" "No";
BA_DEF_DEF_  "VN_SLHSSharedDiagnostic" 0;
BA_DEF_DEF_  "NmMessageCount" 32;
BA_DEF_DEF_  "NmBaseAddress" 1568;
BA_DEF_DEF_  "NetworkType" "";
BA_DEF_DEF_  "VNMFPeriodicInterval" 3000;
BA_DEF_DEF_  "BusWakeUpDelay" 100;
BA_DEF_DEF_  "BusOffRecoveryTime" 0;
BA_DEF_DEF_  "NodeStatusMsgID" 268427264;
BA_DEF_DEF_  "NodeStatusMsgCycleTime" 1200;
BA_DEF_DEF_  "NodeStatusMsgTimeoutTime" 0;
BA_DEF_DEF_  "UseGMParameterIDs" 1;
BA_DEF_DEF_  "VersionWeek" 0;
BA_DEF_DEF_  "VersionYear" 0;
BA_DEF_DEF_  "VN_AllNodes" 1;
BA_DEF_DEF_  "Manufacturer" "GM";
BA_DEF_DEF_  "NmType" "GMLAN";
BA_ "BusType" "CAN";
BA_ "VersionYear" 19;
BA_ "VersionWeek" 31;
BA_ "UseGMParameterIDs" 0;
BA_ "NodeStatusMsgID" 0;
BA_ "BusOffRecoveryTime" 160;
BA_ "NetworkType" "Powertrain";
BA_ "NmBaseAddress" 1536;
BA_ "NmMessageCount" 16;
BA_ "VNInitActSLHSSharedDiagnostic" 1;
BA_ "VNInitActSLHS_VNReq" 1;
BA_ "VehicleArchitecture" "Global A";
BA_ "Baudrate" 500000;
BA_ "SamplePointMin" 80;
BA_ "SamplePointMax" 81.25;
BA_ "SyncJumpWidthMin" 3;
BA_ "SyncJumpWidthMax" 4;
BA_ "VersionMonth" 19;
BA_ "DiagResponse" BO_ 1798 1;
BA_ "MessageSubnet" BO_ 1798 2;
BA_ "Prio" BO_ 1798 0;
BA_ "VNSigAllNodes" SG_ 1798 DgnInf 1;
BA_ "SignalLongName" SG_ 1798 DgnInf "Diagnostic Information";
BA_ "SignalType" SG_ 1798 DgnInf "UNM";
BA_ "VNSigSLHSSharedDiagnostic" SG_ 1798 DgnInf 1;
BA_ "DiagRequest" BO_ 1800 1;
BA_ "MessageSubnet" BO_ 1800 2;
BA_ "Prio" BO_ 1800 0;
BA_ "VNSigAllNodes" SG_ 1800 DgnInf 1;
BA_ "SignalLongName" SG_ 1800 DgnInf "Diagnostic Information";
BA_ "SignalType" SG_ 1800 DgnInf "UNM";
BA_ "VNSigSLHSSharedDiagnostic" SG_ 1800 DgnInf 1;
BA_ "DiagResponse" BO_ 1808 1;
BA_ "MessageSubnet" BO_ 1808 2;
BA_ "Prio" BO_ 1808 0;
BA_ "VNSigAllNodes" SG_ 1808 DgnInf 1;
BA_ "SignalLongName" SG_ 1808 DgnInf "Diagnostic Information";
BA_ "SignalType" SG_ 1808 DgnInf "UNM";
BA_ "VNSigSLHSSharedDiagnostic" SG_ 1808 DgnInf 1;
BA_ "DiagRequest" BO_ 1810 1;
BA_ "MessageSubnet" BO_ 1810 2;
BA_ "Prio" BO_ 1810 0;
BA_ "VNSigAllNodes" SG_ 1810 DgnInf 1;
BA_ "SignalLongName" SG_ 1810 DgnInf "Diagnostic Information";
BA_ "SignalType" SG_ 1810 DgnInf "UNM";
BA_ "VNSigSLHSSharedDiagnostic" SG_ 1810 DgnInf 1;
BA_ "GenMsgSendType" BO_ 1015 0;
BA_ "GenMsgCycleTime" BO_ 1015 1000;
BA_ "MessageSubnet" BO_ 1015 2;
BA_ "Prio" BO_ 1015 0;
BA_ "VNSigAllNodes" SG_ 1015 ElecMchnCntlrTemp 1;
BA_ "SignalLongName" SG_ 1015 ElecMchnCntlrTemp "Electric Machine Controller Temperature";
BA_ "SignalType" SG_ 1015 ElecMchnCntlrTemp "UNM";
BA_ "GenMsgSendType" BO_ 1012 0;
BA_ "GenMsgCycleTime" BO_ 1012 1000;
BA_ "MessageSubnet" BO_ 1012 2;
BA_ "Prio" BO_ 1012 0;
BA_ "VNSigAllNodes" SG_ 1012 MtrBDCCrnt 1;
BA_ "SignalLongName" SG_ 1012 MtrBDCCrnt "Motor B DC Current";
BA_ "SignalType" SG_ 1012 MtrBDCCrnt "SNM";
BA_ "VNSigAllNodes" SG_ 1012 MtrBDCVltg 1;
BA_ "SignalLongName" SG_ 1012 MtrBDCVltg "Motor B DC Voltage";
BA_ "SignalType" SG_ 1012 MtrBDCVltg "UNM";
BA_ "VNSigAllNodes" SG_ 1012 MtrBTorq 1;
BA_ "SignalLongName" SG_ 1012 MtrBTorq "Motor B Torque";
BA_ "SignalType" SG_ 1012 MtrBTorq "SNM";
BA_ "VNSigAllNodes" SG_ 1012 MtrBTemp 1;
BA_ "SignalLongName" SG_ 1012 MtrBTemp "Motor B Temperature";
BA_ "SignalType" SG_ 1012 MtrBTemp "UNM";
BA_ "VNSigAllNodes" SG_ 1012 MtrBInvSt 1;
BA_ "SignalLongName" SG_ 1012 MtrBInvSt "Motor B Inverter State";
BA_ "SignalType" SG_ 1012 MtrBInvSt "ENM";
BA_ "VNSigAllNodes" SG_ 1012 MtrBDCCrntV 1;
BA_ "SignalLongName" SG_ 1012 MtrBDCCrntV "Motor B DC Current Validity";
BA_ "SignalType" SG_ 1012 MtrBDCCrntV "ENM";
BA_ "VNSigAllNodes" SG_ 1012 MtrBDCVltgV 1;
BA_ "SignalLongName" SG_ 1012 MtrBDCVltgV "Motor B DC Voltage Validity";
BA_ "SignalType" SG_ 1012 MtrBDCVltgV "ENM";
BA_ "VNSigAllNodes" SG_ 1012 MtrBTorqV 1;
BA_ "SignalLongName" SG_ 1012 MtrBTorqV "Motor B Torque Validity";
BA_ "SignalType" SG_ 1012 MtrBTorqV "ENM";
BA_ "VNSigAllNodes" SG_ 1012 MtrBTempV 1;
BA_ "SignalLongName" SG_ 1012 MtrBTempV "Motor B Temperature Validity";
BA_ "SignalType" SG_ 1012 MtrBTempV "ENM";
BA_ "GenMsgSendType" BO_ 1010 0;
BA_ "GenMsgCycleTime" BO_ 1010 1000;
BA_ "MessageSubnet" BO_ 1010 2;
BA_ "Prio" BO_ 1010 0;
BA_ "VNSigAllNodes" SG_ 1010 MtrADCCrnt 1;
BA_ "SignalLongName" SG_ 1010 MtrADCCrnt "Motor A DC Current";
BA_ "SignalType" SG_ 1010 MtrADCCrnt "SNM";
BA_ "VNSigAllNodes" SG_ 1010 MtrADCVltg 1;
BA_ "SignalLongName" SG_ 1010 MtrADCVltg "Motor A DC Voltage";
BA_ "SignalType" SG_ 1010 MtrADCVltg "UNM";
BA_ "VNSigAllNodes" SG_ 1010 MtrATorq 1;
BA_ "SignalLongName" SG_ 1010 MtrATorq "Motor A Torque";
BA_ "SignalType" SG_ 1010 MtrATorq "SNM";
BA_ "VNSigAllNodes" SG_ 1010 MtrATemp 1;
BA_ "SignalLongName" SG_ 1010 MtrATemp "Motor A Temperature";
BA_ "SignalType" SG_ 1010 MtrATemp "UNM";
BA_ "VNSigAllNodes" SG_ 1010 MtrAInvSt 1;
BA_ "SignalLongName" SG_ 1010 MtrAInvSt "Motor A Inverter State";
BA_ "SignalType" SG_ 1010 MtrAInvSt "ENM";
BA_ "VNSigAllNodes" SG_ 1010 MtrADCCrntV 1;
BA_ "SignalLongName" SG_ 1010 MtrADCCrntV "Motor A DC Current Validity";
BA_ "SignalType" SG_ 1010 MtrADCCrntV "ENM";
BA_ "VNSigAllNodes" SG_ 1010 MtrADCVltgV 1;
BA_ "SignalLongName" SG_ 1010 MtrADCVltgV "Motor A DC Voltage Validity";
BA_ "SignalType" SG_ 1010 MtrADCVltgV "ENM";
BA_ "VNSigAllNodes" SG_ 1010 MtrATorqV 1;
BA_ "SignalLongName" SG_ 1010 MtrATorqV "Motor A Torque Validity";
BA_ "SignalType" SG_ 1010 MtrATorqV "ENM";
BA_ "VNSigAllNodes" SG_ 1010 MtrATempV 1;
BA_ "SignalLongName" SG_ 1010 MtrATempV "Motor A Temperature Validity";
BA_ "SignalType" SG_ 1010 MtrATempV "ENM";
BA_ "GenMsgSendType" BO_ 430 0;
BA_ "GenMsgCycleTime" BO_ 430 25;
BA_ "MessageSubnet" BO_ 430 2;
BA_ "Prio" BO_ 430 0;
BA_ "VNSigAllNodes" SG_ 430 TCFS_Cltch5FltStat 1;
BA_ "SignalLongName" SG_ 430 TCFS_Cltch5FltStat "Transmission Clutch Fault Status : Clutch 5 Fault Status";
BA_ "PacketOrder" SG_ 430 TCFS_Cltch5FltStat 5;
BA_ "SignalType" SG_ 430 TCFS_Cltch5FltStat "ENM";
BA_ "VNSigAllNodes" SG_ 430 TCFS_Cltch4FltStat 1;
BA_ "SignalLongName" SG_ 430 TCFS_Cltch4FltStat "Transmission Clutch Fault Status : Clutch 4 Fault Status";
BA_ "PacketOrder" SG_ 430 TCFS_Cltch4FltStat 4;
BA_ "SignalType" SG_ 430 TCFS_Cltch4FltStat "ENM";
BA_ "VNSigAllNodes" SG_ 430 TCFS_Cltch3FltStat 1;
BA_ "SignalLongName" SG_ 430 TCFS_Cltch3FltStat "Transmission Clutch Fault Status : Clutch 3 Fault Status";
BA_ "PacketOrder" SG_ 430 TCFS_Cltch3FltStat 3;
BA_ "SignalType" SG_ 430 TCFS_Cltch3FltStat "ENM";
BA_ "VNSigAllNodes" SG_ 430 TCFS_Cltch2FltStat 1;
BA_ "SignalLongName" SG_ 430 TCFS_Cltch2FltStat "Transmission Clutch Fault Status : Clutch 2 Fault Status";
BA_ "PacketOrder" SG_ 430 TCFS_Cltch2FltStat 2;
BA_ "SignalType" SG_ 430 TCFS_Cltch2FltStat "ENM";
BA_ "VNSigAllNodes" SG_ 430 TCFS_Cltch1FltStat 1;
BA_ "SignalLongName" SG_ 430 TCFS_Cltch1FltStat "Transmission Clutch Fault Status : Clutch 1 Fault Status";
BA_ "PacketOrder" SG_ 430 TCFS_Cltch1FltStat 1;
BA_ "SignalType" SG_ 430 TCFS_Cltch1FltStat "ENM";
BA_ "VNSigAllNodes" SG_ 430 TransClch5FlTm 1;
BA_ "SignalLongName" SG_ 430 TransClch5FlTm "Transmission Clutch 5 Fill Time";
BA_ "SignalType" SG_ 430 TransClch5FlTm "UNM";
BA_ "VNSigAllNodes" SG_ 430 TransClch5FlAch 1;
BA_ "SignalLongName" SG_ 430 TransClch5FlAch "Transmission Clutch 5 Fill Achieved";
BA_ "SignalType" SG_ 430 TransClch5FlAch "BLN";
BA_ "VNSigAllNodes" SG_ 430 TransClch4FlTm 1;
BA_ "SignalLongName" SG_ 430 TransClch4FlTm "Transmission Clutch 4 Fill Time";
BA_ "SignalType" SG_ 430 TransClch4FlTm "UNM";
BA_ "VNSigAllNodes" SG_ 430 TransClch4FlAch 1;
BA_ "SignalLongName" SG_ 430 TransClch4FlAch "Transmission Clutch 4 Fill Achieved";
BA_ "SignalType" SG_ 430 TransClch4FlAch "BLN";
BA_ "VNSigAllNodes" SG_ 430 TransClch3FlTm 1;
BA_ "SignalLongName" SG_ 430 TransClch3FlTm "Transmission Clutch 3 Fill Time";
BA_ "SignalType" SG_ 430 TransClch3FlTm "UNM";
BA_ "VNSigAllNodes" SG_ 430 TransClch3FlAch 1;
BA_ "SignalLongName" SG_ 430 TransClch3FlAch "Transmission Clutch 3 Fill Achieved";
BA_ "SignalType" SG_ 430 TransClch3FlAch "BLN";
BA_ "VNSigAllNodes" SG_ 430 TransClch2FlTm 1;
BA_ "SignalLongName" SG_ 430 TransClch2FlTm "Transmission Clutch 2 Fill Time";
BA_ "SignalType" SG_ 430 TransClch2FlTm "UNM";
BA_ "VNSigAllNodes" SG_ 430 TransClch2FlAch 1;
BA_ "SignalLongName" SG_ 430 TransClch2FlAch "Transmission Clutch 2 Fill Achieved";
BA_ "SignalType" SG_ 430 TransClch2FlAch "BLN";
BA_ "VNSigAllNodes" SG_ 430 TransClch1FlTm 1;
BA_ "SignalLongName" SG_ 430 TransClch1FlTm "Transmission Clutch 1 Fill Time";
BA_ "SignalType" SG_ 430 TransClch1FlTm "UNM";
BA_ "VNSigAllNodes" SG_ 430 TransClch1FlAch 1;
BA_ "SignalLongName" SG_ 430 TransClch1FlAch "Transmission Clutch 1 Fill Achieved";
BA_ "SignalType" SG_ 430 TransClch1FlAch "BLN";
BA_ "GenMsgSendType" BO_ 429 0;
BA_ "GenMsgCycleTime" BO_ 429 25;
BA_ "MessageSubnet" BO_ 429 2;
BA_ "Prio" BO_ 429 0;
BA_ "VNSigAllNodes" SG_ 429 TCET_Cltch5 1;
BA_ "SignalLongName" SG_ 429 TCET_Cltch5 "Transmission Clutch Estimated Torque : Clutch 5";
BA_ "SignalType" SG_ 429 TCET_Cltch5 "UNM";
BA_ "PacketOrder" SG_ 429 TCET_Cltch5 5;
BA_ "VNSigAllNodes" SG_ 429 TCET_Cltch4 1;
BA_ "SignalLongName" SG_ 429 TCET_Cltch4 "Transmission Clutch Estimated Torque : Clutch 4";
BA_ "SignalType" SG_ 429 TCET_Cltch4 "UNM";
BA_ "PacketOrder" SG_ 429 TCET_Cltch4 4;
BA_ "VNSigAllNodes" SG_ 429 TCET_Cltch3 1;
BA_ "SignalLongName" SG_ 429 TCET_Cltch3 "Transmission Clutch Estimated Torque : Clutch 3";
BA_ "SignalType" SG_ 429 TCET_Cltch3 "UNM";
BA_ "PacketOrder" SG_ 429 TCET_Cltch3 3;
BA_ "VNSigAllNodes" SG_ 429 TCET_Cltch2 1;
BA_ "SignalLongName" SG_ 429 TCET_Cltch2 "Transmission Clutch Estimated Torque : Clutch 2";
BA_ "SignalType" SG_ 429 TCET_Cltch2 "UNM";
BA_ "PacketOrder" SG_ 429 TCET_Cltch2 2;
BA_ "VNSigAllNodes" SG_ 429 TCET_Cltch1 1;
BA_ "SignalLongName" SG_ 429 TCET_Cltch1 "Transmission Clutch Estimated Torque : Clutch 1";
BA_ "SignalType" SG_ 429 TCET_Cltch1 "UNM";
BA_ "PacketOrder" SG_ 429 TCET_Cltch1 1;
BA_ "VNSigAllNodes" SG_ 429 TrnsPTSysShtdwnRq 1;
BA_ "SignalLongName" SG_ 429 TrnsPTSysShtdwnRq "Transmission Powertrain System Shutdown Requested";
BA_ "SignalType" SG_ 429 TrnsPTSysShtdwnRq "BLN";
BA_ "VNSigAllNodes" SG_ 429 TransHydrlcDfltgAct 1;
BA_ "SignalLongName" SG_ 429 TransHydrlcDfltgAct "Transmission Hydraulic Defaulting Active";
BA_ "SignalType" SG_ 429 TransHydrlcDfltgAct "BLN";
BA_ "GenMsgSendType" BO_ 428 0;
BA_ "GenMsgCycleTime" BO_ 428 25;
BA_ "MessageSubnet" BO_ 428 2;
BA_ "Prio" BO_ 428 0;
BA_ "VNSigAllNodes" SG_ 428 TCMPR_Cltch5 1;
BA_ "SignalLongName" SG_ 428 TCMPR_Cltch5 "Transmission Clutch Minimum Pressure Required : Clutch 5";
BA_ "SignalType" SG_ 428 TCMPR_Cltch5 "UNM";
BA_ "PacketOrder" SG_ 428 TCMPR_Cltch5 5;
BA_ "VNSigAllNodes" SG_ 428 TCMPR_Cltch4 1;
BA_ "SignalLongName" SG_ 428 TCMPR_Cltch4 "Transmission Clutch Minimum Pressure Required : Clutch 4";
BA_ "SignalType" SG_ 428 TCMPR_Cltch4 "UNM";
BA_ "PacketOrder" SG_ 428 TCMPR_Cltch4 4;
BA_ "VNSigAllNodes" SG_ 428 TCMPR_Cltch3 1;
BA_ "SignalLongName" SG_ 428 TCMPR_Cltch3 "Transmission Clutch Minimum Pressure Required : Clutch 3";
BA_ "SignalType" SG_ 428 TCMPR_Cltch3 "UNM";
BA_ "PacketOrder" SG_ 428 TCMPR_Cltch3 3;
BA_ "VNSigAllNodes" SG_ 428 TCMPR_Cltch2 1;
BA_ "SignalLongName" SG_ 428 TCMPR_Cltch2 "Transmission Clutch Minimum Pressure Required : Clutch 2";
BA_ "SignalType" SG_ 428 TCMPR_Cltch2 "UNM";
BA_ "PacketOrder" SG_ 428 TCMPR_Cltch2 2;
BA_ "VNSigAllNodes" SG_ 428 TCMPR_Cltch1 1;
BA_ "SignalLongName" SG_ 428 TCMPR_Cltch1 "Transmission Clutch Minimum Pressure Required : Clutch 1";
BA_ "SignalType" SG_ 428 TCMPR_Cltch1 "UNM";
BA_ "PacketOrder" SG_ 428 TCMPR_Cltch1 1;
BA_ "VNSigAllNodes" SG_ 428 TransAuxPmpPresDetcd 1;
BA_ "SignalLongName" SG_ 428 TransAuxPmpPresDetcd "Transmission Auxiliary Pump Pressure Detected";
BA_ "SignalType" SG_ 428 TransAuxPmpPresDetcd "BLN";
BA_ "GenMsgSendType" BO_ 427 0;
BA_ "GenMsgCycleTime" BO_ 427 25;
BA_ "MessageSubnet" BO_ 427 2;
BA_ "Prio" BO_ 427 0;
BA_ "VNSigAllNodes" SG_ 427 TransActlRngStPVal 1;
BA_ "SignalLongName" SG_ 427 TransActlRngStPVal "Transmission Actual Range Status Protection Value";
BA_ "SignalType" SG_ 427 TransActlRngStPVal "UNM";
BA_ "VNSigAllNodes" SG_ 427 TransActlRngStARC 1;
BA_ "SignalLongName" SG_ 427 TransActlRngStARC "Transmission Actual Range Status Alive Rolling Count";
BA_ "SignalType" SG_ 427 TransActlRngStARC "UNM";
BA_ "VNSigAllNodes" SG_ 427 TARS_TransActRngV 1;
BA_ "SignalLongName" SG_ 427 TARS_TransActRngV "Transmission Actual Range Status : Transmission Actual Range Validity";
BA_ "SignalType" SG_ 427 TARS_TransActRngV "ENM";
BA_ "PacketOrder" SG_ 427 TARS_TransActRngV 3;
BA_ "VNSigAllNodes" SG_ 427 TARS_TransActRngM 1;
BA_ "SignalLongName" SG_ 427 TARS_TransActRngM "Transmission Actual Range Status : Transmission Actual Range Mask";
BA_ "SignalType" SG_ 427 TARS_TransActRngM "ENM";
BA_ "PacketOrder" SG_ 427 TARS_TransActRngM 2;
BA_ "VNSigAllNodes" SG_ 427 TARS_TransActRng 1;
BA_ "SignalLongName" SG_ 427 TARS_TransActRng "Transmission Actual Range Status : Transmission Actual Range";
BA_ "SignalType" SG_ 427 TARS_TransActRng "ENM";
BA_ "PacketOrder" SG_ 427 TARS_TransActRng 1;
BA_ "VNSigAllNodes" SG_ 427 TrnsEgdPrFlwInfPVal 1;
BA_ "SignalLongName" SG_ 427 TrnsEgdPrFlwInfPVal "Transmission Engaged Powerflow Information Protection Value";
BA_ "SignalType" SG_ 427 TrnsEgdPrFlwInfPVal "UNM";
BA_ "VNSigAllNodes" SG_ 427 TrnsEgdPrFlwInfARC 1;
BA_ "SignalLongName" SG_ 427 TrnsEgdPrFlwInfARC "Transmission Engaged Powerflow Information Alive Rolling Count";
BA_ "SignalType" SG_ 427 TrnsEgdPrFlwInfARC "UNM";
BA_ "VNSigAllNodes" SG_ 427 TEPI_TrnsEngdPrFlwStV 1;
BA_ "SignalLongName" SG_ 427 TEPI_TrnsEngdPrFlwStV "Transmission Engaged Powerflow Information : Transmission Engaged Powerflow State Validity";
BA_ "SignalType" SG_ 427 TEPI_TrnsEngdPrFlwStV "ENM";
BA_ "PacketOrder" SG_ 427 TEPI_TrnsEngdPrFlwStV 2;
BA_ "VNSigAllNodes" SG_ 427 TEPI_TrnsEngdPrFlwSt 1;
BA_ "SignalLongName" SG_ 427 TEPI_TrnsEngdPrFlwSt "Transmission Engaged Powerflow Information : Transmission Engaged Powerflow State";
BA_ "SignalType" SG_ 427 TEPI_TrnsEngdPrFlwSt "ENM";
BA_ "PacketOrder" SG_ 427 TEPI_TrnsEngdPrFlwSt 1;
BA_ "VNSigAllNodes" SG_ 427 TransCltchCntlARC 1;
BA_ "SignalLongName" SG_ 427 TransCltchCntlARC "Transmission Clutch Control Alive Rolling Count";
BA_ "SignalType" SG_ 427 TransCltchCntlARC "UNM";
BA_ "VNSigAllNodes" SG_ 427 TransCltch5FillCmd 1;
BA_ "SignalLongName" SG_ 427 TransCltch5FillCmd "Transmission Clutch 5 Fill Commanded";
BA_ "SignalType" SG_ 427 TransCltch5FillCmd "ENM";
BA_ "VNSigAllNodes" SG_ 427 TransCltch5CntlRqPVal 1;
BA_ "SignalLongName" SG_ 427 TransCltch5CntlRqPVal "Transmission Clutch 5 Control Requested Protection Value";
BA_ "SignalType" SG_ 427 TransCltch5CntlRqPVal "UNM";
BA_ "VNSigAllNodes" SG_ 427 TransCltch5CntlRq 1;
BA_ "SignalLongName" SG_ 427 TransCltch5CntlRq "Transmission Clutch 5 Control Requested";
BA_ "SignalType" SG_ 427 TransCltch5CntlRq "ENM";
BA_ "VNSigAllNodes" SG_ 427 TransCltch4FillCmd 1;
BA_ "SignalLongName" SG_ 427 TransCltch4FillCmd "Transmission Clutch 4 Fill Commanded";
BA_ "SignalType" SG_ 427 TransCltch4FillCmd "ENM";
BA_ "VNSigAllNodes" SG_ 427 TransCltch4CntlRqPVal 1;
BA_ "SignalLongName" SG_ 427 TransCltch4CntlRqPVal "Transmission Clutch 4 Control Requested Protection Value";
BA_ "SignalType" SG_ 427 TransCltch4CntlRqPVal "UNM";
BA_ "VNSigAllNodes" SG_ 427 TransCltch4CntlRq 1;
BA_ "SignalLongName" SG_ 427 TransCltch4CntlRq "Transmission Clutch 4 Control Requested";
BA_ "SignalType" SG_ 427 TransCltch4CntlRq "ENM";
BA_ "VNSigAllNodes" SG_ 427 TransCltch3FillCmd 1;
BA_ "SignalLongName" SG_ 427 TransCltch3FillCmd "Transmission Clutch 3 Fill Commanded";
BA_ "SignalType" SG_ 427 TransCltch3FillCmd "ENM";
BA_ "VNSigAllNodes" SG_ 427 TransCltch3CntlRqPVal 1;
BA_ "SignalLongName" SG_ 427 TransCltch3CntlRqPVal "Transmission Clutch 3 Control Requested Protection Value";
BA_ "SignalType" SG_ 427 TransCltch3CntlRqPVal "UNM";
BA_ "VNSigAllNodes" SG_ 427 TransCltch3CntlRq 1;
BA_ "SignalLongName" SG_ 427 TransCltch3CntlRq "Transmission Clutch 3 Control Requested";
BA_ "SignalType" SG_ 427 TransCltch3CntlRq "ENM";
BA_ "VNSigAllNodes" SG_ 427 TransCltch2FillCmd 1;
BA_ "SignalLongName" SG_ 427 TransCltch2FillCmd "Transmission Clutch 2 Fill Commanded";
BA_ "SignalType" SG_ 427 TransCltch2FillCmd "ENM";
BA_ "VNSigAllNodes" SG_ 427 TransCltch2CntlRqPVal 1;
BA_ "SignalLongName" SG_ 427 TransCltch2CntlRqPVal "Transmission Clutch 2 Control Requested Protection Value";
BA_ "SignalType" SG_ 427 TransCltch2CntlRqPVal "UNM";
BA_ "VNSigAllNodes" SG_ 427 TransCltch2CntlRq 1;
BA_ "SignalLongName" SG_ 427 TransCltch2CntlRq "Transmission Clutch 2 Control Requested";
BA_ "SignalType" SG_ 427 TransCltch2CntlRq "ENM";
BA_ "VNSigAllNodes" SG_ 427 TransCltch1FillCmd 1;
BA_ "SignalLongName" SG_ 427 TransCltch1FillCmd "Transmission Clutch 1 Fill Commanded";
BA_ "SignalType" SG_ 427 TransCltch1FillCmd "ENM";
BA_ "VNSigAllNodes" SG_ 427 TransCltch1CntlRqPVal 1;
BA_ "SignalLongName" SG_ 427 TransCltch1CntlRqPVal "Transmission Clutch 1 Control Requested Protection Value";
BA_ "SignalType" SG_ 427 TransCltch1CntlRqPVal "UNM";
BA_ "VNSigAllNodes" SG_ 427 TransCltch1CntlRq 1;
BA_ "SignalLongName" SG_ 427 TransCltch1CntlRq "Transmission Clutch 1 Control Requested";
BA_ "SignalType" SG_ 427 TransCltch1CntlRq "ENM";
BA_ "GenMsgSendType" BO_ 399 0;
BA_ "GenMsgCycleTime" BO_ 399 25;
BA_ "MessageSubnet" BO_ 399 2;
BA_ "Prio" BO_ 399 0;
BA_ "VNSigAllNodes" SG_ 399 ElcTrnsRngSelPrkSysStatPVal 1;
BA_ "SignalLongName" SG_ 399 ElcTrnsRngSelPrkSysStatPVal "Electronic Transmission Range Select Park System Status Protection Value";
BA_ "SignalType" SG_ 399 ElcTrnsRngSelPrkSysStatPVal "UNM";
BA_ "VNSigAllNodes" SG_ 399 ElcTrnsRngSelPrkSysStatARC 1;
BA_ "SignalLongName" SG_ 399 ElcTrnsRngSelPrkSysStatARC "Electronic Transmission Range Select Park System Status Alive Rolling Count";
BA_ "SignalType" SG_ 399 ElcTrnsRngSelPrkSysStatARC "UNM";
BA_ "VNSigAllNodes" SG_ 399 ElcTrnsRngSelPrkSysStat 1;
BA_ "SignalLongName" SG_ 399 ElcTrnsRngSelPrkSysStat "Electronic Transmission Range Select Park System Status";
BA_ "SignalType" SG_ 399 ElcTrnsRngSelPrkSysStat "ENM";
BA_ "VNSigAllNodes" SG_ 399 TrnsPrkSysDiagCrtFltPVal 1;
BA_ "SignalLongName" SG_ 399 TrnsPrkSysDiagCrtFltPVal "Transmission Park System Diagnostic Critical Fault Protection Value";
BA_ "SignalType" SG_ 399 TrnsPrkSysDiagCrtFltPVal "UNM";
BA_ "VNSigAllNodes" SG_ 399 TrnsPrkSysDiagCrtFltARC 1;
BA_ "SignalLongName" SG_ 399 TrnsPrkSysDiagCrtFltARC "Transmission Park System Diagnostic Critical Fault Alive Rolling Count";
BA_ "SignalType" SG_ 399 TrnsPrkSysDiagCrtFltARC "UNM";
BA_ "VNSigAllNodes" SG_ 399 TPSDCF_TrnsPrkSysOOPrkDiaCrtFlt 1;
BA_ "SignalLongName" SG_ 399 TPSDCF_TrnsPrkSysOOPrkDiaCrtFlt "Transmission Park System Diagnostic Critical Fault : Transmission Park System Out Of Park Diagnostic Critical Fault";
BA_ "SignalType" SG_ 399 TPSDCF_TrnsPrkSysOOPrkDiaCrtFlt "BLN";
BA_ "PacketOrder" SG_ 399 TPSDCF_TrnsPrkSysOOPrkDiaCrtFlt 2;
BA_ "VNSigAllNodes" SG_ 399 TPSDCF_TrnsPrkSysPrkDiaCrtFlt 1;
BA_ "SignalLongName" SG_ 399 TPSDCF_TrnsPrkSysPrkDiaCrtFlt "Transmission Park System Diagnostic Critical Fault : Transmission Park System Park Diagnostic Critical Fault";
BA_ "SignalType" SG_ 399 TPSDCF_TrnsPrkSysPrkDiaCrtFlt "BLN";
BA_ "PacketOrder" SG_ 399 TPSDCF_TrnsPrkSysPrkDiaCrtFlt 1;
BA_ "VNSigAllNodes" SG_ 399 TrnsPrkSysDiagLmtdFltPVal 1;
BA_ "SignalLongName" SG_ 399 TrnsPrkSysDiagLmtdFltPVal "Transmission Park System Diagnostic Limited Fault Protection Value";
BA_ "SignalType" SG_ 399 TrnsPrkSysDiagLmtdFltPVal "UNM";
BA_ "VNSigAllNodes" SG_ 399 TrnsPrkSysDiagLmtdFltARC 1;
BA_ "SignalLongName" SG_ 399 TrnsPrkSysDiagLmtdFltARC "Transmission Park System Diagnostic Limited Fault Alive Rolling Count";
BA_ "SignalType" SG_ 399 TrnsPrkSysDiagLmtdFltARC "UNM";
BA_ "VNSigAllNodes" SG_ 399 TPSDLF_TrnsPrkSysOOPrkDiaLmtdFlt 1;
BA_ "SignalLongName" SG_ 399 TPSDLF_TrnsPrkSysOOPrkDiaLmtdFlt "Transmission Park System Diagnostic Limited Fault : Transmission Park System Out Of Park Diagnostic Limited Fault";
BA_ "SignalType" SG_ 399 TPSDLF_TrnsPrkSysOOPrkDiaLmtdFlt "BLN";
BA_ "PacketOrder" SG_ 399 TPSDLF_TrnsPrkSysOOPrkDiaLmtdFlt 2;
BA_ "VNSigAllNodes" SG_ 399 TPSDLF_TrnsPrkSysPrkDiaLmtdFlt 1;
BA_ "SignalLongName" SG_ 399 TPSDLF_TrnsPrkSysPrkDiaLmtdFlt "Transmission Park System Diagnostic Limited Fault : Transmission Park System Park Diagnostic Limited Fault";
BA_ "SignalType" SG_ 399 TPSDLF_TrnsPrkSysPrkDiaLmtdFlt "BLN";
BA_ "PacketOrder" SG_ 399 TPSDLF_TrnsPrkSysPrkDiaLmtdFlt 1;
BA_ "GenMsgSendType" BO_ 1236 0;
BA_ "GenMsgCycleTime" BO_ 1236 1000;
BA_ "MessageSubnet" BO_ 1236 2;
BA_ "Prio" BO_ 1236 0;
BA_ "VNSigAllNodes" SG_ 1236 CGMCII_DataVal 1;
BA_ "SignalLongName" SG_ 1236 CGMCII_DataVal "Central Gateway Module Calibration Identification Information : Data Value";
BA_ "PacketOrder" SG_ 1236 CGMCII_DataVal 3;
BA_ "SignalType" SG_ 1236 CGMCII_DataVal "UNM";
BA_ "VNSigAllNodes" SG_ 1236 CGMCII_DataIndx 1;
BA_ "SignalLongName" SG_ 1236 CGMCII_DataIndx "Central Gateway Module Calibration Identification Information : Data Index";
BA_ "PacketOrder" SG_ 1236 CGMCII_DataIndx 2;
BA_ "SignalType" SG_ 1236 CGMCII_DataIndx "ENM";
BA_ "VNSigAllNodes" SG_ 1236 CGMCII_DataStat 1;
BA_ "SignalLongName" SG_ 1236 CGMCII_DataStat "Central Gateway Module Calibration Identification Information : Data Status";
BA_ "PacketOrder" SG_ 1236 CGMCII_DataStat 1;
BA_ "SignalType" SG_ 1236 CGMCII_DataStat "ENM";
BA_ "GenMsgSendType" BO_ 975 0;
BA_ "GenMsgCycleTime" BO_ 975 100;
BA_ "MessageSubnet" BO_ 975 2;
BA_ "Prio" BO_ 975 0;
BA_ "VNSigAllNodes" SG_ 975 CGMDS2_DTCStat 1;
BA_ "SignalLongName" SG_ 975 CGMDS2_DTCStat "Central Gateway Module Diagnostic Status 2 : Diagnostic Trouble Code Status";
BA_ "PacketOrder" SG_ 975 CGMDS2_DTCStat 2;
BA_ "SignalType" SG_ 975 CGMDS2_DTCStat "ENM";
BA_ "GenSigStartValue" SG_ 975 CGMDS2_DTCStat 2;
BA_ "VNSigAllNodes" SG_ 975 CGMDS2_DTCIndx 1;
BA_ "SignalLongName" SG_ 975 CGMDS2_DTCIndx "Central Gateway Module Diagnostic Status 2 : Diagnostic Trouble Code Index";
BA_ "PacketOrder" SG_ 975 CGMDS2_DTCIndx 1;
BA_ "SignalType" SG_ 975 CGMDS2_DTCIndx "UNM";
BA_ "VNSigAllNodes" SG_ 975 CGMDS1_DTCStat 1;
BA_ "SignalLongName" SG_ 975 CGMDS1_DTCStat "Central Gateway Module Diagnostic Status 1 : Diagnostic Trouble Code Status";
BA_ "PacketOrder" SG_ 975 CGMDS1_DTCStat 2;
BA_ "SignalType" SG_ 975 CGMDS1_DTCStat "ENM";
BA_ "GenSigStartValue" SG_ 975 CGMDS1_DTCStat 2;
BA_ "VNSigAllNodes" SG_ 975 CGMDS1_DTCIndx 1;
BA_ "SignalLongName" SG_ 975 CGMDS1_DTCIndx "Central Gateway Module Diagnostic Status 1 : Diagnostic Trouble Code Index";
BA_ "PacketOrder" SG_ 975 CGMDS1_DTCIndx 1;
BA_ "SignalType" SG_ 975 CGMDS1_DTCIndx "UNM";
BA_ "GenMsgSendType" BO_ 504 0;
BA_ "GenMsgCycleTime" BO_ 504 25;
BA_ "MessageSubnet" BO_ 504 2;
BA_ "Prio" BO_ 504 0;
BA_ "VNSigAllNodes" SG_ 504 EngCylDsrdFirngFractn 1;
BA_ "SignalLongName" SG_ 504 EngCylDsrdFirngFractn "Engine Cylinder Desired Firing Fraction";
BA_ "SignalType" SG_ 504 EngCylDsrdFirngFractn "UNM";
BA_ "VNSigAllNodes" SG_ 504 EngCylCalcFirngFractn 1;
BA_ "SignalLongName" SG_ 504 EngCylCalcFirngFractn "Engine Cylinder Calculated Firing Fraction";
BA_ "SignalType" SG_ 504 EngCylCalcFirngFractn "UNM";
BA_ "GenMsgSendType" BO_ 730 0;
BA_ "GenMsgCycleTime" BO_ 730 50;
BA_ "MessageSubnet" BO_ 730 2;
BA_ "Prio" BO_ 730 0;
BA_ "VNSigAllNodes" SG_ 730 PlatAnlgMdSwPVal 1;
BA_ "SignalLongName" SG_ 730 PlatAnlgMdSwPVal "Platform Analog Mode Switch Protection Value";
BA_ "SignalType" SG_ 730 PlatAnlgMdSwPVal "UNM";
BA_ "VNSigAllNodes" SG_ 730 PlatAnlgMdSwARC 1;
BA_ "SignalLongName" SG_ 730 PlatAnlgMdSwARC "Platform Analog Mode Switch Alive Rolling Count";
BA_ "SignalType" SG_ 730 PlatAnlgMdSwARC "UNM";
BA_ "VNSigAllNodes" SG_ 730 PAMS_DrvMdSwStck 1;
BA_ "SignalLongName" SG_ 730 PAMS_DrvMdSwStck "Platform Analog Mode Switch : Driver Mode Switch Stuck";
BA_ "SignalType" SG_ 730 PAMS_DrvMdSwStck "BLN";
BA_ "PacketOrder" SG_ 730 PAMS_DrvMdSwStck 6;
BA_ "VNSigAllNodes" SG_ 730 PAMS_Sw4Stck 1;
BA_ "SignalLongName" SG_ 730 PAMS_Sw4Stck "Platform Analog Mode Switch : Switch 4 Stuck";
BA_ "SignalType" SG_ 730 PAMS_Sw4Stck "BLN";
BA_ "PacketOrder" SG_ 730 PAMS_Sw4Stck 5;
BA_ "VNSigAllNodes" SG_ 730 PAMS_Sw3Stck 1;
BA_ "SignalLongName" SG_ 730 PAMS_Sw3Stck "Platform Analog Mode Switch : Switch 3 Stuck";
BA_ "SignalType" SG_ 730 PAMS_Sw3Stck "BLN";
BA_ "PacketOrder" SG_ 730 PAMS_Sw3Stck 4;
BA_ "VNSigAllNodes" SG_ 730 PAMS_Sw2Stck 1;
BA_ "SignalLongName" SG_ 730 PAMS_Sw2Stck "Platform Analog Mode Switch : Switch 2 Stuck";
BA_ "SignalType" SG_ 730 PAMS_Sw2Stck "BLN";
BA_ "PacketOrder" SG_ 730 PAMS_Sw2Stck 3;
BA_ "VNSigAllNodes" SG_ 730 PAMS_Sw1Stck 1;
BA_ "SignalLongName" SG_ 730 PAMS_Sw1Stck "Platform Analog Mode Switch : Switch 1 Stuck";
BA_ "SignalType" SG_ 730 PAMS_Sw1Stck "BLN";
BA_ "PacketOrder" SG_ 730 PAMS_Sw1Stck 2;
BA_ "VNSigAllNodes" SG_ 730 PAMS_SwStat 1;
BA_ "SignalLongName" SG_ 730 PAMS_SwStat "Platform Analog Mode Switch : Switch Status";
BA_ "SignalType" SG_ 730 PAMS_SwStat "ENM";
BA_ "PacketOrder" SG_ 730 PAMS_SwStat 1;
BA_ "GenMsgSendType" BO_ 1278 0;
BA_ "GenMsgCycleTime" BO_ 1278 1000;
BA_ "MessageSubnet" BO_ 1278 2;
BA_ "Prio" BO_ 1278 0;
BA_ "VNSigAllNodes" SG_ 1278 EHCCT_EHtrCrOutClntTmp 1;
BA_ "SignalLongName" SG_ 1278 EHCCT_EHtrCrOutClntTmp "Estimated Heater Core Coolant Temperature : Estimated Heater Core Out Coolant Temperature";
BA_ "SignalType" SG_ 1278 EHCCT_EHtrCrOutClntTmp "UNM";
BA_ "GenMsgSendType" BO_ 1279 0;
BA_ "GenMsgCycleTime" BO_ 1279 1000;
BA_ "MessageSubnet" BO_ 1279 2;
BA_ "Prio" BO_ 1279 0;
BA_ "GenMsgSendType" BO_ 561 0;
BA_ "GenMsgCycleTime" BO_ 561 100;
BA_ "MessageSubnet" BO_ 561 2;
BA_ "Prio" BO_ 561 0;
BA_ "GenMsgSendType" BO_ 573 0;
BA_ "GenMsgCycleTime" BO_ 573 2000;
BA_ "MessageSubnet" BO_ 573 2;
BA_ "Prio" BO_ 573 0;
BA_ "GenMsgSendType" BO_ 1276 0;
BA_ "GenMsgCycleTime" BO_ 1276 1000;
BA_ "MessageSubnet" BO_ 1276 2;
BA_ "Prio" BO_ 1276 0;
BA_ "GenMsgSendType" BO_ 1277 0;
BA_ "GenMsgCycleTime" BO_ 1277 1000;
BA_ "MessageSubnet" BO_ 1277 2;
BA_ "Prio" BO_ 1277 0;
BA_ "GenMsgSendType" BO_ 1195 0;
BA_ "GenMsgCycleTime" BO_ 1195 1000;
BA_ "MessageSubnet" BO_ 1195 2;
BA_ "Prio" BO_ 1195 0;
BA_ "GenMsgSendType" BO_ 1037 0;
BA_ "GenMsgCycleTime" BO_ 1037 5000;
BA_ "GenMsgDelayTime" BO_ 1037 100;
BA_ "MessageSubnet" BO_ 1037 2;
BA_ "Prio" BO_ 1037 0;
BA_ "GenMsgSendType" BO_ 292 0;
BA_ "GenMsgCycleTime" BO_ 292 100;
BA_ "MessageSubnet" BO_ 292 2;
BA_ "Prio" BO_ 292 0;
BA_ "DiagRequest" BO_ 40 1;
BA_ "MessageSubnet" BO_ 40 2;
BA_ "Prio" BO_ 40 0;
BA_ "DiagResponse" BO_ 808 1;
BA_ "MessageSubnet" BO_ 808 2;
BA_ "Prio" BO_ 808 0;
BA_ "GenMsgSendType" BO_ 569 0;
BA_ "GenMsgCycleTime" BO_ 569 250;
BA_ "MessageSubnet" BO_ 569 2;
BA_ "Prio" BO_ 569 0;
BA_ "GenMsgSendType" BO_ 613 0;
BA_ "GenMsgCycleTime" BO_ 613 100;
BA_ "MessageSubnet" BO_ 613 2;
BA_ "Prio" BO_ 613 0;
BA_ "GenMsgSendType" BO_ 612 0;
BA_ "GenMsgCycleTime" BO_ 612 100;
BA_ "MessageSubnet" BO_ 612 2;
BA_ "Prio" BO_ 612 0;
BA_ "GenMsgSendType" BO_ 611 0;
BA_ "GenMsgCycleTime" BO_ 611 100;
BA_ "MessageSubnet" BO_ 611 2;
BA_ "Prio" BO_ 611 0;
BA_ "GenMsgSendType" BO_ 610 0;
BA_ "GenMsgCycleTime" BO_ 610 100;
BA_ "MessageSubnet" BO_ 610 2;
BA_ "Prio" BO_ 610 0;
BA_ "GenMsgSendType" BO_ 609 0;
BA_ "GenMsgCycleTime" BO_ 609 100;
BA_ "MessageSubnet" BO_ 609 2;
BA_ "Prio" BO_ 609 0;
BA_ "GenMsgSendType" BO_ 608 0;
BA_ "GenMsgCycleTime" BO_ 608 100;
BA_ "MessageSubnet" BO_ 608 2;
BA_ "Prio" BO_ 608 0;
BA_ "MessageSubnet" BO_ 839 2;
BA_ "Prio" BO_ 839 0;
BA_ "AppGenMsgCycleTime" BO_ 839 100;
BA_ "MessageSubnet" BO_ 838 2;
BA_ "Prio" BO_ 838 0;
BA_ "AppGenMsgCycleTime" BO_ 838 100;
BA_ "MessageSubnet" BO_ 837 2;
BA_ "Prio" BO_ 837 0;
BA_ "AppGenMsgCycleTime" BO_ 837 100;
BA_ "GenMsgSendType" BO_ 836 0;
BA_ "GenMsgCycleTime" BO_ 836 20;
BA_ "MessageSubnet" BO_ 836 2;
BA_ "Prio" BO_ 836 0;
BA_ "GenMsgSendType" BO_ 835 0;
BA_ "GenMsgCycleTime" BO_ 835 100;
BA_ "MessageSubnet" BO_ 835 2;
BA_ "Prio" BO_ 835 0;
BA_ "GenMsgSendType" BO_ 834 0;
BA_ "GenMsgCycleTime" BO_ 834 10;
BA_ "MessageSubnet" BO_ 834 2;
BA_ "Prio" BO_ 834 0;
BA_ "GenMsgSendType" BO_ 833 0;
BA_ "GenMsgCycleTime" BO_ 833 10;
BA_ "MessageSubnet" BO_ 833 2;
BA_ "Prio" BO_ 833 0;
BA_ "GenMsgSendType" BO_ 832 0;
BA_ "GenMsgCycleTime" BO_ 832 10;
BA_ "MessageSubnet" BO_ 832 2;
BA_ "Prio" BO_ 832 0;
BA_ "GenMsgSendType" BO_ 336 0;
BA_ "GenMsgCycleTime" BO_ 336 100;
BA_ "MessageSubnet" BO_ 336 2;
BA_ "Prio" BO_ 336 0;
BA_ "GenMsgSendType" BO_ 354 0;
BA_ "GenMsgCycleTime" BO_ 354 100;
BA_ "MessageSubnet" BO_ 354 2;
BA_ "Prio" BO_ 354 0;
BA_ "DiagRequest" BO_ 114 1;
BA_ "MessageSubnet" BO_ 114 2;
BA_ "Prio" BO_ 114 0;
BA_ "DiagRequest" BO_ 93 1;
BA_ "MessageSubnet" BO_ 93 2;
BA_ "Prio" BO_ 93 0;
BA_ "DiagResponse" BO_ 861 1;
BA_ "MessageSubnet" BO_ 861 2;
BA_ "Prio" BO_ 861 0;
BA_ "GenMsgSendType" BO_ 458 0;
BA_ "GenMsgCycleTime" BO_ 458 25;
BA_ "MessageSubnet" BO_ 458 2;
BA_ "Prio" BO_ 458 0;
BA_ "GenMsgSendType" BO_ 1191 0;
BA_ "GenMsgCycleTime" BO_ 1191 250;
BA_ "MessageSubnet" BO_ 1191 2;
BA_ "Prio" BO_ 1191 0;
BA_ "GenMsgSendType" BO_ 356 0;
BA_ "GenMsgCycleTime" BO_ 356 10;
BA_ "MessageSubnet" BO_ 356 2;
BA_ "Prio" BO_ 356 0;
BA_ "GenMsgSendType" BO_ 340 0;
BA_ "GenMsgCycleTime" BO_ 340 10;
BA_ "MessageSubnet" BO_ 340 2;
BA_ "Prio" BO_ 340 0;
BA_ "GenMsgSendType" BO_ 338 0;
BA_ "GenMsgCycleTime" BO_ 338 10;
BA_ "MessageSubnet" BO_ 338 2;
BA_ "Prio" BO_ 338 0;
BA_ "GenMsgSendType" BO_ 503 0;
BA_ "GenMsgCycleTime" BO_ 503 25;
BA_ "MessageSubnet" BO_ 503 2;
BA_ "Prio" BO_ 503 0;
BA_ "GenMsgSendType" BO_ 872 0;
BA_ "GenMsgCycleTime" BO_ 872 25;
BA_ "MessageSubnet" BO_ 872 2;
BA_ "Prio" BO_ 872 0;
BA_ "GenMsgSendType" BO_ 353 0;
BA_ "GenMsgCycleTime" BO_ 353 100;
BA_ "MessageSubnet" BO_ 353 2;
BA_ "Prio" BO_ 353 0;
BA_ "GenMsgSendType" BO_ 329 0;
BA_ "GenMsgCycleTime" BO_ 329 100;
BA_ "MessageSubnet" BO_ 329 2;
BA_ "Prio" BO_ 329 0;
BA_ "GenMsgSendType" BO_ 327 0;
BA_ "GenMsgCycleTime" BO_ 327 500;
BA_ "MessageSubnet" BO_ 327 2;
BA_ "Prio" BO_ 327 0;
BA_ "GenMsgSendType" BO_ 325 0;
BA_ "GenMsgCycleTime" BO_ 325 500;
BA_ "MessageSubnet" BO_ 325 2;
BA_ "Prio" BO_ 325 0;
BA_ "GenMsgSendType" BO_ 331 0;
BA_ "GenMsgCycleTime" BO_ 331 1000;
BA_ "MessageSubnet" BO_ 331 2;
BA_ "Prio" BO_ 331 0;
BA_ "GenMsgSendType" BO_ 1275 0;
BA_ "GenMsgCycleTime" BO_ 1275 500;
BA_ "MessageSubnet" BO_ 1275 2;
BA_ "Prio" BO_ 1275 0;
BA_ "GenMsgSendType" BO_ 1273 0;
BA_ "GenMsgCycleTime" BO_ 1273 500;
BA_ "MessageSubnet" BO_ 1273 2;
BA_ "Prio" BO_ 1273 0;
BA_ "GenMsgSendType" BO_ 1271 0;
BA_ "GenMsgCycleTime" BO_ 1271 5000;
BA_ "MessageSubnet" BO_ 1271 2;
BA_ "Prio" BO_ 1271 0;
BA_ "GenMsgSendType" BO_ 558 0;
BA_ "GenMsgCycleTime" BO_ 558 100;
BA_ "MessageSubnet" BO_ 558 2;
BA_ "Prio" BO_ 558 0;
BA_ "GenMsgSendType" BO_ 208 0;
BA_ "GenMsgCycleTime" BO_ 208 100;
BA_ "MessageSubnet" BO_ 208 2;
BA_ "Prio" BO_ 208 0;
BA_ "GenMsgSendType" BO_ 663 0;
BA_ "GenMsgCycleTime" BO_ 663 100;
BA_ "MessageSubnet" BO_ 663 2;
BA_ "Prio" BO_ 663 0;
BA_ "GenMsgSendType" BO_ 1263 0;
BA_ "GenMsgCycleTime" BO_ 1263 1000;
BA_ "MessageSubnet" BO_ 1263 2;
BA_ "Prio" BO_ 1263 0;
BA_ "GenMsgSendType" BO_ 1261 0;
BA_ "GenMsgCycleTime" BO_ 1261 1000;
BA_ "MessageSubnet" BO_ 1261 2;
BA_ "Prio" BO_ 1261 0;
BA_ "GenMsgSendType" BO_ 1259 0;
BA_ "GenMsgCycleTime" BO_ 1259 500;
BA_ "MessageSubnet" BO_ 1259 2;
BA_ "Prio" BO_ 1259 0;
BA_ "GenMsgSendType" BO_ 1034 0;
BA_ "GenMsgCycleTime" BO_ 1034 100;
BA_ "MessageSubnet" BO_ 1034 2;
BA_ "Prio" BO_ 1034 0;
BA_ "GenMsgSendType" BO_ 1033 0;
BA_ "GenMsgCycleTime" BO_ 1033 100;
BA_ "MessageSubnet" BO_ 1033 2;
BA_ "Prio" BO_ 1033 0;
BA_ "GenMsgSendType" BO_ 1013 0;
BA_ "GenMsgCycleTime" BO_ 1013 250;
BA_ "MessageSubnet" BO_ 1013 2;
BA_ "Prio" BO_ 1013 0;
BA_ "GenMsgSendType" BO_ 425 0;
BA_ "GenMsgCycleTime" BO_ 425 25;
BA_ "MessageSubnet" BO_ 425 2;
BA_ "Prio" BO_ 425 0;
BA_ "GenMsgSendType" BO_ 424 0;
BA_ "GenMsgCycleTime" BO_ 424 25;
BA_ "MessageSubnet" BO_ 424 2;
BA_ "Prio" BO_ 424 0;
BA_ "GenMsgSendType" BO_ 324 0;
BA_ "GenMsgCycleTime" BO_ 324 250;
BA_ "MessageSubnet" BO_ 324 2;
BA_ "Prio" BO_ 324 0;
BA_ "GenMsgSendType" BO_ 844 0;
BA_ "GenMsgCycleTime" BO_ 844 50;
BA_ "MessageSubnet" BO_ 844 2;
BA_ "Prio" BO_ 844 0;
BA_ "GenMsgSendType" BO_ 308 0;
BA_ "GenMsgCycleTime" BO_ 308 1000;
BA_ "MessageSubnet" BO_ 308 2;
BA_ "Prio" BO_ 308 0;
BA_ "GenMsgSendType" BO_ 806 0;
BA_ "GenMsgCycleTime" BO_ 806 500;
BA_ "MessageSubnet" BO_ 806 2;
BA_ "Prio" BO_ 806 0;
BA_ "GenMsgSendType" BO_ 426 0;
BA_ "GenMsgCycleTime" BO_ 426 25;
BA_ "MessageSubnet" BO_ 426 2;
BA_ "Prio" BO_ 426 0;
BA_ "GenMsgSendType" BO_ 1231 0;
BA_ "GenMsgCycleTime" BO_ 1231 1000;
BA_ "MessageSubnet" BO_ 1231 2;
BA_ "Prio" BO_ 1231 0;
BA_ "GenMsgSendType" BO_ 955 0;
BA_ "GenMsgCycleTime" BO_ 955 100;
BA_ "MessageSubnet" BO_ 955 2;
BA_ "Prio" BO_ 955 0;
BA_ "GenMsgSendType" BO_ 423 0;
BA_ "GenMsgCycleTime" BO_ 423 25;
BA_ "MessageSubnet" BO_ 423 2;
BA_ "Prio" BO_ 423 0;
BA_ "DiagResponse" BO_ 2034 1;
BA_ "MessageSubnet" BO_ 2034 2;
BA_ "Prio" BO_ 2034 0;
BA_ "DiagRequest" BO_ 2032 1;
BA_ "MessageSubnet" BO_ 2032 2;
BA_ "Prio" BO_ 2032 0;
BA_ "GenMsgSendType" BO_ 563 0;
BA_ "GenMsgCycleTime" BO_ 563 2000;
BA_ "MessageSubnet" BO_ 563 2;
BA_ "Prio" BO_ 563 0;
BA_ "VNECUAllNodes" BU_ EOCM2B_IMX6_HS 4;
BA_ "VNECUSLHSSharedDiagnostic" BU_ EOCM2B_IMX6_HS 4;
BA_ "VNECUSLHS_VNReq" BU_ EOCM2B_IMX6_HS 4;
BA_ "VNECUAllNodes" BU_ EOCM2A_IMX6_HS 4;
BA_ "VNECUSLHSSharedDiagnostic" BU_ EOCM2A_IMX6_HS 4;
BA_ "VNECUSLHS_VNReq" BU_ EOCM2A_IMX6_HS 4;
BA_ "VNECUAllNodes" BU_ EOCM2B_K2_HS 4;
BA_ "VNECUSLHSSharedDiagnostic" BU_ EOCM2B_K2_HS 4;
BA_ "VNECUSLHS_VNReq" BU_ EOCM2B_K2_HS 4;
BA_ "VNECUAllNodes" BU_ EOCM2A_K2_HS 4;
BA_ "VNECUSLHSSharedDiagnostic" BU_ EOCM2A_K2_HS 4;
BA_ "VNECUSLHS_VNReq" BU_ EOCM2A_K2_HS 4;
BA_ "SourceId" BU_ TTPM_HS 35;
BA_ "ECU_Id" BU_ TTPM_HS 23;
BA_ "VNECUAllNodes" BU_ TTPM_HS 4;
BA_ "VNECUSLHSSharedDiagnostic" BU_ TTPM_HS 4;
BA_ "VNECUSLHS_VNReq" BU_ TTPM_HS 4;
BA_ "SourceId" BU_ AMM_HS 110;
BA_ "ECU_Id" BU_ AMM_HS 18;
BA_ "VNECUAllNodes" BU_ AMM_HS 4;
BA_ "VNECUSLHSSharedDiagnostic" BU_ AMM_HS 4;
BA_ "VNECUSLHS_VNReq" BU_ AMM_HS 4;
BA_ "SourceId" BU_ EBOOST_OBD_HS 43;
BA_ "ECU_Id" BU_ EBOOST_OBD_HS 230;
BA_ "VNECUAllNodes" BU_ EBOOST_OBD_HS 4;
BA_ "VNECUSLHSSharedDiagnostic" BU_ EBOOST_OBD_HS 4;
BA_ "VNECUSLHS_VNReq" BU_ EBOOST_OBD_HS 4;
BA_ "SourceId" BU_ CGM_HS 69;
BA_ "ECU_Id" BU_ CGM_HS 31;
BA_ "VNECUAllNodes" BU_ CGM_HS 4;
BA_ "VNECUSLHSSharedDiagnostic" BU_ CGM_HS 4;
BA_ "VNECUSLHS_VNReq" BU_ CGM_HS 4;
BA_ "SourceId" BU_ BSM_HS 203;
BA_ "ECU_Id" BU_ BSM_HS 228;
BA_ "VNECUAllNodes" BU_ BSM_HS 4;
BA_ "VNECUSLHSSharedDiagnostic" BU_ BSM_HS 4;
BA_ "VNECUSLHS_VNReq" BU_ BSM_HS 4;
BA_ "SourceId" BU_ HCP_B_HS 23;
BA_ "ECU_Id" BU_ HCP_B_HS 225;
BA_ "VNECUAllNodes" BU_ HCP_B_HS 4;
BA_ "VNECUSLHSSharedDiagnostic" BU_ HCP_B_HS 4;
BA_ "VNECUSLHS_VNReq" BU_ HCP_B_HS 4;
BA_ "SourceId" BU_ AVM_HS 39;
BA_ "ECU_Id" BU_ AVM_HS 16;
BA_ "VNECUAllNodes" BU_ AVM_HS 4;
BA_ "VNECUSLHSSharedDiagnostic" BU_ AVM_HS 4;
BA_ "VNECUSLHS_VNReq" BU_ AVM_HS 4;
BA_ "SourceId" BU_ PFAF_HS 87;
BA_ "ECU_Id" BU_ PFAF_HS 12;
BA_ "VNECUAllNodes" BU_ PFAF_HS 4;
BA_ "VNECUSLHSSharedDiagnostic" BU_ PFAF_HS 4;
BA_ "VNECUSLHS_VNReq" BU_ PFAF_HS 4;
BA_ "VNECUAllNodes" BU_ LVMPC_HS 4;
BA_ "VNECUSLHSSharedDiagnostic" BU_ LVMPC_HS 4;
BA_ "VNECUSLHS_VNReq" BU_ LVMPC_HS 4;
BA_ "SourceId" BU_ DCDC_HS 204;
BA_ "ECU_Id" BU_ DCDC_HS 4;
BA_ "VNECUAllNodes" BU_ DCDC_HS 4;
BA_ "VNECUSLHSSharedDiagnostic" BU_ DCDC_HS 4;
BA_ "VNECUSLHS_VNReq" BU_ DCDC_HS 4;
BA_ "SourceId" BU_ DEFC_HS 20;
BA_ "ECU_Id" BU_ DEFC_HS 5;
BA_ "VNECUAllNodes" BU_ DEFC_HS 4;
BA_ "VNECUSLHSSharedDiagnostic" BU_ DEFC_HS 4;
BA_ "VNECUSLHS_VNReq" BU_ DEFC_HS 4;
BA_ "SourceId" BU_ VPM_HS 109;
BA_ "ECU_Id" BU_ VPM_HS 27;
BA_ "VNECUAllNodes" BU_ VPM_HS 4;
BA_ "VNECUSLHSSharedDiagnostic" BU_ VPM_HS 4;
BA_ "VNECUSLHS_VNReq" BU_ VPM_HS 4;
BA_ "SourceId" BU_ IPC_HS 96;
BA_ "ECU_Id" BU_ IPC_HS 30;
BA_ "VNECUAllNodes" BU_ IPC_HS 4;
BA_ "VNECUSLHSSharedDiagnostic" BU_ IPC_HS 4;
BA_ "VNECUSLHS_VNReq" BU_ IPC_HS 4;
BA_ "SourceId" BU_ V2V_HS 86;
BA_ "ECU_Id" BU_ V2V_HS 7;
BA_ "VNECUAllNodes" BU_ V2V_HS 4;
BA_ "VNECUSLHSSharedDiagnostic" BU_ V2V_HS 4;
BA_ "VNECUSLHS_VNReq" BU_ V2V_HS 4;
BA_ "SourceId" BU_ TCP_HS 151;
BA_ "ECU_Id" BU_ TCP_HS 13;
BA_ "VNECUAllNodes" BU_ TCP_HS 4;
BA_ "VNECUSLHSSharedDiagnostic" BU_ TCP_HS 4;
BA_ "VNECUSLHS_VNReq" BU_ TCP_HS 4;
BA_ "SourceId" BU_ CSM_HS 128;
BA_ "ECU_Id" BU_ CSM_HS 18;
BA_ "VNECUAllNodes" BU_ CSM_HS 4;
BA_ "VNECUSLHSSharedDiagnostic" BU_ CSM_HS 4;
BA_ "VNECUSLHS_VNReq" BU_ CSM_HS 4;
BA_ "SourceId" BU_ EOCM2B_K1_HS 100;
BA_ "ECU_Id" BU_ EOCM2B_K1_HS 12;
BA_ "VNECUAllNodes" BU_ EOCM2B_K1_HS 4;
BA_ "VNECUSLHSSharedDiagnostic" BU_ EOCM2B_K1_HS 4;
BA_ "VNECUSLHS_VNReq" BU_ EOCM2B_K1_HS 4;
BA_ "SourceId" BU_ EOCM2A_K1_HS 108;
BA_ "ECU_Id" BU_ EOCM2A_K1_HS 11;
BA_ "VNECUAllNodes" BU_ EOCM2A_K1_HS 4;
BA_ "VNECUSLHSSharedDiagnostic" BU_ EOCM2A_K1_HS 4;
BA_ "VNECUSLHS_VNReq" BU_ EOCM2A_K1_HS 4;
BA_ "SourceId" BU_ TRCM_HS 28;
BA_ "ECU_Id" BU_ TRCM_HS 21;
BA_ "VNECUAllNodes" BU_ TRCM_HS 4;
BA_ "VNECUSLHSSharedDiagnostic" BU_ TRCM_HS 4;
BA_ "VNECUSLHS_VNReq" BU_ TRCM_HS 4;
BA_ "SourceId" BU_ ESCM_SP_HS 68;
BA_ "ECU_Id" BU_ ESCM_SP_HS 29;
BA_ "VNECUAllNodes" BU_ ESCM_SP_HS 4;
BA_ "VNECUSLHSSharedDiagnostic" BU_ ESCM_SP_HS 4;
BA_ "VNECUSLHS_VNReq" BU_ ESCM_SP_HS 4;
BA_ "SourceId" BU_ ICCM_B_HS 37;
BA_ "ECU_Id" BU_ ICCM_B_HS 26;
BA_ "VNECUAllNodes" BU_ ICCM_B_HS 4;
BA_ "VNECUSLHSSharedDiagnostic" BU_ ICCM_B_HS 4;
BA_ "VNECUSLHS_VNReq" BU_ ICCM_B_HS 4;
BA_ "SourceId" BU_ AMP_HS 129;
BA_ "ECU_Id" BU_ AMP_HS 19;
BA_ "VNECUAllNodes" BU_ AMP_HS 4;
BA_ "VNECUSLHSSharedDiagnostic" BU_ AMP_HS 4;
BA_ "VNECUSLHS_VNReq" BU_ AMP_HS 4;
BA_ "SourceId" BU_ FICM_HS 19;
BA_ "ECU_Id" BU_ FICM_HS 230;
BA_ "VNECUAllNodes" BU_ FICM_HS 4;
BA_ "VNECUSLHSSharedDiagnostic" BU_ FICM_HS 4;
BA_ "VNECUSLHS_VNReq" BU_ FICM_HS 4;
BA_ "SourceId" BU_ ARS_HS 50;
BA_ "ECU_Id" BU_ ARS_HS 29;
BA_ "VNECUAllNodes" BU_ ARS_HS 4;
BA_ "VNECUSLHSSharedDiagnostic" BU_ ARS_HS 4;
BA_ "VNECUSLHS_VNReq" BU_ ARS_HS 4;
BA_ "SourceId" BU_ MCP_B_HS 30;
BA_ "ECU_Id" BU_ MCP_B_HS 24;
BA_ "VNECUAllNodes" BU_ MCP_B_HS 4;
BA_ "VNECUSLHSSharedDiagnostic" BU_ MCP_B_HS 4;
BA_ "VNECUSLHS_VNReq" BU_ MCP_B_HS 4;
BA_ "SourceId" BU_ MCP_A_HS 29;
BA_ "ECU_Id" BU_ MCP_A_HS 23;
BA_ "VNECUAllNodes" BU_ MCP_A_HS 4;
BA_ "VNECUSLHSSharedDiagnostic" BU_ MCP_A_HS 4;
BA_ "VNECUSLHS_VNReq" BU_ MCP_A_HS 4;
BA_ "SourceId" BU_ ICCM_OBD_HS 19;
BA_ "ECU_Id" BU_ ICCM_OBD_HS 227;
BA_ "VNECUAllNodes" BU_ ICCM_OBD_HS 4;
BA_ "VNECUSLHSSharedDiagnostic" BU_ ICCM_OBD_HS 4;
BA_ "VNECUSLHS_VNReq" BU_ ICCM_OBD_HS 4;
BA_ "SourceId" BU_ SAS_HS 52;
BA_ "ECU_Id" BU_ SAS_HS 10;
BA_ "VNECUAllNodes" BU_ SAS_HS 4;
BA_ "VNECUSLHSSharedDiagnostic" BU_ SAS_HS 4;
BA_ "VNECUSLHS_VNReq" BU_ SAS_HS 4;
BA_ "SourceId" BU_ ACCM_HS 156;
BA_ "ECU_Id" BU_ ACCM_HS 28;
BA_ "VNECUAllNodes" BU_ ACCM_HS 4;
BA_ "VNECUSLHSSharedDiagnostic" BU_ ACCM_HS 4;
BA_ "VNECUSLHS_VNReq" BU_ ACCM_HS 4;
BA_ "SourceId" BU_ VLBS_HS 144;
BA_ "ECU_Id" BU_ VLBS_HS 13;
BA_ "VNECUAllNodes" BU_ VLBS_HS 4;
BA_ "VNECUSLHSSharedDiagnostic" BU_ VLBS_HS 4;
BA_ "VNECUSLHS_VNReq" BU_ VLBS_HS 4;
BA_ "SourceId" BU_ EBCM_OBD_HS 40;
BA_ "ECU_Id" BU_ EBCM_OBD_HS 229;
BA_ "VNECUAllNodes" BU_ EBCM_OBD_HS 4;
BA_ "VNECUSLHSSharedDiagnostic" BU_ EBCM_OBD_HS 4;
BA_ "VNECUSLHS_VNReq" BU_ EBCM_OBD_HS 4;
BA_ "SourceId" BU_ HCP_T_HS 23;
BA_ "ECU_Id" BU_ HCP_T_HS 225;
BA_ "VNECUAllNodes" BU_ HCP_T_HS 4;
BA_ "VNECUSLHSSharedDiagnostic" BU_ HCP_T_HS 4;
BA_ "VNECUSLHS_VNReq" BU_ HCP_T_HS 4;
BA_ "VNECUAllNodes" BU_ EDI_HS 4;
BA_ "VNECUSLHSSharedDiagnostic" BU_ EDI_HS 4;
BA_ "VNECUSLHS_VNReq" BU_ EDI_HS 4;
BA_ "SourceId" BU_ PLCM_HS 200;
BA_ "ECU_Id" BU_ PLCM_HS 16;
BA_ "VNECUAllNodes" BU_ PLCM_HS 4;
BA_ "VNECUSLHSSharedDiagnostic" BU_ PLCM_HS 4;
BA_ "VNECUSLHS_VNReq" BU_ PLCM_HS 4;
BA_ "SourceId" BU_ VITM_OBD_HS 205;
BA_ "ECU_Id" BU_ VITM_OBD_HS 231;
BA_ "VNECUAllNodes" BU_ VITM_OBD_HS 4;
BA_ "VNECUSLHSSharedDiagnostic" BU_ VITM_OBD_HS 4;
BA_ "VNECUSLHS_VNReq" BU_ VITM_OBD_HS 4;
BA_ "SourceId" BU_ VICM_HS 203;
BA_ "ECU_Id" BU_ VICM_HS 228;
BA_ "VNECUAllNodes" BU_ VICM_HS 4;
BA_ "VNECUSLHSSharedDiagnostic" BU_ VICM_HS 4;
BA_ "VNECUSLHS_VNReq" BU_ VICM_HS 4;
BA_ "SourceId" BU_ HCP_HS 23;
BA_ "ECU_Id" BU_ HCP_HS 225;
BA_ "VNECUAllNodes" BU_ HCP_HS 4;
BA_ "VNECUSLHSSharedDiagnostic" BU_ HCP_HS 4;
BA_ "VNECUSLHS_VNReq" BU_ HCP_HS 4;
BA_ "SourceId" BU_ APPS_HS 93;
BA_ "ECU_Id" BU_ APPS_HS 6;
BA_ "VNECUAllNodes" BU_ APPS_HS 4;
BA_ "VNECUSLHSSharedDiagnostic" BU_ APPS_HS 4;
BA_ "VNECUSLHS_VNReq" BU_ APPS_HS 4;
BA_ "SourceId" BU_ ICCM_HS 34;
BA_ "ECU_Id" BU_ ICCM_HS 227;
BA_ "VNECUAllNodes" BU_ ICCM_HS 4;
BA_ "VNECUSLHSSharedDiagnostic" BU_ ICCM_HS 4;
BA_ "VNECUSLHS_VNReq" BU_ ICCM_HS 4;
BA_ "SourceId" BU_ EOCM_F_HS 108;
BA_ "ECU_Id" BU_ EOCM_F_HS 11;
BA_ "VNECUAllNodes" BU_ EOCM_F_HS 4;
BA_ "VNECUSLHSSharedDiagnostic" BU_ EOCM_F_HS 4;
BA_ "VNECUSLHS_VNReq" BU_ EOCM_F_HS 4;
BA_ "SourceId" BU_ GPCM_HS 22;
BA_ "ECU_Id" BU_ GPCM_HS 230;
BA_ "VNECUAllNodes" BU_ GPCM_HS 4;
BA_ "VNECUSLHSSharedDiagnostic" BU_ GPCM_HS 4;
BA_ "VNECUSLHS_VNReq" BU_ GPCM_HS 4;
BA_ "SourceId" BU_ VCM_HS 20;
BA_ "ECU_Id" BU_ VCM_HS 30;
BA_ "VNECUAllNodes" BU_ VCM_HS 4;
BA_ "VNECUSLHSSharedDiagnostic" BU_ VCM_HS 4;
BA_ "VNECUSLHS_VNReq" BU_ VCM_HS 4;
BA_ "SourceId" BU_ HMIM_HS 143;
BA_ "ECU_Id" BU_ HMIM_HS 18;
BA_ "VNECUAllNodes" BU_ HMIM_HS 4;
BA_ "VNECUSLHSSharedDiagnostic" BU_ HMIM_HS 4;
BA_ "VNECUSLHS_VNReq" BU_ HMIM_HS 4;
BA_ "SourceId" BU_ VES_HS 49;
BA_ "ECU_Id" BU_ VES_HS 2;
BA_ "VNECUAllNodes" BU_ VES_HS 4;
BA_ "VNECUSLHSSharedDiagnostic" BU_ VES_HS 4;
BA_ "VNECUSLHS_VNReq" BU_ VES_HS 4;
BA_ "VNECUAllNodes" BU_ Dummy_HS 4;
BA_ "VNECUSLHSSharedDiagnostic" BU_ Dummy_HS 4;
BA_ "SourceId" BU_ MCP_C_HS 31;
BA_ "ECU_Id" BU_ MCP_C_HS 25;
BA_ "VNECUAllNodes" BU_ MCP_C_HS 4;
BA_ "VNECUSLHSSharedDiagnostic" BU_ MCP_C_HS 4;
BA_ "VNECUSLHS_VNReq" BU_ MCP_C_HS 4;
BA_ "SourceId" BU_ ONSTAR_HS 151;
BA_ "ECU_Id" BU_ ONSTAR_HS 13;
BA_ "VNECUAllNodes" BU_ ONSTAR_HS 4;
BA_ "VNECUSLHSSharedDiagnostic" BU_ ONSTAR_HS 4;
BA_ "VNECUSLHS_VNReq" BU_ ONSTAR_HS 4;
BA_ "SourceId" BU_ EPS_HS 49;
BA_ "ECU_Id" BU_ EPS_HS 2;
BA_ "VNECUAllNodes" BU_ EPS_HS 4;
BA_ "VNECUSLHSSharedDiagnostic" BU_ EPS_HS 4;
BA_ "VNECUSLHS_VNReq" BU_ EPS_HS 4;
BA_ "SourceId" BU_ TestTool_HS 253;
BA_ "VNECUAllNodes" BU_ TestTool_HS 4;
BA_ "VNECUSLHSSharedDiagnostic" BU_ TestTool_HS 4;
BA_ "VNECUSLHS_VNReq" BU_ TestTool_HS 4;
BA_ "SourceId" BU_ MCP_HS 29;
BA_ "ECU_Id" BU_ MCP_HS 23;
BA_ "VNECUAllNodes" BU_ MCP_HS 4;
BA_ "VNECUSLHSSharedDiagnostic" BU_ MCP_HS 4;
BA_ "VNECUSLHS_VNReq" BU_ MCP_HS 4;
BA_ "SourceId" BU_ BCP_HS 23;
BA_ "ECU_Id" BU_ BCP_HS 225;
BA_ "VNECUAllNodes" BU_ BCP_HS 4;
BA_ "VNECUSLHSSharedDiagnostic" BU_ BCP_HS 4;
BA_ "VNECUSLHS_VNReq" BU_ BCP_HS 4;
BA_ "SourceId" BU_ ALC_HS 58;
BA_ "ECU_Id" BU_ ALC_HS 5;
BA_ "VNECUAllNodes" BU_ ALC_HS 4;
BA_ "VNECUSLHSSharedDiagnostic" BU_ ALC_HS 4;
BA_ "VNECUSLHS_VNReq" BU_ ALC_HS 4;
BA_ "SourceId" BU_ AHL_AFL_HS 114;
BA_ "ECU_Id" BU_ AHL_AFL_HS 9;
BA_ "VNECUAllNodes" BU_ AHL_AFL_HS 4;
BA_ "VNECUSLHSSharedDiagnostic" BU_ AHL_AFL_HS 4;
BA_ "VNECUSLHS_VNReq" BU_ AHL_AFL_HS 4;
BA_ "SourceId" BU_ SADS_HS 56;
BA_ "ECU_Id" BU_ SADS_HS 14;
BA_ "VNECUAllNodes" BU_ SADS_HS 4;
BA_ "VNECUSLHSSharedDiagnostic" BU_ SADS_HS 4;
BA_ "VNECUSLHS_VNReq" BU_ SADS_HS 4;
BA_ "SourceId" BU_ EPB_HS 43;
BA_ "ECU_Id" BU_ EPB_HS 20;
BA_ "VNECUAllNodes" BU_ EPB_HS 4;
BA_ "VNECUSLHSSharedDiagnostic" BU_ EPB_HS 4;
BA_ "VNECUSLHS_VNReq" BU_ EPB_HS 4;
BA_ "SourceId" BU_ FCM_HS 188;
BA_ "ECU_Id" BU_ FCM_HS 11;
BA_ "VNECUAllNodes" BU_ FCM_HS 4;
BA_ "VNECUSLHSSharedDiagnostic" BU_ FCM_HS 4;
BA_ "VNECUSLHS_VNReq" BU_ FCM_HS 4;
BA_ "SourceId" BU_ TCCM_HS 26;
BA_ "ECU_Id" BU_ TCCM_HS 22;
BA_ "VNECUAllNodes" BU_ TCCM_HS 4;
BA_ "VNECUSLHSSharedDiagnostic" BU_ TCCM_HS 4;
BA_ "VNECUSLHS_VNReq" BU_ TCCM_HS 4;
BA_ "SourceId" BU_ RDCM_HS 27;
BA_ "ECU_Id" BU_ RDCM_HS 15;
BA_ "VNECUAllNodes" BU_ RDCM_HS 4;
BA_ "VNECUSLHSSharedDiagnostic" BU_ RDCM_HS 4;
BA_ "VNECUSLHS_VNReq" BU_ RDCM_HS 4;
BA_ "SourceId" BU_ PTO_HS 25;
BA_ "ECU_Id" BU_ PTO_HS 7;
BA_ "VNECUAllNodes" BU_ PTO_HS 4;
BA_ "VNECUSLHSSharedDiagnostic" BU_ PTO_HS 4;
BA_ "VNECUSLHS_VNReq" BU_ PTO_HS 4;
BA_ "SourceId" BU_ EBCM_HS 40;
BA_ "ECU_Id" BU_ EBCM_HS 3;
BA_ "VNECUAllNodes" BU_ EBCM_HS 4;
BA_ "VNECUSLHSSharedDiagnostic" BU_ EBCM_HS 4;
BA_ "VNECUSLHS_VNReq" BU_ EBCM_HS 4;
BA_ "SourceId" BU_ ACC_HS 33;
BA_ "ECU_Id" BU_ ACC_HS 27;
BA_ "VNECUAllNodes" BU_ ACC_HS 4;
BA_ "VNECUSLHSSharedDiagnostic" BU_ ACC_HS 4;
BA_ "VNECUSLHS_VNReq" BU_ ACC_HS 4;
BA_ "SourceId" BU_ BCM_HS 64;
BA_ "ECU_Id" BU_ BCM_HS 1;
BA_ "VNECUAllNodes" BU_ BCM_HS 4;
BA_ "VNECUSLHSSharedDiagnostic" BU_ BCM_HS 4;
BA_ "VNECUSLHS_VNReq" BU_ BCM_HS 4;
BA_ "SourceId" BU_ TCM_HS 24;
BA_ "ECU_Id" BU_ TCM_HS 226;
BA_ "VNECUAllNodes" BU_ TCM_HS 4;
BA_ "VNECUSLHSSharedDiagnostic" BU_ TCM_HS 4;
BA_ "VNECUSLHS_VNReq" BU_ TCM_HS 4;
BA_ "SourceId" BU_ ECM_HS 17;
BA_ "ECU_Id" BU_ ECM_HS 224;
BA_ "VNECUAllNodes" BU_ ECM_HS 4;
BA_ "VNECUSLHSSharedDiagnostic" BU_ ECM_HS 4;
BA_ "VNECUSLHS_VNReq" BU_ ECM_HS 4;
